VERSION "Version"

NS_ :

BS_:

BU_: CCU IBCS IXCU RBM EPS ADC IBCS_IXCU IDU Tester CCURT2 RT2_C3 OTAWL ZCUF ZCUL ZCUR ZCUT IPS DCU NIDU RLBMS CBM WACUFL IDC IID VIU CCURT1 RT1_C0 RT1_C1 AVAS FLLCM FRLCM RLLCMA RRLCMA RLLCMB RRLCMB LBMS LBMSAD MFS FCP ITS BCB DCDC PCU EOP DCU2 BMS TMC SRS ECS CD AMP WHUD IMR FIMR FAPA FLR FRR RLR RRR IFC PAS INU SBM WCM ETC TBOX TBOX2 DSM FLPDM FRPDM RLPDM RRPDM HVSMR SCMRL SCMRR EBU EPB PCS V2XOBU EVCC VDC ADM PLGM FBLCM RLISD RRISD RCP RFR WCMFR SCMR TFOAR TROAR HVSPRL HVSPRR

BO_ 371 ADC_13_B: 64 ADC
 SG_ ADC_13_B_CRC : 7|16@0+ (1,0) [0|65535] ""  CCU,CCURT1,CCURT2,RT1_C1,VDC,EPS,IBCS,ECS,IXCU
 SG_ ADC_13_B_Counter : 23|8@0+ (1,0) [0|255] ""  CCU,CCURT1,CCURT2,RT1_C1,VDC,EPS,IBCS,ECS,IXCU
 SG_ ADC_DycEscTarTq : 63|16@0+ (1,-32768) [-32768|32767] "Nm"  IBCS,IXCU
 SG_ ADC_DycEscTarTqfactor : 79|8@0+ (0.01,0) [0|1] ""  IBCS,IXCU
 SG_ ADC_SteerTqReq : 87|12@0+ (0.01,-20) [-20|20] "Nm"  EPS
 SG_ ADC_SteerTqSt : 157|2@0+ (1,0) [0|3] ""  EPS
 SG_ ADC_SteerTqAvl : 153|1@0+ (1,0) [0|1] ""  EPS
 SG_ ADC_DycEscTarTqVld : 166|1@0+ (1,0) [0|1] ""  IBCS,IXCU
 SG_ ADC_DycEscTarTqEna : 167|1@0+ (1,0) [0|1] ""  IBCS,IXCU
 SG_ ADC_TotalRefTorque : 31|16@0+ (1,-32768) [-32768|32767] "Nm"  CCU,CCURT1,CCURT2,RT1_C1,VDC
 SG_ ADC_MotTarSpd : 47|16@0+ (1,-32768) [-32768|32767] "rpm"  CCU,CCURT1,CCURT2,RT1_C1,VDC
 SG_ ADC_LimTqFactorK : 91|10@0+ (0.001,0) [0|1] ""  CCU,CCURT1,CCURT2,RT1_C1,VDC
 SG_ ADC_MotTqLimMin : 97|9@0+ (25,-6375) [-6375|6400] "Nm"  CCU,CCURT1,CCURT2,RT1_C1,VDC
 SG_ ADC_MotTqLimMax : 104|9@0+ (25,-6375) [-6375|6400] "Nm"  CCU,CCURT1,CCURT2,RT1_C1,VDC
 SG_ ADC_MotTqRateLimMin : 127|9@0+ (50,-12750) [-12750|12800] "Nm/s"  CCU,CCURT1,CCURT2,RT1_C1,VDC
 SG_ ADC_MotTqRateLimMax : 134|9@0+ (50,-12750) [-12750|12800] "Nm/s"  CCU,CCURT1,CCURT2,RT1_C1,VDC
 SG_ ADC_TqUnloadRate : 141|9@0+ (50,-12750) [-12750|12800] "Nm/s"  CCU,CCURT1,CCURT2,RT1_C1,VDC
 SG_ ADC_MotCtrlTar : 148|3@0+ (1,0) [0|7] ""  CCU,CCURT1,CCURT2,RT1_C1,VDC
 SG_ ADC_MotTarMod : 145|2@0+ (1,0) [0|3] ""  CCU,CCURT1,CCURT2,RT1_C1,VDC
 SG_ ADC_DrvTarTqMod : 159|2@0+ (1,0) [0|3] ""  CCU,CCURT1,CCURT2,RT1_C1,VDC,EPB
 SG_ ADC_TqEvsSteerReq : 152|1@0+ (1,0) [0|1] ""  CCU,CCURT1,CCURT2,EPS
 SG_ ADC_RapidRespEna : 154|1@0+ (1,0) [0|1] ""  CCU,CCURT1,CCURT2,RT1_C1,VDC
 SG_ ADC_LimTqEnable : 155|1@0+ (1,0) [0|1] ""  CCU,CCURT1,CCURT2,RT1_C1,VDC
 SG_ ADC_MotSpdCtrlEna : 163|1@0+ (1,0) [0|1] ""  CCU,CCURT1,CCURT2,RT1_C1,VDC
 SG_ ADC_TqUnloadEna : 164|1@0+ (1,0) [0|1] ""  CCU,CCURT1,CCURT2,RT1_C1,VDC
 SG_ ADC_MotTarSpdSvValid : 165|1@0+ (1,0) [0|1] ""  CCU,CCURT1,CCURT2,RT1_C1,VDC
 SG_ ADC_RoadTyp : 162|3@0+ (1,0) [0|7] ""  CCU,CCURT1,CCURT2,EPS,ECS
 SG_ ADC_LeWhlLgtDst : 175|12@0+ (0.01,0) [0|30] "m"  CCU,CCURT1,CCURT2,EPS,ECS
 SG_ ADC_LeWhlRoadHei : 179|12@0+ (0.001,-0.5) [-0.5|0.523] "m"  CCU,CCURT1,CCURT2,EPS,ECS
 SG_ ADC_RiWhlLgtDst : 199|12@0+ (0.01,0) [0|30] "m"  CCU,CCURT1,CCURT2,EPS,ECS
 SG_ ADC_RiWhlRoadHei : 203|12@0+ (0.001,-0.5) [-0.5|0.523] "m"  CCU,CCURT1,CCURT2,EPS,ECS
 SG_ ADC_RiWhlRoadFeature : 223|5@0+ (1,0) [0|15] ""  CCU,CCURT1,CCURT2,EPS,ECS
 SG_ ADC_SuspensionStatus : 218|3@0+ (1,0) [0|7] ""  CCU,CCURT1,CCURT2,EPS,ECS
 SG_ ADC_LeWhlRoadSts : 231|2@0+ (1,0) [0|3] ""  CCU,CCURT1,CCURT2,EPS,ECS
 SG_ ADC_LeWhlRoadFeature : 229|4@0+ (1,0) [0|15] ""  CCU,CCURT1,CCURT2,EPS,ECS
 SG_ ADC_RiWhlRoadSts : 225|2@0+ (1,0) [0|3] ""  CCU,CCURT1,CCURT2,EPS,ECS
 SG_ ADC_CDCCtrlEnable : 239|1@0+ (1,0) [0|1] ""  CCU,CCURT1,CCURT2,EPS,ECS
 SG_ ADC_RoadInfoAvl : 238|1@0+ (1,0) [0|1] ""  CCU,CCURT1,CCURT2,EPS,ECS
 SG_ ADC_RoadFeatureDetFalutSts : 295|1@0+ (1,0) [0|1] ""  CCU,CCURT1,CCURT2
 SG_ ADC_RoadFeatureDetWorkSts : 247|2@0+ (1,0) [0|3] ""  CCU,CCURT1,CCURT2
 SG_ ADC_LeWhlRoadFeature2 : 251|4@0+ (1,0) [0|15] ""  CCU,CCURT1,CCURT2
 SG_ ADC_LeWhlRoadFeature3 : 255|4@0+ (1,0) [0|15] ""  CCU,CCURT1,CCURT2
 SG_ ADC_RiWhlRoadFeature2 : 259|4@0+ (1,0) [0|15] ""  CCU,CCURT1,CCURT2
 SG_ ADC_RiWhlRoadFeature3 : 263|4@0+ (1,0) [0|15] ""  CCU,CCURT1,CCURT2
 SG_ ADC_LeWhlRoadHei2 : 271|3@0+ (1,0) [0|7] ""  CCU,CCURT1,CCURT2
 SG_ ADC_LeWhlRoadHei3 : 268|3@0+ (1,0) [0|7] ""  CCU,CCURT1,CCURT2
 SG_ ADC_RiWhlRoadHei2 : 265|3@0+ (1,0) [0|7] ""  CCU,CCURT1,CCURT2
 SG_ ADC_RiWhlRoadHei3 : 278|3@0+ (1,0) [0|7] ""  CCU,CCURT1,CCURT2
 SG_ ADC_LeWhlLgtDst2 : 237|6@0+ (0.25,0) [0|15] "m"  CCU,CCURT1,CCURT2
 SG_ ADC_LeWhlLgtDst3 : 245|6@0+ (0.25,0) [0|15] "m"  CCU,CCURT1,CCURT2
 SG_ ADC_RiWhlLgtDst2 : 275|6@0+ (0.25,0) [0|15] "m"  CCU,CCURT1,CCURT2
 SG_ ADC_RiWhlLgtDst3 : 285|6@0+ (0.25,0) [0|15] "m"  CCU,CCURT1,CCURT2
 SG_ ADC_AS_SuspHeiAdj : 290|3@0+ (1,0) [0|7] ""  CCU,CCURT1,CCURT2
 SG_ ADC_AS_SuspHeiAdjVld : 291|1@0+ (1,0) [0|1] ""  CCU,CCURT1,CCURT2
 SG_ ADC_AS_SusStfnAdj : 300|3@0+ (1,0) [0|7] ""  CCU,CCURT1,CCURT2
 SG_ ADC_AS_SusStfnAdjVld : 292|1@0+ (1,0) [0|1] ""  CCU,CCURT1,CCURT2
 SG_ ADC_CDCModReq : 303|3@0+ (1,0) [0|7] ""  CCU,CCURT1,CCURT2
 SG_ ADC_CDCModReqVld : 294|1@0+ (1,0) [0|1] ""  CCU,CCURT1,CCURT2
 SG_ ADC_UrgentSteerFlg : 317|1@0+ (1,0) [0|1] ""  CCU
 SG_ ADC_OneMotorCtrlEna : 316|2@0+ (1,0) [0|3] ""  CCU
 SG_ ADC_MotorCtrlTqWhlRL : 327|16@0+ (1,-32768) [-32768|32767] "Nm"  CCU
 SG_ ADC_MotorCtrlTqWhlRR : 343|16@0+ (1,-32768) [-32768|32767] "Nm"  CCU
 SG_ ADC_SteerGainLevelTqCtrl : 359|8@0+ (1,0) [0|254] "%"  CCU,EPS
 SG_ ADC_MotorCtrlTqWhlFR : 383|16@0+ (1,-32768) [-32768|32767] "Nm"  CCU
 SG_ ADC_MotorCtrlTqWhlFL : 431|16@0+ (1,-32768) [-32768|32767] "Nm"  CCU

BO_ 422 VCU_1_B: 64 CCU
 SG_ VCU_1_B_CRC : 7|16@0+ (1,0) [0|65535] ""  ADC
 SG_ VCU_1_B_Counter : 23|8@0+ (1,0) [0|255] ""  ADC
 SG_ VCU_AccButtInfo_B : 31|8@0+ (1,0) [0|255] ""  ADC
 SG_ VCU_LateralAssistBtnInfo_B : 39|1@0+ (1,0) [0|1] ""  ADC
 SG_ VCU_LateralAssistBtnInfoVD_B : 38|1@0+ (1,0) [0|1] ""  ADC
 SG_ VCU_AccMasterCanError_B : 37|1@0+ (1,0) [0|1] ""  ADC
 SG_ VCU_IFCFailureSt_B : 36|1@0+ (1,0) [0|1] ""  ADC
 SG_ VCU_VehDrvMod_B : 35|3@0+ (1,0) [0|7] ""  ADC
 SG_ VCU_VehRdySt_B : 32|1@0+ (1,0) [0|1] ""  ADC
 SG_ VCU_GearLvl_B : 47|4@0+ (1,0) [0|15] ""  ADC
 SG_ VCU_RecpTorqVD_B : 43|1@0+ (1,0) [0|1] ""  ADC
 SG_ VCU_RecpTorq_B : 42|11@0+ (2,0) [0|4000] "Nm"  ADC
 SG_ VCU_BrkPedPst_B : 63|8@0+ (0.392,0) [0|99.96] "%"  ADC
 SG_ VCU_BrkPedPstVD_B : 71|1@0+ (1,0) [0|1] ""  ADC
 SG_ VCU_CrntGearLvlVD_B : 70|1@0+ (1,0) [0|1] ""  ADC
 SG_ VCU_CrntGearLvl_B : 69|3@0+ (1,0) [0|7] ""  ADC
 SG_ VCU_ACCLimitOperatingSt_B : 66|1@0+ (1,0) [0|1] ""  ADC
 SG_ VCU_ACCMaxRecpDecelVD_B : 65|1@0+ (1,0) [0|1] ""  ADC
 SG_ VCU_ACCMaxRecpDecel_B : 79|8@0+ (0.05,-5) [-5|7.75] "m/s2"  ADC
 SG_ VCU_ActVehWheelTorq_B : 87|14@0+ (1,0) [0|10000] "Nm"  ADC
 SG_ VCU_ACCmaxSpdLimit_B : 89|4@0+ (1,0) [0|15] ""  ADC
 SG_ VCU_VehWheelTorqMax_B : 101|14@0+ (1,0) [0|10000] "Nm"  ADC
 SG_ VCU_GasPedalActPstforMRRVD_B : 119|1@0+ (1,0) [0|1] ""  ADC
 SG_ VCU_AccElecECFail_B : 118|1@0+ (1,0) [0|1] ""  ADC
 SG_ VCU_AccDriverOrvd_B : 117|1@0+ (1,0) [0|1] ""  ADC
 SG_ VCU_APAAvailable_B : 116|1@0+ (1,0) [0|1] ""  ADC
 SG_ VCU_APA_Resp_B : 115|1@0+ (1,0) [0|1] ""  ADC
 SG_ VCU_GasPedalActPstforMRR_B : 127|8@0+ (0.392,0) [0|99.96] "%"  ADC
 SG_ VCU_AccPedalActPst_B : 135|8@0+ (0.392,0) [0|99.96] "%"  ADC
 SG_ VCU_BrkPedalSt_B : 143|1@0+ (1,0) [0|1] ""  ADC
 SG_ VCU_BrkPedalStVD_B : 142|1@0+ (1,0) [0|1] ""  ADC
 SG_ VCU_AccPedalActPstVD_B : 141|1@0+ (1,0) [0|1] ""  ADC
 SG_ VCU_AccTMCFail_B : 140|1@0+ (1,0) [0|1] ""  ADC

BO_ 619 CCU_EPB_2: 32 CCU
 SG_ EPB_FailSt_L : 39|1@0+ (1,0) [0|1] ""  ZCUT,RBM,IBCS,ADC,FAPA,VIU
 SG_ EPB_ExtAvailable_L : 47|2@0+ (1,0) [0|3] ""  ZCUT,RBM,IBCS,ADC,FAPA,VIU
 SG_ EPB_ActuatorSt_L : 107|4@0+ (1,0) [0|15] ""  ZCUT,RBM,IBCS,ADC,FAPA,VIU

BO_ 1174 ADC_BigData: 64 ADC
 SG_ ADC_BigData : 7|512@0+ (1,0) [0|1] ""  CCU

BO_ 728 CCU_ECS_1: 64 CCU
 SG_ ECS_1_CRC : 7|16@0+ (1,0) [0|65535] ""  ADC
 SG_ ECS_1_Counter : 23|8@0+ (1,0) [0|255] ""  ADC
 SG_ SDC_SolenoidErrorStRR : 31|2@0+ (1,0) [0|3] ""  ADC
 SG_ CDC_ADCCtrlAvl : 38|1@0+ (1,0) [0|1] ""  ADC
 SG_ CDC_ADCCtrlRespSts : 39|1@0+ (1,0) [0|1] ""  ADC
 SG_ SDC_ExternalReqMode : 43|3@0+ (1,0) [0|7] ""  ADC
 SG_ SDC_CurrentDamperMode : 258|3@0+ (1,0) [0|7] ""  ADC
 SG_ SDC_WarningLampReq : 259|1@0+ (1,0) [0|1] ""  ADC
 SG_ SDC_ProhibitChangingMode : 260|1@0+ (1,0) [0|1] ""  ADC
 SG_ SDC_BodyAccErrorStFL : 261|1@0+ (1,0) [0|1] ""  ADC
 SG_ SDC_BodyAccErrorStFR : 262|1@0+ (1,0) [0|1] ""  ADC
 SG_ SDC_BodyAccErrorStRr : 263|1@0+ (1,0) [0|1] ""  ADC
 SG_ SDC_WheelAccErrorStFL : 264|1@0+ (1,0) [0|1] ""  ADC
 SG_ SDC_WheelAccErrorStFR : 265|1@0+ (1,0) [0|1] ""  ADC
 SG_ SDC_SolenoidWorkSt : 267|2@0+ (1,0) [0|3] ""  ADC
 SG_ CDC_FailureSt : 279|8@0+ (1,0) [0|255] ""  ADC
 SG_ CDC_ADCModState : 287|3@0+ (1,0) [0|7] ""  ADC

BO_ 459 CCU_ECS_2: 64 CCU
 SG_ ECS_2_CRC : 7|16@0+ (1,0) [0|65535] ""  ADC,FAPA,IFC
 SG_ ECS_2_Counter : 23|8@0+ (1,0) [0|255] ""  ADC,FAPA,IFC
 SG_ AS_SuspHeightFL : 31|12@0+ (0.1,-150) [-150|150] "mm"  ADC,FAPA,IFC
 SG_ AS_SuspHeightFR : 35|12@0+ (0.1,-150) [-150|150] "mm"  ADC,FAPA,IFC
 SG_ AS_SuspHeightRL : 55|12@0+ (0.1,-150) [-150|150] "mm"  ADC,FAPA,IFC
 SG_ AS_SuspHeightRR : 59|12@0+ (0.1,-150) [-150|150] "mm"  ADC,FAPA,IFC
 SG_ AS_SuspHeightFLVD : 72|1@0+ (1,0) [0|1] ""  ADC,FAPA,IFC
 SG_ AS_SuspHeightFRVD : 73|1@0+ (1,0) [0|1] ""  ADC,FAPA,IFC
 SG_ AS_SuspHeightRLVD : 74|1@0+ (1,0) [0|1] ""  ADC,FAPA,IFC
 SG_ AS_SuspHeightRRVD : 75|1@0+ (1,0) [0|1] ""  ADC,FAPA,IFC
 SG_ AS_SuspHeightSensorFLSt : 76|1@0+ (1,0) [0|1] ""  ADC,FAPA,IFC
 SG_ AS_SuspHeightSensorFRSt : 77|1@0+ (1,0) [0|1] ""  ADC,FAPA,IFC
 SG_ AS_SuspHeightSensorRLSt : 78|1@0+ (1,0) [0|1] ""  ADC,FAPA,IFC
 SG_ AS_SuspHeightSensoRRSt : 79|1@0+ (1,0) [0|1] ""  ADC,FAPA,IFC
 SG_ AS_MaintanceModeSt : 97|2@0+ (1,0) [0|3] ""  ADC,FAPA,IFC
 SG_ ECS_AVDCReqModeAvailable : 113|1@0+ (1,0) [0|1] ""  ADC,FAPA,IFC
 SG_ ECS_AVDCReqMode : 116|3@0+ (1,0) [0|7] ""  ADC,FAPA,IFC
 SG_ AS_FrontAxleSuspSt : 112|2@0+ (1,0) [0|3] ""  ADC,FAPA,IFC
 SG_ AS_RearAxleSuspSt : 126|2@0+ (1,0) [0|3] ""  ADC,FAPA,IFC
 SG_ AS_HeightWarningSt : 124|3@0+ (1,0) [0|7] ""  ADC,FAPA,IFC
 SG_ AS_CurrentLevel : 131|4@0+ (1,0) [0|15] ""  ADC,FAPA,IFC
 SG_ AS_TargetLevel : 135|4@0+ (1,0) [0|15] ""  ADC,FAPA
 SG_ AS_ASMode : 138|3@0+ (1,0) [0|7] ""  ADC,FAPA,IFC
 SG_ AS_SysFaultSt : 141|3@0+ (1,0) [0|7] ""  ADC,FAPA,IFC
 SG_ AS_OverHeatingSt : 143|2@0+ (1,0) [0|3] ""  ADC,FAPA
 SG_ AS_SysOperationSt : 159|4@0+ (1,0) [0|15] ""  ADC,FAPA,IFC
 SG_ AS_OverLoadSt : 147|1@0+ (1,0) [0|1] ""  ADC,FAPA
 SG_ AS_OverTorsionSt : 148|1@0+ (1,0) [0|1] ""  ADC,FAPA
 SG_ AS_ManufacModeSt : 150|2@0+ (1,0) [0|3] ""  ADC,FAPA
 SG_ AS_ASIndividualMode : 155|3@0+ (1,0) [0|7] ""  ADC
 SG_ AS_ADCStfnCtrlAvl : 151|1@0+ (1,0) [0|1] ""  ADC,FAPA
 SG_ AS_ADCStfnState : 146|3@0+ (1,0) [0|7] ""  ADC,FAPA

BO_ 359 BCS_1_B: 64 IBCS_IXCU
 SG_ BCS_1_B_CRC : 7|16@0+ (1,0) [0|65535] ""  CCU,CCURT1,RT1_C1,VDC,EPS,EPB,ADC
 SG_ BCS_1_B_Counter : 23|8@0+ (1,0) [0|255] ""  CCU,CCURT1,RT1_C1,VDC,EPS,EPB,ADC
 SG_ BCS_FLWheelSpd_B : 31|13@0+ (0.05625,0) [0|240] "km/h"  EPS,EPB,ADC
 SG_ BCS_FLWheelSpdVD_B : 34|1@0+ (1,0) [0|1] ""  EPS,EPB,ADC
 SG_ BCS_FLWheelRotatedDirection_B : 33|1@0+ (1,0) [0|1] ""  EPB,ADC
 SG_ BCS_FLWheelRotatedDirectionVD_B : 32|1@0+ (1,0) [0|1] ""  EPB,ADC
 SG_ BCS_FRWheelSpd_B : 47|13@0+ (0.05625,0) [0|240] "km/h"  EPS,EPB,ADC
 SG_ BCS_FRWheelSpdVD_B : 50|1@0+ (1,0) [0|1] ""  EPS,EPB,ADC
 SG_ BCS_FRWheelRotatedDirection_B : 49|1@0+ (1,0) [0|1] ""  EPB,ADC
 SG_ BCS_FRWheelRotatedDirectionVD_B : 48|1@0+ (1,0) [0|1] ""  EPB,ADC
 SG_ BCS_RLWheelSpd_B : 63|13@0+ (0.05625,0) [0|240] "km/h"  EPS,EPB,ADC
 SG_ BCS_RLWheelSpdVD_B : 66|1@0+ (1,0) [0|1] ""  EPS,EPB,ADC
 SG_ BCS_RLWheelRotatedDirection_B : 65|1@0+ (1,0) [0|1] ""  EPB,ADC
 SG_ BCS_RLWheelRotatedDirectionVD_B : 64|1@0+ (1,0) [0|1] ""  EPB,ADC
 SG_ BCS_RRWheelSpd_B : 79|13@0+ (0.05625,0) [0|240] "km/h"  EPS,EPB,ADC
 SG_ BCS_RRWheelSpdVD_B : 82|1@0+ (1,0) [0|1] ""  EPS,EPB,ADC
 SG_ BCS_RRWheelRotatedDirection_B : 81|1@0+ (1,0) [0|1] ""  EPB,ADC
 SG_ BCS_RRWheelRotatedDirectionVD_B : 80|1@0+ (1,0) [0|1] ""  EPB,ADC
 SG_ BCS_HHCCtrlSt_B : 95|1@0+ (1,0) [0|1] ""  ADC
 SG_ BCS_HDCCtrlSt_B : 93|2@0+ (1,0) [0|3] ""  ADC
 SG_ BCS_HDCErrSt_B : 91|1@0+ (1,0) [0|1] ""  ADC
 SG_ BCS_FLWheelSpdEdgesSum_B : 103|12@0+ (1,0) [0|4095] ""  EPB,ADC
 SG_ BCS_FRWheelSpdEdgesSum_B : 107|12@0+ (1,0) [0|4095] ""  EPB,ADC
 SG_ BCS_RLWheelSpdEdgesSum_B : 127|12@0+ (1,0) [0|4095] ""  EPB,ADC
 SG_ BCS_RRWheelSpdEdgesSum_B : 131|12@0+ (1,0) [0|4095] ""  EPB,ADC
 SG_ BCS_FLWheelSpdEdgesSumVD_B : 151|1@0+ (1,0) [0|1] ""  EPB,ADC
 SG_ BCS_FRWheelSpdEdgesSumVD_B : 150|1@0+ (1,0) [0|1] ""  EPB,ADC
 SG_ BCS_RLWheelSpdEdgesSumVD_B : 149|1@0+ (1,0) [0|1] ""  EPB,ADC
 SG_ BCS_RRWheelSpdEdgesSumVD_B : 148|1@0+ (1,0) [0|1] ""  EPB,ADC
 SG_ BCS_FLWheelRotatedDirectionAPA_B : 147|2@0+ (1,0) [0|3] ""  EPB,ADC
 SG_ BCS_FRWheelRotatedDirectionAPA_B : 145|2@0+ (1,0) [0|3] ""  EPB,ADC
 SG_ BCS_RLWheelRotatedDirectionAPA_B : 159|2@0+ (1,0) [0|3] ""  EPB,ADC
 SG_ BCS_RRWheelRotatedDirectionAPA_B : 157|2@0+ (1,0) [0|3] ""  EPB,ADC
 SG_ BCS_ParkingReqToEPB_B : 155|2@0+ (1,0) [0|3] ""  EPB,ADC
 SG_ BCS_VDCOff_B : 153|1@0+ (1,0) [0|1] ""  ADC
 SG_ BCS_AVHSt_B : 152|1@0+ (1,0) [0|1] ""  EPB,ADC
 SG_ BCS_AVHAvailable_B : 166|1@0+ (1,0) [0|1] ""  EPB,ADC
 SG_ BCS_TCSOff_B : 165|1@0+ (1,0) [0|1] ""  ADC
 SG_ BCS_BrakeOverHeat_B : 160|1@0+ (1,0) [0|1] ""  ADC
 SG_ BCS_ABAactive_B : 175|1@0+ (1,0) [0|1] ""  ADC
 SG_ BCS_ABAavailable_B : 174|1@0+ (1,0) [0|1] ""  ADC
 SG_ BCS_ABPActive_B : 173|1@0+ (1,0) [0|1] ""  ADC
 SG_ BCS_ABPAvailable_B : 172|1@0+ (1,0) [0|1] ""  ADC
 SG_ BCS_AEBActive_B : 171|1@0+ (1,0) [0|1] ""  CCU,CCURT1,RT1_C1,VDC,ADC
 SG_ BCS_AEBAvailable_B : 170|1@0+ (1,0) [0|1] ""  ADC
 SG_ BCS_AWBActive_B : 169|1@0+ (1,0) [0|1] ""  ADC
 SG_ BCS_AWBAvailable_B : 168|1@0+ (1,0) [0|1] ""  ADC
 SG_ BCS_AVHStandby_B : 167|1@0+ (1,0) [0|1] ""  EPB,ADC
 SG_ BCS_AEBBAActive_B : 178|1@0+ (1,0) [0|1] ""  ADC
 SG_ BCS_VehicleStandStillSt_B : 180|2@0+ (1,0) [0|3] ""  EPB,ADC
 SG_ IPB_InputRodStroke_B : 363|10@0+ (0.05,-5) [-5|46.15] "mm"  ADC
 SG_ IPB_PlungerPressureSt_B : 376|1@0+ (1,0) [0|1] ""  EPB,ADC
 SG_ BCS_RAEBAvailable_B : 377|1@0+ (1,0) [0|1] ""  ADC
 SG_ BCS_RAEBActive_B : 378|1@0+ (1,0) [0|1] ""  ADC
 SG_ IPB_InputRodStrokeSt_B : 379|1@0+ (1,0) [0|1] ""  ADC
 SG_ IPB_PlungerPressure_B : 391|12@0+ (0.3,-5) [-5|301.9] "bar"  EPB,ADC

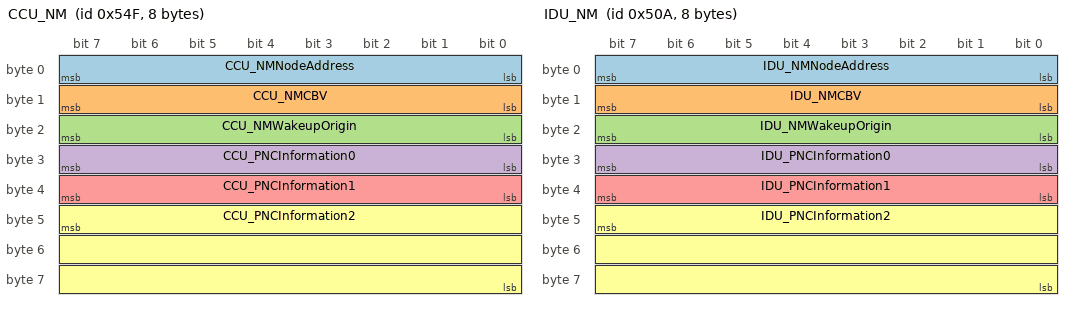
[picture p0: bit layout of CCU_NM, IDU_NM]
BO_ 1359 CCU_NM: 8 CCU
 SG_ CCU_NMNodeAddress : 7|8@0+ (1,0) [0|255] ""  ZCUF,ZCUL,ZCUR,ZCUT,ADM,LBMS,MFS,IDU,ITS,IPS,PCU,DCU,DCU2,NIDU,BMS,EVCC,TMC,RBM,IBCS,ECS,RLBMS,EPB,IXCU,WACUFL,IDC,IID,AMP,ADC,FAPA,VIU,IFC,TBOX,FLPDM,FRPDM,RLPDM,RRPDM,PLGM
 SG_ CCU_NMCBV : 15|8@0+ (1,0) [0|0] ""  ZCUF,ZCUL,ZCUR,ZCUT,ADM,LBMS,MFS,IDU,ITS,IPS,DCDC,PCU,DCU,DCU2,NIDU,BMS,EVCC,TMC,RBM,IBCS,ECS,RLBMS,EPB,IXCU,WACUFL,IDC,IID,AMP,ADC,FAPA,VIU,IFC,TBOX,FLPDM,FRPDM,RLPDM,RRPDM,PLGM
 SG_ CCU_NMWakeupOrigin : 23|8@0+ (1,0) [0|255] ""  ADM,LBMS,IDU,DCU2,TMC,IXCU,WACUFL,IID,AMP,ADC,FAPA,VIU,IFC,FLPDM,FRPDM,RLPDM,RRPDM,PLGM
 SG_ CCU_PNCInformation0 : 31|8@0+ (1,0) [0|255] ""  ZCUF,ZCUL,ZCUR,ZCUT,ADM,LBMS,MFS,IDU,ITS,IPS,DCDC,PCU,DCU,DCU2,NIDU,BMS,EVCC,TMC,RBM,IBCS,ECS,RLBMS,EPB,IXCU,WACUFL,IDC,IID,AMP,ADC,FAPA,VIU,IFC,TBOX,FLPDM,FRPDM,RLPDM,RRPDM,PLGM
 SG_ CCU_PNCInformation1 : 39|8@0+ (1,0) [0|0] ""  ZCUF,ZCUL,ZCUR,ZCUT,ADM,LBMS,MFS,IDU,ITS,IPS,PCU,DCU,DCU2,NIDU,BMS,EVCC,TMC,RBM,IBCS,ECS,RLBMS,EPB,IXCU,WACUFL,IDC,IID,AMP,ADC,FAPA,VIU,IFC,TBOX,FLPDM,FRPDM,RLPDM,RRPDM,PLGM
 SG_ CCU_PNCInformation2 : 47|24@0+ (1,0) [0|0] ""  ZCUF,ZCUL,ZCUR,ZCUT,ADM,LBMS,MFS,IDU,ITS,IPS,PCU,DCU,DCU2,NIDU,BMS,EVCC,TMC,RBM,IBCS,ECS,RLBMS,EPB,IXCU,WACUFL,IDC,IID,AMP,ADC,FAPA,VIU,IFC,TBOX,FLPDM,FRPDM,RLPDM,RRPDM,PLGM

BO_ 1290 IDU_NM: 8 IDU
 SG_ IDU_NMNodeAddress : 7|8@0+ (1,0) [0|255] ""  CCU,CCURT1,MFS,RBM,IBCS,ADC,VIU,HVSMR
 SG_ IDU_NMCBV : 15|8@0+ (1,0) [0|0] ""  CCU,CCURT1,MFS,RBM,IBCS,ADC,VIU,HVSMR
 SG_ IDU_NMWakeupOrigin : 23|8@0+ (1,0) [0|255] ""  CCU,CCURT1,MFS,RBM,IBCS,ADC,VIU,HVSMR
 SG_ IDU_PNCInformation0 : 31|8@0+ (1,0) [0|255] ""  CCU,CCURT1,MFS,RBM,IBCS,ADC,VIU,HVSMR
 SG_ IDU_PNCInformation1 : 39|8@0+ (1,0) [0|0] ""  CCU,CCURT1,MFS,RBM,IBCS,ADC,VIU,HVSMR
 SG_ IDU_PNCInformation2 : 47|24@0+ (1,0) [0|0] ""  CCU,CCURT1,MFS,RBM,IBCS,ADC,VIU,HVSMR

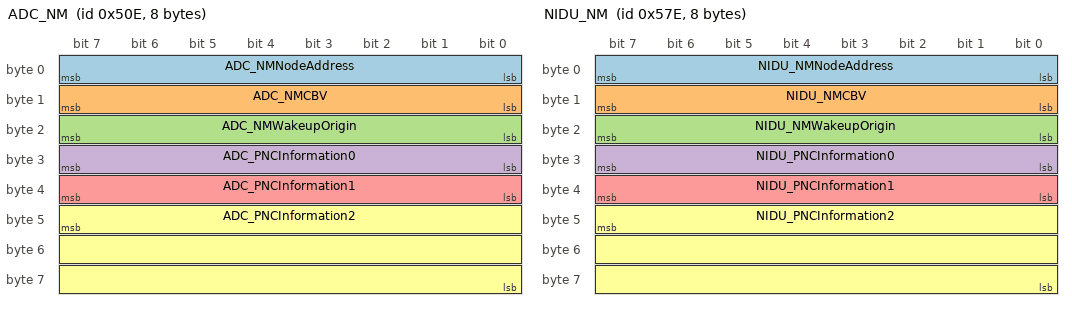
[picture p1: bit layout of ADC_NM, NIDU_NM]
BO_ 1294 ADC_NM: 8 ADC
 SG_ ADC_NMNodeAddress : 7|8@0+ (1,0) [0|255] ""  CCU,RBM,IBCS
 SG_ ADC_NMCBV : 15|8@0+ (1,0) [0|0] ""  CCU,RBM,IBCS
 SG_ ADC_NMWakeupOrigin : 23|8@0+ (1,0) [0|255] ""  CCU,RBM,IBCS
 SG_ ADC_PNCInformation0 : 31|8@0+ (1,0) [0|255] ""  CCU,RBM,IBCS
 SG_ ADC_PNCInformation1 : 39|8@0+ (1,0) [0|0] ""  CCU,RBM,IBCS
 SG_ ADC_PNCInformation2 : 47|24@0+ (1,0) [0|0] ""  CCU,RBM,IBCS

BO_ 1406 NIDU_NM: 8 IXCU
 SG_ NIDU_NMNodeAddress : 7|8@0+ (1,0) [0|255] ""  CCU,CCURT1,EPS,WACUFL,ADC
 SG_ NIDU_NMCBV : 15|8@0+ (1,0) [0|0] ""  CCU,CCURT1,EPS,WACUFL,ADC
 SG_ NIDU_NMWakeupOrigin : 23|8@0+ (1,0) [0|255] ""  CCU,CCURT1,EPS,WACUFL,ADC
 SG_ NIDU_PNCInformation0 : 31|8@0+ (1,0) [0|255] ""  CCU,CCURT1,EPS,WACUFL,ADC
 SG_ NIDU_PNCInformation1 : 39|8@0+ (1,0) [0|0] ""  CCU,CCURT1,EPS,WACUFL,ADC
 SG_ NIDU_PNCInformation2 : 47|24@0+ (1,0) [0|0] ""  CCU,CCURT1,EPS,WACUFL,ADC

BO_ 2015 Fun_Diag_Rx: 64 Tester
 SG_ Fun_Diag_Request : 7|512@0+ (1,0) [0|0] ""  ZCUF,ZCUL,ZCUR,ZCUT,AVAS,FBLCM,FLLCM,FRLCM,RLLCMA,RRLCMA,RLLCMB,RRLCMB,RLISD,RRISD,LBMS,LBMSAD,MFS,FCP,RCP,VDC,ITS,IPS,DCDC,PCU,EOP,DCU,DCU2,NIDU,BMS,EVCC,SRS,EPS,RBM,IBCS,EBU,RLBMS,EPB,IXCU,WACUFL,IDC,IID,CD,AMP,WHUD,IMR,FIMR,ADC,FAPA,VIU,IFC,PAS,PCS,INU,RFR,SBM,WCM,WCMFR,ETC,TBOX,TBOX2,DSM,FLPDM,FRPDM,RLPDM,RRPDM,SCMR,SCMRL,SCMRR,TFOAR,TROAR,HVSPRL,HVSPRR

CM_ SG_ 371 ADC_13_B_CRC "E2E Profile 5 CRC";
CM_ SG_ 371 ADC_13_B_Counter "E2E Profile 5 Counter";
CM_ SG_ 371 ADC_DycEscTarTq "The total target torque of the DYC(Direct  yaw moment control).";
CM_ SG_ 371 ADC_DycEscTarTqfactor "Partition coefficient of  total target torque of the DYC:front axle/total";
CM_ SG_ 371 ADC_SteerTqReq "Steering torque request value";
CM_ SG_ 371 ADC_SteerTqSt "Steering torque request  enable state";
CM_ SG_ 371 ADC_SteerTqAvl "Steering torque request avaliable state";
CM_ SG_ 371 ADC_DycEscTarTqVld "The validity of total target torque of the DYC.";
CM_ SG_ 371 ADC_DycEscTarTqEna "The enable status  of total target torque of the DYC.";
CM_ SG_ 371 ADC_TotalRefTorque "ADAS total  torque request";
CM_ SG_ 371 ADC_MotTarSpd "target motor speed";
CM_ SG_ 371 ADC_LimTqFactorK "Limit torque request factor";
CM_ SG_ 371 ADC_MotTqLimMin "Wheel torque lower limit";
CM_ SG_ 371 ADC_MotTqLimMax "Wheel torque upper limit";
CM_ SG_ 371 ADC_MotTqRateLimMin "Wheel torque rate lower limit";
CM_ SG_ 371 ADC_MotTqRateLimMax "Wheel torque rate upper limit";
CM_ SG_ 371 ADC_TqUnloadRate "Unload torque rate";
CM_ SG_ 371 ADC_MotCtrlTar "Target control motor";
CM_ SG_ 371 ADC_MotTarMod "Target motor working mode";
CM_ SG_ 371 ADC_DrvTarTqMod "Drive torque mode";
CM_ SG_ 371 ADC_TqEvsSteerReq "Emergency Collision avoidance steering mode request";
CM_ SG_ 371 ADC_RapidRespEna "Rapid response mode enable flag";
CM_ SG_ 371 ADC_LimTqEnable "Limit torque request enable flag";
CM_ SG_ 371 ADC_MotSpdCtrlEna "Speed mode control enable flag";
CM_ SG_ 371 ADC_TqUnloadEna "Unload torque request enable flag";
CM_ SG_ 371 ADC_MotTarSpdSvValid "Speed mode control validity";
CM_ SG_ 371 ADC_RoadTyp "Pavement condition type";
CM_ SG_ 371 ADC_LeWhlLgtDst "The distance from the projection point of the left front wheel center on the ground to the edge of the road feature area";
CM_ SG_ 371 ADC_LeWhlRoadHei "Left front wheel front feature road bump height (or dip depth)";
CM_ SG_ 371 ADC_RiWhlLgtDst "The distance from the projection point of the right front wheel center on the ground to the edge of the road feature area";
CM_ SG_ 371 ADC_RiWhlRoadHei "Right front wheel front feature road bump height (or dip depth)";
CM_ SG_ 371 ADC_RiWhlRoadFeature "Right wheel single road feature type";
CM_ SG_ 371 ADC_SuspensionStatus "ADS air suspension status request";
CM_ SG_ 371 ADC_LeWhlRoadSts "Left wheel pavement uneven (concave/convex) condition";
CM_ SG_ 371 ADC_LeWhlRoadFeature "Left-wheel single road feature type";
CM_ SG_ 371 ADC_RiWhlRoadSts "Uneven (concave/convex) condition of the right wheel pavement";
CM_ SG_ 371 ADC_CDCCtrlEnable "ADS Enable signal";
CM_ SG_ 371 ADC_RoadInfoAvl "Road information significance";
CM_ SG_ 371 ADC_RoadFeatureDetFalutSts "Road feature Dettion Fault Status";
CM_ SG_ 371 ADC_RoadFeatureDetWorkSts "Road feature Dettion Work Status";
CM_ SG_ 371 ADC_LeWhlRoadFeature2 "Left-wheel single road feature2 type";
CM_ SG_ 371 ADC_LeWhlRoadFeature3 "Left-wheel single road feature3 type";
CM_ SG_ 371 ADC_RiWhlRoadFeature2 "Right wheel single road feature2 type";
CM_ SG_ 371 ADC_RiWhlRoadFeature3 "Right wheel single road feature3 type";
CM_ SG_ 371 ADC_LeWhlRoadHei2 "Left front wheel front feature2 road bump height (or dip depth)";
CM_ SG_ 371 ADC_LeWhlRoadHei3 "Left front wheel front feature3 road bump height (or dip depth)";
CM_ SG_ 371 ADC_RiWhlRoadHei2 "Right front wheel front feature2 road bump height (or dip depth)";
CM_ SG_ 371 ADC_RiWhlRoadHei3 "Right front wheel front feature3 road bump height (or dip depth)";
CM_ SG_ 371 ADC_LeWhlLgtDst2 "The distance from the projection point of the left front wheel center on the ground to the edge of the road feature2 area";
CM_ SG_ 371 ADC_LeWhlLgtDst3 "The distance from the projection point of the left front wheel center on the ground to the edge of the road feature3 area";
CM_ SG_ 371 ADC_RiWhlLgtDst2 "The distance from the projection point of the right front wheel center on the ground to the edge of the road feature2 area";
CM_ SG_ 371 ADC_RiWhlLgtDst3 "The distance from the projection point of the right front wheel center on the ground to the edge of the road feature3 area";
CM_ SG_ 371 ADC_AS_SuspHeiAdj "Request suspension adjustment control signal";
CM_ SG_ 371 ADC_AS_SuspHeiAdjVld "Request?suspension?adjustment?control?significant?signal";
CM_ SG_ 371 ADC_AS_SusStfnAdj "Request suspension stiffness adjustment control signal";
CM_ SG_ 371 ADC_AS_SusStfnAdjVld "Request suspension stiffness adjustment to control the significant signal";
CM_ SG_ 371 ADC_CDCModReq "Request?shock?absorber?damper?adjustment?control?signal";
CM_ SG_ 371 ADC_CDCModReqVld "Request damper damper regulation control significant signal";
CM_ SG_ 371 ADC_UrgentSteerFlg "Urgent Steering Flag of ADC";
CM_ SG_ 371 ADC_OneMotorCtrlEna "Motor Direct Control Enable Flag";
CM_ SG_ 371 ADC_MotorCtrlTqWhlRL "Target Drive Torque for Rear Left Motor";
CM_ SG_ 371 ADC_MotorCtrlTqWhlRR "Target Drive Torque for Rear Right Motor";
CM_ SG_ 371 ADC_SteerGainLevelTqCtrl "Driver steering torque gain request value";
CM_ SG_ 371 ADC_MotorCtrlTqWhlFR "Target Drive Torque for Front Right Motor";
CM_ SG_ 371 ADC_MotorCtrlTqWhlFL "Target Drive Torque for Front Left Motor";
CM_ SG_ 422 VCU_1_B_CRC "E2E Profile 5 CRC";
CM_ SG_ 422 VCU_1_B_Counter "E2E Profile 5 Counter";
CM_ SG_ 422 VCU_AccButtInfo_B "ACC Button Information";
CM_ SG_ 422 VCU_LateralAssistBtnInfo_B "VCU_LateralAssistBtnInfo";
CM_ SG_ 422 VCU_LateralAssistBtnInfoVD_B "Lateral assist button Information valid data";
CM_ SG_ 422 VCU_AccMasterCanError_B "ACC Master CAN Error";
CM_ SG_ 422 VCU_IFCFailureSt_B "IFC Failure Status";
CM_ SG_ 422 VCU_VehDrvMod_B "Drive?mode?for?display";
CM_ SG_ 422 VCU_VehRdySt_B "HEV?system?ready?status";
CM_ SG_ 422 VCU_GearLvl_B "Gear?lever?for?PEPS";
CM_ SG_ 422 VCU_RecpTorqVD_B "Status?of?recuperation?torque?of?generator ";
CM_ SG_ 422 VCU_RecpTorq_B "Current?recuperation?torque?of?generator";
CM_ SG_ 422 VCU_BrkPedPst_B "Current?brake?pedal?position";
CM_ SG_ 422 VCU_BrkPedPstVD_B "Current?brake?pedal?position?valid?data";
CM_ SG_ 422 VCU_CrntGearLvlVD_B "Valid?bit?for?ActualGearPosition.";
CM_ SG_ 422 VCU_CrntGearLvl_B "VCU?current?carry?out?gear?level";
CM_ SG_ 422 VCU_ACCLimitOperatingSt_B "peration status of ACC Limit mode, When VCU Enter the power-saving mode";
CM_ SG_ 422 VCU_ACCMaxRecpDecelVD_B "VCU_ACCMaxRecpDecel valid validity";
CM_ SG_ 422 VCU_ACCMaxRecpDecel_B "Current?maximum?recuperation?deceleration?of generator";
CM_ SG_ 422 VCU_ActVehWheelTorq_B "Actual effective engine torque on wheel level";
CM_ SG_ 422 VCU_ACCmaxSpdLimit_B "When VCU Enter the power-saving mode，the maximum ACC target speed limited by VCU";
CM_ SG_ 422 VCU_VehWheelTorqMax_B "Actual effective maximum adjustable torque on wheel level";
CM_ SG_ 422 VCU_GasPedalActPstforMRRVD_B "VCU GasPedalActPstforMRR Valid Data";
CM_ SG_ 422 VCU_AccElecECFail_B "Indicate the error state of electronic engine control.";
CM_ SG_ 422 VCU_AccDriverOrvd_B "Indicating the torque demanded by the driver is higher than the torque demanded by ACC.";
CM_ SG_ 422 VCU_APAAvailable_B "Whether VCU is available for APA function";
CM_ SG_ 422 VCU_APA_Resp_B "VCU response to APA if VCU is response the gear shif and torque request";
CM_ SG_ 422 VCU_GasPedalActPstforMRR_B "Current Actual accelerate pedal position.";
CM_ SG_ 422 VCU_AccPedalActPst_B "Current Actual or Virtual accelerate pedal position.";
CM_ SG_ 422 VCU_BrkPedalSt_B "Brake pedal status";
CM_ SG_ 422 VCU_BrkPedalStVD_B "BrakePedSt valid data";
CM_ SG_ 422 VCU_AccPedalActPstVD_B "VCU_AccPedalActPst Valid Data.";
CM_ SG_ 422 VCU_AccTMCFail_B "Indicating VCU in limp-home (error) mode";
CM_ SG_ 619 EPB_FailSt_L "EPB fail status,to indicate wether EPB can response to external apply  request or not";
CM_ SG_ 619 EPB_ExtAvailable_L "EPB  status,to indicate wetherEPB can response to externalapply request or not";
CM_ SG_ 619 EPB_ActuatorSt_L "EPB left  actuator status";
CM_ SG_ 728 ECS_1_CRC "E2E Profile 5 CRC";
CM_ SG_ 728 ECS_1_Counter "E2E Profile 5 Counter";
CM_ SG_ 728 SDC_SolenoidErrorStRR "Error status of RR solenoid";
CM_ SG_ 728 CDC_ADCCtrlAvl "CDC control available signal";
CM_ SG_ 728 CDC_ADCCtrlRespSts "CDC control response signal";
CM_ SG_ 728 SDC_ExternalReqMode "SDC internal mode for  external request";
CM_ SG_ 728 SDC_CurrentDamperMode "SDC current damper mode";
CM_ SG_ 728 SDC_WarningLampReq "SDC warning lamp requirement";
CM_ SG_ 728 SDC_ProhibitChangingMode "SDC mode change is prohibited";
CM_ SG_ 728 SDC_BodyAccErrorStFL "Error status of FL body sensor";
CM_ SG_ 728 SDC_BodyAccErrorStFR "Error status of FR body sensor";
CM_ SG_ 728 SDC_BodyAccErrorStRr "Error status of Rear body sensor";
CM_ SG_ 728 SDC_WheelAccErrorStFL "Error status of FL wheel sensor";
CM_ SG_ 728 SDC_WheelAccErrorStFR "Error status of FR wheel sensor";
CM_ SG_ 728 SDC_SolenoidWorkSt "SDC slolenoid working status";
CM_ SG_ 728 CDC_FailureSt "Electronic control suspension failure status:Bit 0 : Level S1- 0x00 = No Failure- 0x01 = FalureBit 1 : Level S2- 0x00 = No Failure- 0x01 = FalureBit 2 : Level S3- 0x00 = No Failure- 0x01 = FalureBit 3 : Level S4- 0x00 = No Failure- 0x01 = FalureBit 4 : Level O1- 0x00 = No Failure- 0x01 = FalureBit 5 : Level O2- 0x00 = No Failure- 0x01 = FalureBit 6 : Level O3- 0x00 = No Failure- 0x01 = FalureBit 7 : Level O4- 0x00 = No Failure- 0x01 = Falure";
CM_ SG_ 728 CDC_ADCModState "CDC current damped state feedback";
CM_ SG_ 459 ECS_2_CRC "E2E Profile 5 CRC";
CM_ SG_ 459 ECS_2_Counter "E2E Profile 5 Counter";
CM_ SG_ 459 AS_SuspHeightFL "Height of front left wheel";
CM_ SG_ 459 AS_SuspHeightFR "Height of front right wheel";
CM_ SG_ 459 AS_SuspHeightRL "Height of rear left wheel";
CM_ SG_ 459 AS_SuspHeightRR "Height of rear right wheel";
CM_ SG_ 459 AS_SuspHeightFLVD "Height of front left wheel validity";
CM_ SG_ 459 AS_SuspHeightFRVD "Height of front right wheel validity";
CM_ SG_ 459 AS_SuspHeightRLVD "Height of rear left wheel validity";
CM_ SG_ 459 AS_SuspHeightRRVD "Height of rear right wheel validity";
CM_ SG_ 459 AS_SuspHeightSensorFLSt "Front left suspension height sensor fault status";
CM_ SG_ 459 AS_SuspHeightSensorFRSt "Front right suspension height sensor fault status";
CM_ SG_ 459 AS_SuspHeightSensorRLSt "Rear left suspension height sensor fault status";
CM_ SG_ 459 AS_SuspHeightSensoRRSt "Rear right suspension height sensor fault status";
CM_ SG_ 459 AS_MaintanceModeSt "Air spring maintance mode status";
CM_ SG_ 459 ECS_AVDCReqMode "Electronic control suspension internal mode for AVDC电子控制悬架AVDC执行状态";
CM_ SG_ 459 AS_FrontAxleSuspSt "Height adjustment of the front axle";
CM_ SG_ 459 AS_RearAxleSuspSt "Height adjustment status of rear axle";
CM_ SG_ 459 AS_HeightWarningSt "Vehicle height warning";
CM_ SG_ 459 AS_CurrentLevel "Vehicle current height level";
CM_ SG_ 459 AS_TargetLevel "Vehicle target height level";
CM_ SG_ 459 AS_ASMode "Air spring opreation mode";
CM_ SG_ 459 AS_SysFaultSt "Air Spring system fault";
CM_ SG_ 459 AS_OverHeatingSt "Pump overheating status";
CM_ SG_ 459 AS_SysOperationSt "Air Spring operation status";
CM_ SG_ 459 AS_OverLoadSt "Vehicle overload status";
CM_ SG_ 459 AS_OverTorsionSt "Vehicle over torsion parking status";
CM_ SG_ 459 AS_ManufacModeSt "Air spring Manufac mode status";
CM_ SG_ 459 AS_ASIndividualMode "Air spring Individual opreation mode";
CM_ SG_ 459 AS_ADCStfnCtrlAvl "Available signals for suspension stiffness control";
CM_ SG_ 459 AS_ADCStfnState "Suspension stiffness state feedback signal";
CM_ SG_ 359 BCS_1_B_CRC "E2E Profile 5 CRC";
CM_ SG_ 359 BCS_1_B_Counter "E2E Profile 5 Counter";
CM_ SG_ 359 BCS_FLWheelSpd_B "Current wheel speed information of front left wheel";
CM_ SG_ 359 BCS_FLWheelSpdVD_B "Quality/fault information to current wheel speed of front left wheel";
CM_ SG_ 359 BCS_FLWheelRotatedDirection_B "FL wheel rotate direction";
CM_ SG_ 359 BCS_FLWheelRotatedDirectionVD_B "FL wheel rotate direction validity";
CM_ SG_ 359 BCS_FRWheelSpd_B "Current wheel speed information of front right wheel";
CM_ SG_ 359 BCS_FRWheelSpdVD_B "Quality/fault information to current wheel speed of front right  wheel";
CM_ SG_ 359 BCS_FRWheelRotatedDirection_B "FR wheel rotate direction";
CM_ SG_ 359 BCS_FRWheelRotatedDirectionVD_B "FR wheel rotate direction validity";
CM_ SG_ 359 BCS_RLWheelSpd_B "Current wheel speed information of rear left wheel";
CM_ SG_ 359 BCS_RLWheelSpdVD_B "Quality/fault information to current wheel speed of rear left wheel";
CM_ SG_ 359 BCS_RLWheelRotatedDirection_B "RL wheel rotate direction";
CM_ SG_ 359 BCS_RLWheelRotatedDirectionVD_B "RL wheel rotate direction validity";
CM_ SG_ 359 BCS_RRWheelSpd_B "Current wheel speed information of rear right wheel";
CM_ SG_ 359 BCS_RRWheelSpdVD_B "Quality/fault information to current wheel speed of rear right wheel";
CM_ SG_ 359 BCS_RRWheelRotatedDirection_B "RR wheel rotate direction";
CM_ SG_ 359 BCS_RRWheelRotatedDirectionVD_B "RR wheel rotate direction validity";
CM_ SG_ 359 BCS_HHCCtrlSt_B "HHC(Hill Hold Control) control status";
CM_ SG_ 359 BCS_HDCCtrlSt_B "HDC(Hill Descent Control) control status";
CM_ SG_ 359 BCS_HDCErrSt_B "HDC error status";
CM_ SG_ 359 BCS_FLWheelSpdEdgesSum_B "Accumulated sum of rising and falling edges of front left wheel speed sensor output·since IGN ON( the wheel plate have 48 teeth/cycle,the edge is 96)";
CM_ SG_ 359 BCS_FRWheelSpdEdgesSum_B "Accumulated sum of rising and falling edges of front right wheel speed sensor output·since IGN ON( the wheel plate have 48 teeth/cycle,the edge is 96)";
CM_ SG_ 359 BCS_RLWheelSpdEdgesSum_B "Accumulated sum of rising and falling edges of rear left wheel speed sensor output·since IGN ON( the wheel plate have 48 teeth/cycle,the edge is 96)";
CM_ SG_ 359 BCS_RRWheelSpdEdgesSum_B "Accumulated sum of rising and falling edges of  rear right wheel speed sensor output·since IGN ON( the wheel plate have 48 teeth/cycle,the edge is 96)";
CM_ SG_ 359 BCS_FLWheelSpdEdgesSumVD_B "Quality/fault information to current wheel speed edges sum of front left wheel";
CM_ SG_ 359 BCS_FRWheelSpdEdgesSumVD_B "Quality/fault information to current wheel speed edges sum of front right wheel";
CM_ SG_ 359 BCS_RLWheelSpdEdgesSumVD_B "Quality/fault information to current wheel speed edges sum of rear left wheel";
CM_ SG_ 359 BCS_RRWheelSpdEdgesSumVD_B "Quality/fault information to current wheel speed edges sum of rear right wheel";
CM_ SG_ 359 BCS_FLWheelRotatedDirectionAPA_B "FL wheel rotate direction for APA";
CM_ SG_ 359 BCS_FRWheelRotatedDirectionAPA_B "FR wheel rotate direction for APA";
CM_ SG_ 359 BCS_RLWheelRotatedDirectionAPA_B "RL wheel rotate direction for APA";
CM_ SG_ 359 BCS_RRWheelRotatedDirectionAPA_B "RR wheel rotate direction for APA";
CM_ SG_ 359 BCS_ParkingReqToEPB_B "Indicates the release/lock brake request to EPB";
CM_ SG_ 359 BCS_VDCOff_B "VDC is switched off ";
CM_ SG_ 359 BCS_AVHSt_B "Indicates AVH(Auto Vehicle Hold)in active or not ";
CM_ SG_ 359 BCS_AVHAvailable_B "HMI responsible, can get degrate AVH(Auto Vehicle Hold) statement from DSW and send out ";
CM_ SG_ 359 BCS_TCSOff_B "TCS is switched off ";
CM_ SG_ 359 BCS_BrakeOverHeat_B "Indicating brake temperature too high or not";
CM_ SG_ 359 BCS_ABAactive_B "ABA(Adaptive Brake Assistance) is active";
CM_ SG_ 359 BCS_ABAavailable_B "The ABA(Adaptive Brake Assistance)  function is available";
CM_ SG_ 359 BCS_ABPActive_B "ABP(Automatic brake Pre-fill) is active";
CM_ SG_ 359 BCS_ABPAvailable_B "ABP(Automatic brake Pre-fill) is available";
CM_ SG_ 359 BCS_AEBActive_B "AEB(Automatic EmergencyBraking) is active (in deceleration)";
CM_ SG_ 359 BCS_AEBAvailable_B "AEB(Automatic EmergencyBraking) is available";
CM_ SG_ 359 BCS_AWBActive_B "AWB(Automatic Warning Brake) is active";
CM_ SG_ 359 BCS_AWBAvailable_B "AWB(Automatic Warning Brake) is available";
CM_ SG_ 359 BCS_AVHStandby_B "Indicates AVH(Auto Vehicle Hold)in standby mode or not ";
CM_ SG_ 359 BCS_AEBBAActive_B "Indicates AEBBA active or not";
CM_ SG_ 359 BCS_VehicleStandStillSt_B "Indicating whether the vehicle is standstill or not;must not be set until standstill is surely reached.";
CM_ SG_ 359 IPB_InputRodStroke_B "Indicate inputRod stroke value";
CM_ SG_ 359 IPB_PlungerPressureSt_B "Indicate plunger pressure status";
CM_ SG_ 359 BCS_RAEBAvailable_B "RAEB is available ";
CM_ SG_ 359 BCS_RAEBActive_B "RAEB is active ";
CM_ SG_ 359 IPB_InputRodStrokeSt_B "Indicate inputRod stroke status";
CM_ SG_ 359 IPB_PlungerPressure_B "Indicate plunger pressure value";
CM_ SG_ 1359 CCU_NMNodeAddress "CCU node address";
CM_ SG_ 1359 CCU_NMCBV "CCU Network management  control bit vector";
CM_ SG_ 1359 CCU_NMWakeupOrigin "Origin of the wake up";
CM_ SG_ 1359 CCU_PNCInformation0 "PNC Information";
CM_ SG_ 1359 CCU_PNCInformation1 "PNC Information";
CM_ SG_ 1359 CCU_PNCInformation2 "PNC Information";
CM_ SG_ 1290 IDU_NMNodeAddress "IDU node address";
CM_ SG_ 1290 IDU_NMCBV "IDU Network management data";
CM_ SG_ 1290 IDU_NMWakeupOrigin "Origin of the wake up";
CM_ SG_ 1290 IDU_PNCInformation0 "PNC Information";
CM_ SG_ 1290 IDU_PNCInformation1 "PNC Information";
CM_ SG_ 1290 IDU_PNCInformation2 "PNC Information";
CM_ SG_ 1294 ADC_NMNodeAddress "ADC node address";
CM_ SG_ 1294 ADC_NMCBV "ADC Network management  control bit vector";
CM_ SG_ 1294 ADC_NMWakeupOrigin "Origin of the wake up";
CM_ SG_ 1294 ADC_PNCInformation0 "PNC Information";
CM_ SG_ 1294 ADC_PNCInformation1 "PNC Information";
CM_ SG_ 1294 ADC_PNCInformation2 "PNC Information";
CM_ SG_ 1406 NIDU_NMNodeAddress "NIDU node address";
CM_ SG_ 1406 NIDU_NMCBV "NIDU Network management control bit vector";
CM_ SG_ 1406 NIDU_NMWakeupOrigin "Origin of the wake up";
CM_ SG_ 1406 NIDU_PNCInformation0 "PNC Information";
CM_ SG_ 1406 NIDU_PNCInformation1 "PNC Information";
CM_ SG_ 1406 NIDU_PNCInformation2 "PNC Information";
CM_ SG_ 2015 Fun_Diag_Request "Diagnostic function request";

BA_DEF_ BO_  "GenMsgCycleTime" INT 0 0;
BA_DEF_ BO_  "GenMsgCycleTimeFast" INT 0 0;
BA_DEF_ BO_  "GenMsgSendType" ENUM  "Periodic","Event","IfActive","POE","PA","FixedPeriodic","Event","EnabledPeriodic","NotUsed","NotUsed","EventPeriodic","NotUsed","NotUsed","NoMsgSendType";
BA_DEF_ BO_  "VFrameFormat" ENUM  "StandardCAN","ExtendedCAN","reserved","reserved","reserved","reserved","reserved","reserved","reserved","reserved","reserved","reserved","reserved","reserved","StandardCAN_FD","ExtendedCAN_FD";
BA_DEF_ BO_  "CANFD_BRS" ENUM  "0","1";
BA_DEF_ SG_  "EventCommandSignal" ENUM  "No","Yes";
BA_DEF_ SG_  "GatewayedSignals" ENUM  "No","Yes";
BA_DEF_ SG_  "GenSigInactiveValue" HEX 0 0;
BA_DEF_ SG_  "GenSigInvalidValue" HEX 0 0;
BA_DEF_ SG_  "GenSigSendType" ENUM  "Trigger","Passive","Cyclic","OnWrite","OnWriteWithRepetition","OnChange","OnChangeWithRepetition","IfActive","IfActiveWithRepetition","NoSigSendType";
BA_DEF_ SG_  "GenSigStartValue" HEX 0 0;
BA_DEF_ SG_  "GenSigTimeoutValue" HEX 0 0;
BA_DEF_ SG_  "Remark" STRING ;
BA_ "GenMsgCycleTime" BO_ 371 10;
BA_ "GenMsgCycleTimeFast" BO_ 371 0;
BA_ "GenMsgSendType" BO_ 371 0;
BA_ "VFrameFormat" BO_ 371 14;
BA_ "CANFD_BRS" BO_ 371 1;
BA_ "GenMsgCycleTime" BO_ 371 10;
BA_ "GenMsgCycleTimeFast" BO_ 371 0;
BA_ "GenMsgSendType" BO_ 371 0;
BA_ "VFrameFormat" BO_ 371 14;
BA_ "CANFD_BRS" BO_ 371 1;
BA_ "GenMsgCycleTime" BO_ 371 10;
BA_ "GenMsgCycleTimeFast" BO_ 371 0;
BA_ "GenMsgSendType" BO_ 371 0;
BA_ "VFrameFormat" BO_ 371 14;
BA_ "CANFD_BRS" BO_ 371 1;
BA_ "GenMsgCycleTime" BO_ 371 10;
BA_ "GenMsgCycleTimeFast" BO_ 371 0;
BA_ "GenMsgSendType" BO_ 371 0;
BA_ "VFrameFormat" BO_ 371 14;
BA_ "CANFD_BRS" BO_ 371 1;
BA_ "GenMsgCycleTime" BO_ 371 10;
BA_ "GenMsgCycleTimeFast" BO_ 371 0;
BA_ "GenMsgSendType" BO_ 371 0;
BA_ "VFrameFormat" BO_ 371 14;
BA_ "CANFD_BRS" BO_ 371 1;
BA_ "GenMsgCycleTime" BO_ 371 10;
BA_ "GenMsgCycleTimeFast" BO_ 371 0;
BA_ "GenMsgSendType" BO_ 371 0;
BA_ "VFrameFormat" BO_ 371 14;
BA_ "CANFD_BRS" BO_ 371 1;
BA_ "GenMsgCycleTime" BO_ 371 10;
BA_ "GenMsgCycleTimeFast" BO_ 371 0;
BA_ "GenMsgSendType" BO_ 371 0;
BA_ "VFrameFormat" BO_ 371 14;
BA_ "CANFD_BRS" BO_ 371 1;
BA_ "GenMsgCycleTime" BO_ 371 10;
BA_ "GenMsgCycleTimeFast" BO_ 371 0;
BA_ "GenMsgSendType" BO_ 371 0;
BA_ "VFrameFormat" BO_ 371 14;
BA_ "CANFD_BRS" BO_ 371 1;
BA_ "GenMsgCycleTime" BO_ 371 10;
BA_ "GenMsgCycleTimeFast" BO_ 371 0;
BA_ "GenMsgSendType" BO_ 371 0;
BA_ "VFrameFormat" BO_ 371 14;
BA_ "CANFD_BRS" BO_ 371 1;
BA_ "GenMsgCycleTime" BO_ 371 10;
BA_ "GenMsgCycleTimeFast" BO_ 371 0;
BA_ "GenMsgSendType" BO_ 371 0;
BA_ "VFrameFormat" BO_ 371 14;
BA_ "CANFD_BRS" BO_ 371 1;
BA_ "GenMsgCycleTime" BO_ 371 10;
BA_ "GenMsgCycleTimeFast" BO_ 371 0;
BA_ "GenMsgSendType" BO_ 371 0;
BA_ "VFrameFormat" BO_ 371 14;
BA_ "CANFD_BRS" BO_ 371 1;
BA_ "GenMsgCycleTime" BO_ 371 10;
BA_ "GenMsgCycleTimeFast" BO_ 371 0;
BA_ "GenMsgSendType" BO_ 371 0;
BA_ "VFrameFormat" BO_ 371 14;
BA_ "CANFD_BRS" BO_ 371 1;
BA_ "GenMsgCycleTime" BO_ 371 10;
BA_ "GenMsgCycleTimeFast" BO_ 371 0;
BA_ "GenMsgSendType" BO_ 371 0;
BA_ "VFrameFormat" BO_ 371 14;
BA_ "CANFD_BRS" BO_ 371 1;
BA_ "GenMsgCycleTime" BO_ 371 10;
BA_ "GenMsgCycleTimeFast" BO_ 371 0;
BA_ "GenMsgSendType" BO_ 371 0;
BA_ "VFrameFormat" BO_ 371 14;
BA_ "CANFD_BRS" BO_ 371 1;
BA_ "GenMsgCycleTime" BO_ 371 10;
BA_ "GenMsgCycleTimeFast" BO_ 371 0;
BA_ "GenMsgSendType" BO_ 371 0;
BA_ "VFrameFormat" BO_ 371 14;
BA_ "CANFD_BRS" BO_ 371 1;
BA_ "GenMsgCycleTime" BO_ 371 10;
BA_ "GenMsgCycleTimeFast" BO_ 371 0;
BA_ "GenMsgSendType" BO_ 371 0;
BA_ "VFrameFormat" BO_ 371 14;
BA_ "CANFD_BRS" BO_ 371 1;
BA_ "GenMsgCycleTime" BO_ 371 10;
BA_ "GenMsgCycleTimeFast" BO_ 371 0;
BA_ "GenMsgSendType" BO_ 371 0;
BA_ "VFrameFormat" BO_ 371 14;
BA_ "CANFD_BRS" BO_ 371 1;
BA_ "GenMsgCycleTime" BO_ 371 10;
BA_ "GenMsgCycleTimeFast" BO_ 371 0;
BA_ "GenMsgSendType" BO_ 371 0;
BA_ "VFrameFormat" BO_ 371 14;
BA_ "CANFD_BRS" BO_ 371 1;
BA_ "GenMsgCycleTime" BO_ 371 10;
BA_ "GenMsgCycleTimeFast" BO_ 371 0;
BA_ "GenMsgSendType" BO_ 371 0;
BA_ "VFrameFormat" BO_ 371 14;
BA_ "CANFD_BRS" BO_ 371 1;
BA_ "GenMsgCycleTime" BO_ 371 10;
BA_ "GenMsgCycleTimeFast" BO_ 371 0;
BA_ "GenMsgSendType" BO_ 371 0;
BA_ "VFrameFormat" BO_ 371 14;
BA_ "CANFD_BRS" BO_ 371 1;
BA_ "GenMsgCycleTime" BO_ 371 10;
BA_ "GenMsgCycleTimeFast" BO_ 371 0;
BA_ "GenMsgSendType" BO_ 371 0;
BA_ "VFrameFormat" BO_ 371 14;
BA_ "CANFD_BRS" BO_ 371 1;
BA_ "GenMsgCycleTime" BO_ 371 10;
BA_ "GenMsgCycleTimeFast" BO_ 371 0;
BA_ "GenMsgSendType" BO_ 371 0;
BA_ "VFrameFormat" BO_ 371 14;
BA_ "CANFD_BRS" BO_ 371 1;
BA_ "GenMsgCycleTime" BO_ 371 10;
BA_ "GenMsgCycleTimeFast" BO_ 371 0;
BA_ "GenMsgSendType" BO_ 371 0;
BA_ "VFrameFormat" BO_ 371 14;
BA_ "CANFD_BRS" BO_ 371 1;
BA_ "GenMsgCycleTime" BO_ 371 10;
BA_ "GenMsgCycleTimeFast" BO_ 371 0;
BA_ "GenMsgSendType" BO_ 371 0;
BA_ "VFrameFormat" BO_ 371 14;
BA_ "CANFD_BRS" BO_ 371 1;
BA_ "GenMsgCycleTime" BO_ 371 10;
BA_ "GenMsgCycleTimeFast" BO_ 371 0;
BA_ "GenMsgSendType" BO_ 371 0;
BA_ "VFrameFormat" BO_ 371 14;
BA_ "CANFD_BRS" BO_ 371 1;
BA_ "GenMsgCycleTime" BO_ 371 10;
BA_ "GenMsgCycleTimeFast" BO_ 371 0;
BA_ "GenMsgSendType" BO_ 371 0;
BA_ "VFrameFormat" BO_ 371 14;
BA_ "CANFD_BRS" BO_ 371 1;
BA_ "GenMsgCycleTime" BO_ 371 10;
BA_ "GenMsgCycleTimeFast" BO_ 371 0;
BA_ "GenMsgSendType" BO_ 371 0;
BA_ "VFrameFormat" BO_ 371 14;
BA_ "CANFD_BRS" BO_ 371 1;
BA_ "GenMsgCycleTime" BO_ 371 10;
BA_ "GenMsgCycleTimeFast" BO_ 371 0;
BA_ "GenMsgSendType" BO_ 371 0;
BA_ "VFrameFormat" BO_ 371 14;
BA_ "CANFD_BRS" BO_ 371 1;
BA_ "GenMsgCycleTime" BO_ 371 10;
BA_ "GenMsgCycleTimeFast" BO_ 371 0;
BA_ "GenMsgSendType" BO_ 371 0;
BA_ "VFrameFormat" BO_ 371 14;
BA_ "CANFD_BRS" BO_ 371 1;
BA_ "GenMsgCycleTime" BO_ 371 10;
BA_ "GenMsgCycleTimeFast" BO_ 371 0;
BA_ "GenMsgSendType" BO_ 371 0;
BA_ "VFrameFormat" BO_ 371 14;
BA_ "CANFD_BRS" BO_ 371 1;
BA_ "GenMsgCycleTime" BO_ 371 10;
BA_ "GenMsgCycleTimeFast" BO_ 371 0;
BA_ "GenMsgSendType" BO_ 371 0;
BA_ "VFrameFormat" BO_ 371 14;
BA_ "CANFD_BRS" BO_ 371 1;
BA_ "GenMsgCycleTime" BO_ 371 10;
BA_ "GenMsgCycleTimeFast" BO_ 371 0;
BA_ "GenMsgSendType" BO_ 371 0;
BA_ "VFrameFormat" BO_ 371 14;
BA_ "CANFD_BRS" BO_ 371 1;
BA_ "GenMsgCycleTime" BO_ 371 10;
BA_ "GenMsgCycleTimeFast" BO_ 371 0;
BA_ "GenMsgSendType" BO_ 371 0;
BA_ "VFrameFormat" BO_ 371 14;
BA_ "CANFD_BRS" BO_ 371 1;
BA_ "GenMsgCycleTime" BO_ 371 10;
BA_ "GenMsgCycleTimeFast" BO_ 371 0;
BA_ "GenMsgSendType" BO_ 371 0;
BA_ "VFrameFormat" BO_ 371 14;
BA_ "CANFD_BRS" BO_ 371 1;
BA_ "GenMsgCycleTime" BO_ 371 10;
BA_ "GenMsgCycleTimeFast" BO_ 371 0;
BA_ "GenMsgSendType" BO_ 371 0;
BA_ "VFrameFormat" BO_ 371 14;
BA_ "CANFD_BRS" BO_ 371 1;
BA_ "GenMsgCycleTime" BO_ 371 10;
BA_ "GenMsgCycleTimeFast" BO_ 371 0;
BA_ "GenMsgSendType" BO_ 371 0;
BA_ "VFrameFormat" BO_ 371 14;
BA_ "CANFD_BRS" BO_ 371 1;
BA_ "GenMsgCycleTime" BO_ 371 10;
BA_ "GenMsgCycleTimeFast" BO_ 371 0;
BA_ "GenMsgSendType" BO_ 371 0;
BA_ "VFrameFormat" BO_ 371 14;
BA_ "CANFD_BRS" BO_ 371 1;
BA_ "GenMsgCycleTime" BO_ 371 10;
BA_ "GenMsgCycleTimeFast" BO_ 371 0;
BA_ "GenMsgSendType" BO_ 371 0;
BA_ "VFrameFormat" BO_ 371 14;
BA_ "CANFD_BRS" BO_ 371 1;
BA_ "GenMsgCycleTime" BO_ 371 10;
BA_ "GenMsgCycleTimeFast" BO_ 371 0;
BA_ "GenMsgSendType" BO_ 371 0;
BA_ "VFrameFormat" BO_ 371 14;
BA_ "CANFD_BRS" BO_ 371 1;
BA_ "GenMsgCycleTime" BO_ 371 10;
BA_ "GenMsgCycleTimeFast" BO_ 371 0;
BA_ "GenMsgSendType" BO_ 371 0;
BA_ "VFrameFormat" BO_ 371 14;
BA_ "CANFD_BRS" BO_ 371 1;
BA_ "GenMsgCycleTime" BO_ 371 10;
BA_ "GenMsgCycleTimeFast" BO_ 371 0;
BA_ "GenMsgSendType" BO_ 371 0;
BA_ "VFrameFormat" BO_ 371 14;
BA_ "CANFD_BRS" BO_ 371 1;
BA_ "GenMsgCycleTime" BO_ 371 10;
BA_ "GenMsgCycleTimeFast" BO_ 371 0;
BA_ "GenMsgSendType" BO_ 371 0;
BA_ "VFrameFormat" BO_ 371 14;
BA_ "CANFD_BRS" BO_ 371 1;
BA_ "GenMsgCycleTime" BO_ 371 10;
BA_ "GenMsgCycleTimeFast" BO_ 371 0;
BA_ "GenMsgSendType" BO_ 371 0;
BA_ "VFrameFormat" BO_ 371 14;
BA_ "CANFD_BRS" BO_ 371 1;
BA_ "GenMsgCycleTime" BO_ 371 10;
BA_ "GenMsgCycleTimeFast" BO_ 371 0;
BA_ "GenMsgSendType" BO_ 371 0;
BA_ "VFrameFormat" BO_ 371 14;
BA_ "CANFD_BRS" BO_ 371 1;
BA_ "GenMsgCycleTime" BO_ 371 10;
BA_ "GenMsgCycleTimeFast" BO_ 371 0;
BA_ "GenMsgSendType" BO_ 371 0;
BA_ "VFrameFormat" BO_ 371 14;
BA_ "CANFD_BRS" BO_ 371 1;
BA_ "GenMsgCycleTime" BO_ 371 10;
BA_ "GenMsgCycleTimeFast" BO_ 371 0;
BA_ "GenMsgSendType" BO_ 371 0;
BA_ "VFrameFormat" BO_ 371 14;
BA_ "CANFD_BRS" BO_ 371 1;
BA_ "GenMsgCycleTime" BO_ 371 10;
BA_ "GenMsgCycleTimeFast" BO_ 371 0;
BA_ "GenMsgSendType" BO_ 371 0;
BA_ "VFrameFormat" BO_ 371 14;
BA_ "CANFD_BRS" BO_ 371 1;
BA_ "GenMsgCycleTime" BO_ 371 10;
BA_ "GenMsgCycleTimeFast" BO_ 371 0;
BA_ "GenMsgSendType" BO_ 371 0;
BA_ "VFrameFormat" BO_ 371 14;
BA_ "CANFD_BRS" BO_ 371 1;
BA_ "GenMsgCycleTime" BO_ 371 10;
BA_ "GenMsgCycleTimeFast" BO_ 371 0;
BA_ "GenMsgSendType" BO_ 371 0;
BA_ "VFrameFormat" BO_ 371 14;
BA_ "CANFD_BRS" BO_ 371 1;
BA_ "GenMsgCycleTime" BO_ 371 10;
BA_ "GenMsgCycleTimeFast" BO_ 371 0;
BA_ "GenMsgSendType" BO_ 371 0;
BA_ "VFrameFormat" BO_ 371 14;
BA_ "CANFD_BRS" BO_ 371 1;
BA_ "GenMsgCycleTime" BO_ 371 10;
BA_ "GenMsgCycleTimeFast" BO_ 371 0;
BA_ "GenMsgSendType" BO_ 371 0;
BA_ "VFrameFormat" BO_ 371 14;
BA_ "CANFD_BRS" BO_ 371 1;
BA_ "GenMsgCycleTime" BO_ 371 10;
BA_ "GenMsgCycleTimeFast" BO_ 371 0;
BA_ "GenMsgSendType" BO_ 371 0;
BA_ "VFrameFormat" BO_ 371 14;
BA_ "CANFD_BRS" BO_ 371 1;
BA_ "GenMsgCycleTime" BO_ 371 10;
BA_ "GenMsgCycleTimeFast" BO_ 371 0;
BA_ "GenMsgSendType" BO_ 371 0;
BA_ "VFrameFormat" BO_ 371 14;
BA_ "CANFD_BRS" BO_ 371 1;
BA_ "GenMsgCycleTime" BO_ 371 10;
BA_ "GenMsgCycleTimeFast" BO_ 371 0;
BA_ "GenMsgSendType" BO_ 371 0;
BA_ "VFrameFormat" BO_ 371 14;
BA_ "CANFD_BRS" BO_ 371 1;
BA_ "GenMsgCycleTime" BO_ 371 10;
BA_ "GenMsgCycleTimeFast" BO_ 371 0;
BA_ "GenMsgSendType" BO_ 371 0;
BA_ "VFrameFormat" BO_ 371 14;
BA_ "CANFD_BRS" BO_ 371 1;
BA_ "GenMsgCycleTime" BO_ 371 10;
BA_ "GenMsgCycleTimeFast" BO_ 371 0;
BA_ "GenMsgSendType" BO_ 371 0;
BA_ "VFrameFormat" BO_ 371 14;
BA_ "CANFD_BRS" BO_ 371 1;
BA_ "GenMsgCycleTime" BO_ 371 10;
BA_ "GenMsgCycleTimeFast" BO_ 371 0;
BA_ "GenMsgSendType" BO_ 371 0;
BA_ "VFrameFormat" BO_ 371 14;
BA_ "CANFD_BRS" BO_ 371 1;
BA_ "GenMsgCycleTime" BO_ 371 10;
BA_ "GenMsgCycleTimeFast" BO_ 371 0;
BA_ "GenMsgSendType" BO_ 371 0;
BA_ "VFrameFormat" BO_ 371 14;
BA_ "CANFD_BRS" BO_ 371 1;
BA_ "GenMsgCycleTime" BO_ 371 10;
BA_ "GenMsgCycleTimeFast" BO_ 371 0;
BA_ "GenMsgSendType" BO_ 371 0;
BA_ "VFrameFormat" BO_ 371 14;
BA_ "CANFD_BRS" BO_ 371 1;
BA_ "GenMsgCycleTime" BO_ 371 10;
BA_ "GenMsgCycleTimeFast" BO_ 371 0;
BA_ "GenMsgSendType" BO_ 371 0;
BA_ "VFrameFormat" BO_ 371 14;
BA_ "CANFD_BRS" BO_ 371 1;
BA_ "GenMsgCycleTime" BO_ 371 10;
BA_ "GenMsgCycleTimeFast" BO_ 371 0;
BA_ "GenMsgSendType" BO_ 371 0;
BA_ "VFrameFormat" BO_ 371 14;
BA_ "CANFD_BRS" BO_ 371 1;
BA_ "GenMsgCycleTime" BO_ 371 10;
BA_ "GenMsgCycleTimeFast" BO_ 371 0;
BA_ "GenMsgSendType" BO_ 371 0;
BA_ "VFrameFormat" BO_ 371 14;
BA_ "CANFD_BRS" BO_ 371 1;
BA_ "GenMsgCycleTime" BO_ 371 10;
BA_ "GenMsgCycleTimeFast" BO_ 371 0;
BA_ "GenMsgSendType" BO_ 371 0;
BA_ "VFrameFormat" BO_ 371 14;
BA_ "CANFD_BRS" BO_ 371 1;
BA_ "GenMsgCycleTime" BO_ 371 10;
BA_ "GenMsgCycleTimeFast" BO_ 371 0;
BA_ "GenMsgSendType" BO_ 371 0;
BA_ "VFrameFormat" BO_ 371 14;
BA_ "CANFD_BRS" BO_ 371 1;
BA_ "GenMsgCycleTime" BO_ 371 10;
BA_ "GenMsgCycleTimeFast" BO_ 371 0;
BA_ "GenMsgSendType" BO_ 371 0;
BA_ "VFrameFormat" BO_ 371 14;
BA_ "CANFD_BRS" BO_ 371 1;
BA_ "GenMsgCycleTime" BO_ 422 10;
BA_ "GenMsgCycleTimeFast" BO_ 422 0;
BA_ "GenMsgSendType" BO_ 422 0;
BA_ "VFrameFormat" BO_ 422 14;
BA_ "CANFD_BRS" BO_ 422 1;
BA_ "GenMsgCycleTime" BO_ 422 10;
BA_ "GenMsgCycleTimeFast" BO_ 422 0;
BA_ "GenMsgSendType" BO_ 422 0;
BA_ "VFrameFormat" BO_ 422 14;
BA_ "CANFD_BRS" BO_ 422 1;
BA_ "GenMsgCycleTime" BO_ 422 10;
BA_ "GenMsgCycleTimeFast" BO_ 422 0;
BA_ "GenMsgSendType" BO_ 422 0;
BA_ "VFrameFormat" BO_ 422 14;
BA_ "CANFD_BRS" BO_ 422 1;
BA_ "GenMsgCycleTime" BO_ 422 10;
BA_ "GenMsgCycleTimeFast" BO_ 422 0;
BA_ "GenMsgSendType" BO_ 422 0;
BA_ "VFrameFormat" BO_ 422 14;
BA_ "CANFD_BRS" BO_ 422 1;
BA_ "GenMsgCycleTime" BO_ 422 10;
BA_ "GenMsgCycleTimeFast" BO_ 422 0;
BA_ "GenMsgSendType" BO_ 422 0;
BA_ "VFrameFormat" BO_ 422 14;
BA_ "CANFD_BRS" BO_ 422 1;
BA_ "GenMsgCycleTime" BO_ 422 10;
BA_ "GenMsgCycleTimeFast" BO_ 422 0;
BA_ "GenMsgSendType" BO_ 422 0;
BA_ "VFrameFormat" BO_ 422 14;
BA_ "CANFD_BRS" BO_ 422 1;
BA_ "GenMsgCycleTime" BO_ 422 10;
BA_ "GenMsgCycleTimeFast" BO_ 422 0;
BA_ "GenMsgSendType" BO_ 422 0;
BA_ "VFrameFormat" BO_ 422 14;
BA_ "CANFD_BRS" BO_ 422 1;
BA_ "GenMsgCycleTime" BO_ 422 10;
BA_ "GenMsgCycleTimeFast" BO_ 422 0;
BA_ "GenMsgSendType" BO_ 422 0;
BA_ "VFrameFormat" BO_ 422 14;
BA_ "CANFD_BRS" BO_ 422 1;
BA_ "GenMsgCycleTime" BO_ 422 10;
BA_ "GenMsgCycleTimeFast" BO_ 422 0;
BA_ "GenMsgSendType" BO_ 422 0;
BA_ "VFrameFormat" BO_ 422 14;
BA_ "CANFD_BRS" BO_ 422 1;
BA_ "GenMsgCycleTime" BO_ 422 10;
BA_ "GenMsgCycleTimeFast" BO_ 422 0;
BA_ "GenMsgSendType" BO_ 422 0;
BA_ "VFrameFormat" BO_ 422 14;
BA_ "CANFD_BRS" BO_ 422 1;
BA_ "GenMsgCycleTime" BO_ 422 10;
BA_ "GenMsgCycleTimeFast" BO_ 422 0;
BA_ "GenMsgSendType" BO_ 422 0;
BA_ "VFrameFormat" BO_ 422 14;
BA_ "CANFD_BRS" BO_ 422 1;
BA_ "GenMsgCycleTime" BO_ 422 10;
BA_ "GenMsgCycleTimeFast" BO_ 422 0;
BA_ "GenMsgSendType" BO_ 422 0;
BA_ "VFrameFormat" BO_ 422 14;
BA_ "CANFD_BRS" BO_ 422 1;
BA_ "GenMsgCycleTime" BO_ 422 10;
BA_ "GenMsgCycleTimeFast" BO_ 422 0;
BA_ "GenMsgSendType" BO_ 422 0;
BA_ "VFrameFormat" BO_ 422 14;
BA_ "CANFD_BRS" BO_ 422 1;
BA_ "GenMsgCycleTime" BO_ 422 10;
BA_ "GenMsgCycleTimeFast" BO_ 422 0;
BA_ "GenMsgSendType" BO_ 422 0;
BA_ "VFrameFormat" BO_ 422 14;
BA_ "CANFD_BRS" BO_ 422 1;
BA_ "GenMsgCycleTime" BO_ 422 10;
BA_ "GenMsgCycleTimeFast" BO_ 422 0;
BA_ "GenMsgSendType" BO_ 422 0;
BA_ "VFrameFormat" BO_ 422 14;
BA_ "CANFD_BRS" BO_ 422 1;
BA_ "GenMsgCycleTime" BO_ 422 10;
BA_ "GenMsgCycleTimeFast" BO_ 422 0;
BA_ "GenMsgSendType" BO_ 422 0;
BA_ "VFrameFormat" BO_ 422 14;
BA_ "CANFD_BRS" BO_ 422 1;
BA_ "GenMsgCycleTime" BO_ 422 10;
BA_ "GenMsgCycleTimeFast" BO_ 422 0;
BA_ "GenMsgSendType" BO_ 422 0;
BA_ "VFrameFormat" BO_ 422 14;
BA_ "CANFD_BRS" BO_ 422 1;
BA_ "GenMsgCycleTime" BO_ 422 10;
BA_ "GenMsgCycleTimeFast" BO_ 422 0;
BA_ "GenMsgSendType" BO_ 422 0;
BA_ "VFrameFormat" BO_ 422 14;
BA_ "CANFD_BRS" BO_ 422 1;
BA_ "GenMsgCycleTime" BO_ 422 10;
BA_ "GenMsgCycleTimeFast" BO_ 422 0;
BA_ "GenMsgSendType" BO_ 422 0;
BA_ "VFrameFormat" BO_ 422 14;
BA_ "CANFD_BRS" BO_ 422 1;
BA_ "GenMsgCycleTime" BO_ 422 10;
BA_ "GenMsgCycleTimeFast" BO_ 422 0;
BA_ "GenMsgSendType" BO_ 422 0;
BA_ "VFrameFormat" BO_ 422 14;
BA_ "CANFD_BRS" BO_ 422 1;
BA_ "GenMsgCycleTime" BO_ 422 10;
BA_ "GenMsgCycleTimeFast" BO_ 422 0;
BA_ "GenMsgSendType" BO_ 422 0;
BA_ "VFrameFormat" BO_ 422 14;
BA_ "CANFD_BRS" BO_ 422 1;
BA_ "GenMsgCycleTime" BO_ 422 10;
BA_ "GenMsgCycleTimeFast" BO_ 422 0;
BA_ "GenMsgSendType" BO_ 422 0;
BA_ "VFrameFormat" BO_ 422 14;
BA_ "CANFD_BRS" BO_ 422 1;
BA_ "GenMsgCycleTime" BO_ 422 10;
BA_ "GenMsgCycleTimeFast" BO_ 422 0;
BA_ "GenMsgSendType" BO_ 422 0;
BA_ "VFrameFormat" BO_ 422 14;
BA_ "CANFD_BRS" BO_ 422 1;
BA_ "GenMsgCycleTime" BO_ 422 10;
BA_ "GenMsgCycleTimeFast" BO_ 422 0;
BA_ "GenMsgSendType" BO_ 422 0;
BA_ "VFrameFormat" BO_ 422 14;
BA_ "CANFD_BRS" BO_ 422 1;
BA_ "GenMsgCycleTime" BO_ 422 10;
BA_ "GenMsgCycleTimeFast" BO_ 422 0;
BA_ "GenMsgSendType" BO_ 422 0;
BA_ "VFrameFormat" BO_ 422 14;
BA_ "CANFD_BRS" BO_ 422 1;
BA_ "GenMsgCycleTime" BO_ 422 10;
BA_ "GenMsgCycleTimeFast" BO_ 422 0;
BA_ "GenMsgSendType" BO_ 422 0;
BA_ "VFrameFormat" BO_ 422 14;
BA_ "CANFD_BRS" BO_ 422 1;
BA_ "GenMsgCycleTime" BO_ 422 10;
BA_ "GenMsgCycleTimeFast" BO_ 422 0;
BA_ "GenMsgSendType" BO_ 422 0;
BA_ "VFrameFormat" BO_ 422 14;
BA_ "CANFD_BRS" BO_ 422 1;
BA_ "GenMsgCycleTime" BO_ 422 10;
BA_ "GenMsgCycleTimeFast" BO_ 422 0;
BA_ "GenMsgSendType" BO_ 422 0;
BA_ "VFrameFormat" BO_ 422 14;
BA_ "CANFD_BRS" BO_ 422 1;
BA_ "GenMsgCycleTime" BO_ 422 10;
BA_ "GenMsgCycleTimeFast" BO_ 422 0;
BA_ "GenMsgSendType" BO_ 422 0;
BA_ "VFrameFormat" BO_ 422 14;
BA_ "CANFD_BRS" BO_ 422 1;
BA_ "GenMsgCycleTime" BO_ 422 10;
BA_ "GenMsgCycleTimeFast" BO_ 422 0;
BA_ "GenMsgSendType" BO_ 422 0;
BA_ "VFrameFormat" BO_ 422 14;
BA_ "CANFD_BRS" BO_ 422 1;
BA_ "GenMsgCycleTime" BO_ 422 10;
BA_ "GenMsgCycleTimeFast" BO_ 422 0;
BA_ "GenMsgSendType" BO_ 422 0;
BA_ "VFrameFormat" BO_ 422 14;
BA_ "CANFD_BRS" BO_ 422 1;
BA_ "GenMsgCycleTime" BO_ 422 10;
BA_ "GenMsgCycleTimeFast" BO_ 422 0;
BA_ "GenMsgSendType" BO_ 422 0;
BA_ "VFrameFormat" BO_ 422 14;
BA_ "CANFD_BRS" BO_ 422 1;
BA_ "GenMsgCycleTime" BO_ 422 10;
BA_ "GenMsgCycleTimeFast" BO_ 422 0;
BA_ "GenMsgSendType" BO_ 422 0;
BA_ "VFrameFormat" BO_ 422 14;
BA_ "CANFD_BRS" BO_ 422 1;
BA_ "GenMsgCycleTime" BO_ 619 20;
BA_ "GenMsgCycleTimeFast" BO_ 619 0;
BA_ "GenMsgSendType" BO_ 619 0;
BA_ "VFrameFormat" BO_ 619 14;
BA_ "CANFD_BRS" BO_ 619 1;
BA_ "GenMsgCycleTime" BO_ 619 20;
BA_ "GenMsgCycleTimeFast" BO_ 619 0;
BA_ "GenMsgSendType" BO_ 619 0;
BA_ "VFrameFormat" BO_ 619 14;
BA_ "CANFD_BRS" BO_ 619 1;
BA_ "GenMsgCycleTime" BO_ 619 20;
BA_ "GenMsgCycleTimeFast" BO_ 619 0;
BA_ "GenMsgSendType" BO_ 619 0;
BA_ "VFrameFormat" BO_ 619 14;
BA_ "CANFD_BRS" BO_ 619 1;
BA_ "GenMsgCycleTime" BO_ 1174 1000;
BA_ "GenMsgCycleTimeFast" BO_ 1174 0;
BA_ "GenMsgSendType" BO_ 1174 0;
BA_ "VFrameFormat" BO_ 1174 14;
BA_ "CANFD_BRS" BO_ 1174 1;
BA_ "GenMsgCycleTime" BO_ 728 100;
BA_ "GenMsgCycleTimeFast" BO_ 728 0;
BA_ "GenMsgSendType" BO_ 728 0;
BA_ "VFrameFormat" BO_ 728 14;
BA_ "CANFD_BRS" BO_ 728 1;
BA_ "GenMsgCycleTime" BO_ 728 100;
BA_ "GenMsgCycleTimeFast" BO_ 728 0;
BA_ "GenMsgSendType" BO_ 728 0;
BA_ "VFrameFormat" BO_ 728 14;
BA_ "CANFD_BRS" BO_ 728 1;
BA_ "GenMsgCycleTime" BO_ 728 100;
BA_ "GenMsgCycleTimeFast" BO_ 728 0;
BA_ "GenMsgSendType" BO_ 728 0;
BA_ "VFrameFormat" BO_ 728 14;
BA_ "CANFD_BRS" BO_ 728 1;
BA_ "GenMsgCycleTime" BO_ 728 100;
BA_ "GenMsgCycleTimeFast" BO_ 728 0;
BA_ "GenMsgSendType" BO_ 728 0;
BA_ "VFrameFormat" BO_ 728 14;
BA_ "CANFD_BRS" BO_ 728 1;
BA_ "GenMsgCycleTime" BO_ 728 100;
BA_ "GenMsgCycleTimeFast" BO_ 728 0;
BA_ "GenMsgSendType" BO_ 728 0;
BA_ "VFrameFormat" BO_ 728 14;
BA_ "CANFD_BRS" BO_ 728 1;
BA_ "GenMsgCycleTime" BO_ 728 100;
BA_ "GenMsgCycleTimeFast" BO_ 728 0;
BA_ "GenMsgSendType" BO_ 728 0;
BA_ "VFrameFormat" BO_ 728 14;
BA_ "CANFD_BRS" BO_ 728 1;
BA_ "GenMsgCycleTime" BO_ 728 100;
BA_ "GenMsgCycleTimeFast" BO_ 728 0;
BA_ "GenMsgSendType" BO_ 728 0;
BA_ "VFrameFormat" BO_ 728 14;
BA_ "CANFD_BRS" BO_ 728 1;
BA_ "GenMsgCycleTime" BO_ 728 100;
BA_ "GenMsgCycleTimeFast" BO_ 728 0;
BA_ "GenMsgSendType" BO_ 728 0;
BA_ "VFrameFormat" BO_ 728 14;
BA_ "CANFD_BRS" BO_ 728 1;
BA_ "GenMsgCycleTime" BO_ 728 100;
BA_ "GenMsgCycleTimeFast" BO_ 728 0;
BA_ "GenMsgSendType" BO_ 728 0;
BA_ "VFrameFormat" BO_ 728 14;
BA_ "CANFD_BRS" BO_ 728 1;
BA_ "GenMsgCycleTime" BO_ 728 100;
BA_ "GenMsgCycleTimeFast" BO_ 728 0;
BA_ "GenMsgSendType" BO_ 728 0;
BA_ "VFrameFormat" BO_ 728 14;
BA_ "CANFD_BRS" BO_ 728 1;
BA_ "GenMsgCycleTime" BO_ 728 100;
BA_ "GenMsgCycleTimeFast" BO_ 728 0;
BA_ "GenMsgSendType" BO_ 728 0;
BA_ "VFrameFormat" BO_ 728 14;
BA_ "CANFD_BRS" BO_ 728 1;
BA_ "GenMsgCycleTime" BO_ 728 100;
BA_ "GenMsgCycleTimeFast" BO_ 728 0;
BA_ "GenMsgSendType" BO_ 728 0;
BA_ "VFrameFormat" BO_ 728 14;
BA_ "CANFD_BRS" BO_ 728 1;
BA_ "GenMsgCycleTime" BO_ 728 100;
BA_ "GenMsgCycleTimeFast" BO_ 728 0;
BA_ "GenMsgSendType" BO_ 728 0;
BA_ "VFrameFormat" BO_ 728 14;
BA_ "CANFD_BRS" BO_ 728 1;
BA_ "GenMsgCycleTime" BO_ 728 100;
BA_ "GenMsgCycleTimeFast" BO_ 728 0;
BA_ "GenMsgSendType" BO_ 728 0;
BA_ "VFrameFormat" BO_ 728 14;
BA_ "CANFD_BRS" BO_ 728 1;
BA_ "GenMsgCycleTime" BO_ 728 100;
BA_ "GenMsgCycleTimeFast" BO_ 728 0;
BA_ "GenMsgSendType" BO_ 728 0;
BA_ "VFrameFormat" BO_ 728 14;
BA_ "CANFD_BRS" BO_ 728 1;
BA_ "GenMsgCycleTime" BO_ 728 100;
BA_ "GenMsgCycleTimeFast" BO_ 728 0;
BA_ "GenMsgSendType" BO_ 728 0;
BA_ "VFrameFormat" BO_ 728 14;
BA_ "CANFD_BRS" BO_ 728 1;
BA_ "GenMsgCycleTime" BO_ 728 100;
BA_ "GenMsgCycleTimeFast" BO_ 728 0;
BA_ "GenMsgSendType" BO_ 728 0;
BA_ "VFrameFormat" BO_ 728 14;
BA_ "CANFD_BRS" BO_ 728 1;
BA_ "GenMsgCycleTime" BO_ 459 20;
BA_ "GenMsgCycleTimeFast" BO_ 459 0;
BA_ "GenMsgSendType" BO_ 459 0;
BA_ "VFrameFormat" BO_ 459 14;
BA_ "CANFD_BRS" BO_ 459 1;
BA_ "GenMsgCycleTime" BO_ 459 20;
BA_ "GenMsgCycleTimeFast" BO_ 459 0;
BA_ "GenMsgSendType" BO_ 459 0;
BA_ "VFrameFormat" BO_ 459 14;
BA_ "CANFD_BRS" BO_ 459 1;
BA_ "GenMsgCycleTime" BO_ 459 20;
BA_ "GenMsgCycleTimeFast" BO_ 459 0;
BA_ "GenMsgSendType" BO_ 459 0;
BA_ "VFrameFormat" BO_ 459 14;
BA_ "CANFD_BRS" BO_ 459 1;
BA_ "GenMsgCycleTime" BO_ 459 20;
BA_ "GenMsgCycleTimeFast" BO_ 459 0;
BA_ "GenMsgSendType" BO_ 459 0;
BA_ "VFrameFormat" BO_ 459 14;
BA_ "CANFD_BRS" BO_ 459 1;
BA_ "GenMsgCycleTime" BO_ 459 20;
BA_ "GenMsgCycleTimeFast" BO_ 459 0;
BA_ "GenMsgSendType" BO_ 459 0;
BA_ "VFrameFormat" BO_ 459 14;
BA_ "CANFD_BRS" BO_ 459 1;
BA_ "GenMsgCycleTime" BO_ 459 20;
BA_ "GenMsgCycleTimeFast" BO_ 459 0;
BA_ "GenMsgSendType" BO_ 459 0;
BA_ "VFrameFormat" BO_ 459 14;
BA_ "CANFD_BRS" BO_ 459 1;
BA_ "GenMsgCycleTime" BO_ 459 20;
BA_ "GenMsgCycleTimeFast" BO_ 459 0;
BA_ "GenMsgSendType" BO_ 459 0;
BA_ "VFrameFormat" BO_ 459 14;
BA_ "CANFD_BRS" BO_ 459 1;
BA_ "GenMsgCycleTime" BO_ 459 20;
BA_ "GenMsgCycleTimeFast" BO_ 459 0;
BA_ "GenMsgSendType" BO_ 459 0;
BA_ "VFrameFormat" BO_ 459 14;
BA_ "CANFD_BRS" BO_ 459 1;
BA_ "GenMsgCycleTime" BO_ 459 20;
BA_ "GenMsgCycleTimeFast" BO_ 459 0;
BA_ "GenMsgSendType" BO_ 459 0;
BA_ "VFrameFormat" BO_ 459 14;
BA_ "CANFD_BRS" BO_ 459 1;
BA_ "GenMsgCycleTime" BO_ 459 20;
BA_ "GenMsgCycleTimeFast" BO_ 459 0;
BA_ "GenMsgSendType" BO_ 459 0;
BA_ "VFrameFormat" BO_ 459 14;
BA_ "CANFD_BRS" BO_ 459 1;
BA_ "GenMsgCycleTime" BO_ 459 20;
BA_ "GenMsgCycleTimeFast" BO_ 459 0;
BA_ "GenMsgSendType" BO_ 459 0;
BA_ "VFrameFormat" BO_ 459 14;
BA_ "CANFD_BRS" BO_ 459 1;
BA_ "GenMsgCycleTime" BO_ 459 20;
BA_ "GenMsgCycleTimeFast" BO_ 459 0;
BA_ "GenMsgSendType" BO_ 459 0;
BA_ "VFrameFormat" BO_ 459 14;
BA_ "CANFD_BRS" BO_ 459 1;
BA_ "GenMsgCycleTime" BO_ 459 20;
BA_ "GenMsgCycleTimeFast" BO_ 459 0;
BA_ "GenMsgSendType" BO_ 459 0;
BA_ "VFrameFormat" BO_ 459 14;
BA_ "CANFD_BRS" BO_ 459 1;
BA_ "GenMsgCycleTime" BO_ 459 20;
BA_ "GenMsgCycleTimeFast" BO_ 459 0;
BA_ "GenMsgSendType" BO_ 459 0;
BA_ "VFrameFormat" BO_ 459 14;
BA_ "CANFD_BRS" BO_ 459 1;
BA_ "GenMsgCycleTime" BO_ 459 20;
BA_ "GenMsgCycleTimeFast" BO_ 459 0;
BA_ "GenMsgSendType" BO_ 459 0;
BA_ "VFrameFormat" BO_ 459 14;
BA_ "CANFD_BRS" BO_ 459 1;
BA_ "GenMsgCycleTime" BO_ 459 20;
BA_ "GenMsgCycleTimeFast" BO_ 459 0;
BA_ "GenMsgSendType" BO_ 459 0;
BA_ "VFrameFormat" BO_ 459 14;
BA_ "CANFD_BRS" BO_ 459 1;
BA_ "GenMsgCycleTime" BO_ 459 20;
BA_ "GenMsgCycleTimeFast" BO_ 459 0;
BA_ "GenMsgSendType" BO_ 459 0;
BA_ "VFrameFormat" BO_ 459 14;
BA_ "CANFD_BRS" BO_ 459 1;
BA_ "GenMsgCycleTime" BO_ 459 20;
BA_ "GenMsgCycleTimeFast" BO_ 459 0;
BA_ "GenMsgSendType" BO_ 459 0;
BA_ "VFrameFormat" BO_ 459 14;
BA_ "CANFD_BRS" BO_ 459 1;
BA_ "GenMsgCycleTime" BO_ 459 20;
BA_ "GenMsgCycleTimeFast" BO_ 459 0;
BA_ "GenMsgSendType" BO_ 459 0;
BA_ "VFrameFormat" BO_ 459 14;
BA_ "CANFD_BRS" BO_ 459 1;
BA_ "GenMsgCycleTime" BO_ 459 20;
BA_ "GenMsgCycleTimeFast" BO_ 459 0;
BA_ "GenMsgSendType" BO_ 459 0;
BA_ "VFrameFormat" BO_ 459 14;
BA_ "CANFD_BRS" BO_ 459 1;
BA_ "GenMsgCycleTime" BO_ 459 20;
BA_ "GenMsgCycleTimeFast" BO_ 459 0;
BA_ "GenMsgSendType" BO_ 459 0;
BA_ "VFrameFormat" BO_ 459 14;
BA_ "CANFD_BRS" BO_ 459 1;
BA_ "GenMsgCycleTime" BO_ 459 20;
BA_ "GenMsgCycleTimeFast" BO_ 459 0;
BA_ "GenMsgSendType" BO_ 459 0;
BA_ "VFrameFormat" BO_ 459 14;
BA_ "CANFD_BRS" BO_ 459 1;
BA_ "GenMsgCycleTime" BO_ 459 20;
BA_ "GenMsgCycleTimeFast" BO_ 459 0;
BA_ "GenMsgSendType" BO_ 459 0;
BA_ "VFrameFormat" BO_ 459 14;
BA_ "CANFD_BRS" BO_ 459 1;
BA_ "GenMsgCycleTime" BO_ 459 20;
BA_ "GenMsgCycleTimeFast" BO_ 459 0;
BA_ "GenMsgSendType" BO_ 459 0;
BA_ "VFrameFormat" BO_ 459 14;
BA_ "CANFD_BRS" BO_ 459 1;
BA_ "GenMsgCycleTime" BO_ 459 20;
BA_ "GenMsgCycleTimeFast" BO_ 459 0;
BA_ "GenMsgSendType" BO_ 459 0;
BA_ "VFrameFormat" BO_ 459 14;
BA_ "CANFD_BRS" BO_ 459 1;
BA_ "GenMsgCycleTime" BO_ 459 20;
BA_ "GenMsgCycleTimeFast" BO_ 459 0;
BA_ "GenMsgSendType" BO_ 459 0;
BA_ "VFrameFormat" BO_ 459 14;
BA_ "CANFD_BRS" BO_ 459 1;
BA_ "GenMsgCycleTime" BO_ 459 20;
BA_ "GenMsgCycleTimeFast" BO_ 459 0;
BA_ "GenMsgSendType" BO_ 459 0;
BA_ "VFrameFormat" BO_ 459 14;
BA_ "CANFD_BRS" BO_ 459 1;
BA_ "GenMsgCycleTime" BO_ 459 20;
BA_ "GenMsgCycleTimeFast" BO_ 459 0;
BA_ "GenMsgSendType" BO_ 459 0;
BA_ "VFrameFormat" BO_ 459 14;
BA_ "CANFD_BRS" BO_ 459 1;
BA_ "GenMsgCycleTime" BO_ 459 20;
BA_ "GenMsgCycleTimeFast" BO_ 459 0;
BA_ "GenMsgSendType" BO_ 459 0;
BA_ "VFrameFormat" BO_ 459 14;
BA_ "CANFD_BRS" BO_ 459 1;
BA_ "GenMsgCycleTime" BO_ 459 20;
BA_ "GenMsgCycleTimeFast" BO_ 459 0;
BA_ "GenMsgSendType" BO_ 459 0;
BA_ "VFrameFormat" BO_ 459 14;
BA_ "CANFD_BRS" BO_ 459 1;
BA_ "GenMsgCycleTime" BO_ 459 20;
BA_ "GenMsgCycleTimeFast" BO_ 459 0;
BA_ "GenMsgSendType" BO_ 459 0;
BA_ "VFrameFormat" BO_ 459 14;
BA_ "CANFD_BRS" BO_ 459 1;
BA_ "GenMsgCycleTime" BO_ 459 20;
BA_ "GenMsgCycleTimeFast" BO_ 459 0;
BA_ "GenMsgSendType" BO_ 459 0;
BA_ "VFrameFormat" BO_ 459 14;
BA_ "CANFD_BRS" BO_ 459 1;
BA_ "GenMsgCycleTime" BO_ 359 10;
BA_ "GenMsgCycleTimeFast" BO_ 359 0;
BA_ "GenMsgSendType" BO_ 359 0;
BA_ "VFrameFormat" BO_ 359 14;
BA_ "CANFD_BRS" BO_ 359 1;
BA_ "GenMsgCycleTime" BO_ 359 10;
BA_ "GenMsgCycleTimeFast" BO_ 359 0;
BA_ "GenMsgSendType" BO_ 359 0;
BA_ "VFrameFormat" BO_ 359 14;
BA_ "CANFD_BRS" BO_ 359 1;
BA_ "GenMsgCycleTime" BO_ 359 10;
BA_ "GenMsgCycleTimeFast" BO_ 359 0;
BA_ "GenMsgSendType" BO_ 359 0;
BA_ "VFrameFormat" BO_ 359 14;
BA_ "CANFD_BRS" BO_ 359 1;
BA_ "GenMsgCycleTime" BO_ 359 10;
BA_ "GenMsgCycleTimeFast" BO_ 359 0;
BA_ "GenMsgSendType" BO_ 359 0;
BA_ "VFrameFormat" BO_ 359 14;
BA_ "CANFD_BRS" BO_ 359 1;
BA_ "GenMsgCycleTime" BO_ 359 10;
BA_ "GenMsgCycleTimeFast" BO_ 359 0;
BA_ "GenMsgSendType" BO_ 359 0;
BA_ "VFrameFormat" BO_ 359 14;
BA_ "CANFD_BRS" BO_ 359 1;
BA_ "GenMsgCycleTime" BO_ 359 10;
BA_ "GenMsgCycleTimeFast" BO_ 359 0;
BA_ "GenMsgSendType" BO_ 359 0;
BA_ "VFrameFormat" BO_ 359 14;
BA_ "CANFD_BRS" BO_ 359 1;
BA_ "GenMsgCycleTime" BO_ 359 10;
BA_ "GenMsgCycleTimeFast" BO_ 359 0;
BA_ "GenMsgSendType" BO_ 359 0;
BA_ "VFrameFormat" BO_ 359 14;
BA_ "CANFD_BRS" BO_ 359 1;
BA_ "GenMsgCycleTime" BO_ 359 10;
BA_ "GenMsgCycleTimeFast" BO_ 359 0;
BA_ "GenMsgSendType" BO_ 359 0;
BA_ "VFrameFormat" BO_ 359 14;
BA_ "CANFD_BRS" BO_ 359 1;
BA_ "GenMsgCycleTime" BO_ 359 10;
BA_ "GenMsgCycleTimeFast" BO_ 359 0;
BA_ "GenMsgSendType" BO_ 359 0;
BA_ "VFrameFormat" BO_ 359 14;
BA_ "CANFD_BRS" BO_ 359 1;
BA_ "GenMsgCycleTime" BO_ 359 10;
BA_ "GenMsgCycleTimeFast" BO_ 359 0;
BA_ "GenMsgSendType" BO_ 359 0;
BA_ "VFrameFormat" BO_ 359 14;
BA_ "CANFD_BRS" BO_ 359 1;
BA_ "GenMsgCycleTime" BO_ 359 10;
BA_ "GenMsgCycleTimeFast" BO_ 359 0;
BA_ "GenMsgSendType" BO_ 359 0;
BA_ "VFrameFormat" BO_ 359 14;
BA_ "CANFD_BRS" BO_ 359 1;
BA_ "GenMsgCycleTime" BO_ 359 10;
BA_ "GenMsgCycleTimeFast" BO_ 359 0;
BA_ "GenMsgSendType" BO_ 359 0;
BA_ "VFrameFormat" BO_ 359 14;
BA_ "CANFD_BRS" BO_ 359 1;
BA_ "GenMsgCycleTime" BO_ 359 10;
BA_ "GenMsgCycleTimeFast" BO_ 359 0;
BA_ "GenMsgSendType" BO_ 359 0;
BA_ "VFrameFormat" BO_ 359 14;
BA_ "CANFD_BRS" BO_ 359 1;
BA_ "GenMsgCycleTime" BO_ 359 10;
BA_ "GenMsgCycleTimeFast" BO_ 359 0;
BA_ "GenMsgSendType" BO_ 359 0;
BA_ "VFrameFormat" BO_ 359 14;
BA_ "CANFD_BRS" BO_ 359 1;
BA_ "GenMsgCycleTime" BO_ 359 10;
BA_ "GenMsgCycleTimeFast" BO_ 359 0;
BA_ "GenMsgSendType" BO_ 359 0;
BA_ "VFrameFormat" BO_ 359 14;
BA_ "CANFD_BRS" BO_ 359 1;
BA_ "GenMsgCycleTime" BO_ 359 10;
BA_ "GenMsgCycleTimeFast" BO_ 359 0;
BA_ "GenMsgSendType" BO_ 359 0;
BA_ "VFrameFormat" BO_ 359 14;
BA_ "CANFD_BRS" BO_ 359 1;
BA_ "GenMsgCycleTime" BO_ 359 10;
BA_ "GenMsgCycleTimeFast" BO_ 359 0;
BA_ "GenMsgSendType" BO_ 359 0;
BA_ "VFrameFormat" BO_ 359 14;
BA_ "CANFD_BRS" BO_ 359 1;
BA_ "GenMsgCycleTime" BO_ 359 10;
BA_ "GenMsgCycleTimeFast" BO_ 359 0;
BA_ "GenMsgSendType" BO_ 359 0;
BA_ "VFrameFormat" BO_ 359 14;
BA_ "CANFD_BRS" BO_ 359 1;
BA_ "GenMsgCycleTime" BO_ 359 10;
BA_ "GenMsgCycleTimeFast" BO_ 359 0;
BA_ "GenMsgSendType" BO_ 359 0;
BA_ "VFrameFormat" BO_ 359 14;
BA_ "CANFD_BRS" BO_ 359 1;
BA_ "GenMsgCycleTime" BO_ 359 10;
BA_ "GenMsgCycleTimeFast" BO_ 359 0;
BA_ "GenMsgSendType" BO_ 359 0;
BA_ "VFrameFormat" BO_ 359 14;
BA_ "CANFD_BRS" BO_ 359 1;
BA_ "GenMsgCycleTime" BO_ 359 10;
BA_ "GenMsgCycleTimeFast" BO_ 359 0;
BA_ "GenMsgSendType" BO_ 359 0;
BA_ "VFrameFormat" BO_ 359 14;
BA_ "CANFD_BRS" BO_ 359 1;
BA_ "GenMsgCycleTime" BO_ 359 10;
BA_ "GenMsgCycleTimeFast" BO_ 359 0;
BA_ "GenMsgSendType" BO_ 359 0;
BA_ "VFrameFormat" BO_ 359 14;
BA_ "CANFD_BRS" BO_ 359 1;
BA_ "GenMsgCycleTime" BO_ 359 10;
BA_ "GenMsgCycleTimeFast" BO_ 359 0;
BA_ "GenMsgSendType" BO_ 359 0;
BA_ "VFrameFormat" BO_ 359 14;
BA_ "CANFD_BRS" BO_ 359 1;
BA_ "GenMsgCycleTime" BO_ 359 10;
BA_ "GenMsgCycleTimeFast" BO_ 359 0;
BA_ "GenMsgSendType" BO_ 359 0;
BA_ "VFrameFormat" BO_ 359 14;
BA_ "CANFD_BRS" BO_ 359 1;
BA_ "GenMsgCycleTime" BO_ 359 10;
BA_ "GenMsgCycleTimeFast" BO_ 359 0;
BA_ "GenMsgSendType" BO_ 359 0;
BA_ "VFrameFormat" BO_ 359 14;
BA_ "CANFD_BRS" BO_ 359 1;
BA_ "GenMsgCycleTime" BO_ 359 10;
BA_ "GenMsgCycleTimeFast" BO_ 359 0;
BA_ "GenMsgSendType" BO_ 359 0;
BA_ "VFrameFormat" BO_ 359 14;
BA_ "CANFD_BRS" BO_ 359 1;
BA_ "GenMsgCycleTime" BO_ 359 10;
BA_ "GenMsgCycleTimeFast" BO_ 359 0;
BA_ "GenMsgSendType" BO_ 359 0;
BA_ "VFrameFormat" BO_ 359 14;
BA_ "CANFD_BRS" BO_ 359 1;
BA_ "GenMsgCycleTime" BO_ 359 10;
BA_ "GenMsgCycleTimeFast" BO_ 359 0;
BA_ "GenMsgSendType" BO_ 359 0;
BA_ "VFrameFormat" BO_ 359 14;
BA_ "CANFD_BRS" BO_ 359 1;
BA_ "GenMsgCycleTime" BO_ 359 10;
BA_ "GenMsgCycleTimeFast" BO_ 359 0;
BA_ "GenMsgSendType" BO_ 359 0;
BA_ "VFrameFormat" BO_ 359 14;
BA_ "CANFD_BRS" BO_ 359 1;
BA_ "GenMsgCycleTime" BO_ 359 10;
BA_ "GenMsgCycleTimeFast" BO_ 359 0;
BA_ "GenMsgSendType" BO_ 359 0;
BA_ "VFrameFormat" BO_ 359 14;
BA_ "CANFD_BRS" BO_ 359 1;
BA_ "GenMsgCycleTime" BO_ 359 10;
BA_ "GenMsgCycleTimeFast" BO_ 359 0;
BA_ "GenMsgSendType" BO_ 359 0;
BA_ "VFrameFormat" BO_ 359 14;
BA_ "CANFD_BRS" BO_ 359 1;
BA_ "GenMsgCycleTime" BO_ 359 10;
BA_ "GenMsgCycleTimeFast" BO_ 359 0;
BA_ "GenMsgSendType" BO_ 359 0;
BA_ "VFrameFormat" BO_ 359 14;
BA_ "CANFD_BRS" BO_ 359 1;
BA_ "GenMsgCycleTime" BO_ 359 10;
BA_ "GenMsgCycleTimeFast" BO_ 359 0;
BA_ "GenMsgSendType" BO_ 359 0;
BA_ "VFrameFormat" BO_ 359 14;
BA_ "CANFD_BRS" BO_ 359 1;
BA_ "GenMsgCycleTime" BO_ 359 10;
BA_ "GenMsgCycleTimeFast" BO_ 359 0;
BA_ "GenMsgSendType" BO_ 359 0;
BA_ "VFrameFormat" BO_ 359 14;
BA_ "CANFD_BRS" BO_ 359 1;
BA_ "GenMsgCycleTime" BO_ 359 10;
BA_ "GenMsgCycleTimeFast" BO_ 359 0;
BA_ "GenMsgSendType" BO_ 359 0;
BA_ "VFrameFormat" BO_ 359 14;
BA_ "CANFD_BRS" BO_ 359 1;
BA_ "GenMsgCycleTime" BO_ 359 10;
BA_ "GenMsgCycleTimeFast" BO_ 359 0;
BA_ "GenMsgSendType" BO_ 359 0;
BA_ "VFrameFormat" BO_ 359 14;
BA_ "CANFD_BRS" BO_ 359 1;
BA_ "GenMsgCycleTime" BO_ 359 10;
BA_ "GenMsgCycleTimeFast" BO_ 359 0;
BA_ "GenMsgSendType" BO_ 359 0;
BA_ "VFrameFormat" BO_ 359 14;
BA_ "CANFD_BRS" BO_ 359 1;
BA_ "GenMsgCycleTime" BO_ 359 10;
BA_ "GenMsgCycleTimeFast" BO_ 359 0;
BA_ "GenMsgSendType" BO_ 359 0;
BA_ "VFrameFormat" BO_ 359 14;
BA_ "CANFD_BRS" BO_ 359 1;
BA_ "GenMsgCycleTime" BO_ 359 10;
BA_ "GenMsgCycleTimeFast" BO_ 359 0;
BA_ "GenMsgSendType" BO_ 359 0;
BA_ "VFrameFormat" BO_ 359 14;
BA_ "CANFD_BRS" BO_ 359 1;
BA_ "GenMsgCycleTime" BO_ 359 10;
BA_ "GenMsgCycleTimeFast" BO_ 359 0;
BA_ "GenMsgSendType" BO_ 359 0;
BA_ "VFrameFormat" BO_ 359 14;
BA_ "CANFD_BRS" BO_ 359 1;
BA_ "GenMsgCycleTime" BO_ 359 10;
BA_ "GenMsgCycleTimeFast" BO_ 359 0;
BA_ "GenMsgSendType" BO_ 359 0;
BA_ "VFrameFormat" BO_ 359 14;
BA_ "CANFD_BRS" BO_ 359 1;
BA_ "GenMsgCycleTime" BO_ 359 10;
BA_ "GenMsgCycleTimeFast" BO_ 359 0;
BA_ "GenMsgSendType" BO_ 359 0;
BA_ "VFrameFormat" BO_ 359 14;
BA_ "CANFD_BRS" BO_ 359 1;
BA_ "GenMsgCycleTime" BO_ 359 10;
BA_ "GenMsgCycleTimeFast" BO_ 359 0;
BA_ "GenMsgSendType" BO_ 359 0;
BA_ "VFrameFormat" BO_ 359 14;
BA_ "CANFD_BRS" BO_ 359 1;
BA_ "GenMsgCycleTime" BO_ 359 10;
BA_ "GenMsgCycleTimeFast" BO_ 359 0;
BA_ "GenMsgSendType" BO_ 359 0;
BA_ "VFrameFormat" BO_ 359 14;
BA_ "CANFD_BRS" BO_ 359 1;
BA_ "GenMsgCycleTime" BO_ 359 10;
BA_ "GenMsgCycleTimeFast" BO_ 359 0;
BA_ "GenMsgSendType" BO_ 359 0;
BA_ "VFrameFormat" BO_ 359 14;
BA_ "CANFD_BRS" BO_ 359 1;
BA_ "GenMsgCycleTime" BO_ 359 10;
BA_ "GenMsgCycleTimeFast" BO_ 359 0;
BA_ "GenMsgSendType" BO_ 359 0;
BA_ "VFrameFormat" BO_ 359 14;
BA_ "CANFD_BRS" BO_ 359 1;
BA_ "GenMsgCycleTime" BO_ 359 10;
BA_ "GenMsgCycleTimeFast" BO_ 359 0;
BA_ "GenMsgSendType" BO_ 359 0;
BA_ "VFrameFormat" BO_ 359 14;
BA_ "CANFD_BRS" BO_ 359 1;
BA_ "GenMsgCycleTime" BO_ 359 10;
BA_ "GenMsgCycleTimeFast" BO_ 359 0;
BA_ "GenMsgSendType" BO_ 359 0;
BA_ "VFrameFormat" BO_ 359 14;
BA_ "CANFD_BRS" BO_ 359 1;
BA_ "GenMsgCycleTime" BO_ 359 10;
BA_ "GenMsgCycleTimeFast" BO_ 359 0;
BA_ "GenMsgSendType" BO_ 359 0;
BA_ "VFrameFormat" BO_ 359 14;
BA_ "CANFD_BRS" BO_ 359 1;
BA_ "GenMsgCycleTime" BO_ 359 10;
BA_ "GenMsgCycleTimeFast" BO_ 359 0;
BA_ "GenMsgSendType" BO_ 359 0;
BA_ "VFrameFormat" BO_ 359 14;
BA_ "CANFD_BRS" BO_ 359 1;
BA_ "GenMsgCycleTime" BO_ 359 10;
BA_ "GenMsgCycleTimeFast" BO_ 359 0;
BA_ "GenMsgSendType" BO_ 359 0;
BA_ "VFrameFormat" BO_ 359 14;
BA_ "CANFD_BRS" BO_ 359 1;
BA_ "GenMsgCycleTime" BO_ 359 10;
BA_ "GenMsgCycleTimeFast" BO_ 359 0;
BA_ "GenMsgSendType" BO_ 359 0;
BA_ "VFrameFormat" BO_ 359 14;
BA_ "CANFD_BRS" BO_ 359 1;
BA_ "GenMsgCycleTime" BO_ 359 10;
BA_ "GenMsgCycleTimeFast" BO_ 359 0;
BA_ "GenMsgSendType" BO_ 359 0;
BA_ "VFrameFormat" BO_ 359 14;
BA_ "CANFD_BRS" BO_ 359 1;
BA_ "GenMsgCycleTime" BO_ 359 10;
BA_ "GenMsgCycleTimeFast" BO_ 359 0;
BA_ "GenMsgSendType" BO_ 359 0;
BA_ "VFrameFormat" BO_ 359 14;
BA_ "CANFD_BRS" BO_ 359 1;
BA_ "GenMsgCycleTime" BO_ 359 10;
BA_ "GenMsgCycleTimeFast" BO_ 359 0;
BA_ "GenMsgSendType" BO_ 359 0;
BA_ "VFrameFormat" BO_ 359 14;
BA_ "CANFD_BRS" BO_ 359 1;
BA_ "GenMsgCycleTime" BO_ 359 10;
BA_ "GenMsgCycleTimeFast" BO_ 359 0;
BA_ "GenMsgSendType" BO_ 359 0;
BA_ "VFrameFormat" BO_ 359 14;
BA_ "CANFD_BRS" BO_ 359 1;
BA_ "GenMsgCycleTime" BO_ 1359 200;
BA_ "GenMsgCycleTimeFast" BO_ 1359 0;
BA_ "GenMsgSendType" BO_ 1359 0;
BA_ "VFrameFormat" BO_ 1359 0;
BA_ "CANFD_BRS" BO_ 1359 1;
BA_ "GenMsgCycleTime" BO_ 1359 200;
BA_ "GenMsgCycleTimeFast" BO_ 1359 0;
BA_ "GenMsgSendType" BO_ 1359 0;
BA_ "VFrameFormat" BO_ 1359 0;
BA_ "CANFD_BRS" BO_ 1359 1;
BA_ "GenMsgCycleTime" BO_ 1359 200;
BA_ "GenMsgCycleTimeFast" BO_ 1359 0;
BA_ "GenMsgSendType" BO_ 1359 0;
BA_ "VFrameFormat" BO_ 1359 0;
BA_ "CANFD_BRS" BO_ 1359 1;
BA_ "GenMsgCycleTime" BO_ 1359 200;
BA_ "GenMsgCycleTimeFast" BO_ 1359 0;
BA_ "GenMsgSendType" BO_ 1359 0;
BA_ "VFrameFormat" BO_ 1359 0;
BA_ "CANFD_BRS" BO_ 1359 1;
BA_ "GenMsgCycleTime" BO_ 1359 200;
BA_ "GenMsgCycleTimeFast" BO_ 1359 0;
BA_ "GenMsgSendType" BO_ 1359 0;
BA_ "VFrameFormat" BO_ 1359 0;
BA_ "CANFD_BRS" BO_ 1359 1;
BA_ "GenMsgCycleTime" BO_ 1359 200;
BA_ "GenMsgCycleTimeFast" BO_ 1359 0;
BA_ "GenMsgSendType" BO_ 1359 0;
BA_ "VFrameFormat" BO_ 1359 0;
BA_ "CANFD_BRS" BO_ 1359 1;
BA_ "GenMsgCycleTime" BO_ 1290 200;
BA_ "GenMsgCycleTimeFast" BO_ 1290 0;
BA_ "GenMsgSendType" BO_ 1290 0;
BA_ "VFrameFormat" BO_ 1290 0;
BA_ "CANFD_BRS" BO_ 1290 1;
BA_ "GenMsgCycleTime" BO_ 1290 200;
BA_ "GenMsgCycleTimeFast" BO_ 1290 0;
BA_ "GenMsgSendType" BO_ 1290 0;
BA_ "VFrameFormat" BO_ 1290 0;
BA_ "CANFD_BRS" BO_ 1290 1;
BA_ "GenMsgCycleTime" BO_ 1290 200;
BA_ "GenMsgCycleTimeFast" BO_ 1290 0;
BA_ "GenMsgSendType" BO_ 1290 0;
BA_ "VFrameFormat" BO_ 1290 0;
BA_ "CANFD_BRS" BO_ 1290 1;
BA_ "GenMsgCycleTime" BO_ 1290 200;
BA_ "GenMsgCycleTimeFast" BO_ 1290 0;
BA_ "GenMsgSendType" BO_ 1290 0;
BA_ "VFrameFormat" BO_ 1290 0;
BA_ "CANFD_BRS" BO_ 1290 1;
BA_ "GenMsgCycleTime" BO_ 1290 200;
BA_ "GenMsgCycleTimeFast" BO_ 1290 0;
BA_ "GenMsgSendType" BO_ 1290 0;
BA_ "VFrameFormat" BO_ 1290 0;
BA_ "CANFD_BRS" BO_ 1290 1;
BA_ "GenMsgCycleTime" BO_ 1290 200;
BA_ "GenMsgCycleTimeFast" BO_ 1290 0;
BA_ "GenMsgSendType" BO_ 1290 0;
BA_ "VFrameFormat" BO_ 1290 0;
BA_ "CANFD_BRS" BO_ 1290 1;
BA_ "GenMsgCycleTime" BO_ 1294 200;
BA_ "GenMsgCycleTimeFast" BO_ 1294 0;
BA_ "GenMsgSendType" BO_ 1294 0;
BA_ "VFrameFormat" BO_ 1294 0;
BA_ "CANFD_BRS" BO_ 1294 1;
BA_ "GenMsgCycleTime" BO_ 1294 200;
BA_ "GenMsgCycleTimeFast" BO_ 1294 0;
BA_ "GenMsgSendType" BO_ 1294 0;
BA_ "VFrameFormat" BO_ 1294 0;
BA_ "CANFD_BRS" BO_ 1294 1;
BA_ "GenMsgCycleTime" BO_ 1294 200;
BA_ "GenMsgCycleTimeFast" BO_ 1294 0;
BA_ "GenMsgSendType" BO_ 1294 0;
BA_ "VFrameFormat" BO_ 1294 0;
BA_ "CANFD_BRS" BO_ 1294 1;
BA_ "GenMsgCycleTime" BO_ 1294 200;
BA_ "GenMsgCycleTimeFast" BO_ 1294 0;
BA_ "GenMsgSendType" BO_ 1294 0;
BA_ "VFrameFormat" BO_ 1294 0;
BA_ "CANFD_BRS" BO_ 1294 1;
BA_ "GenMsgCycleTime" BO_ 1294 200;
BA_ "GenMsgCycleTimeFast" BO_ 1294 0;
BA_ "GenMsgSendType" BO_ 1294 0;
BA_ "VFrameFormat" BO_ 1294 0;
BA_ "CANFD_BRS" BO_ 1294 1;
BA_ "GenMsgCycleTime" BO_ 1294 200;
BA_ "GenMsgCycleTimeFast" BO_ 1294 0;
BA_ "GenMsgSendType" BO_ 1294 0;
BA_ "VFrameFormat" BO_ 1294 0;
BA_ "CANFD_BRS" BO_ 1294 1;
BA_ "GenMsgCycleTime" BO_ 1406 200;
BA_ "GenMsgCycleTimeFast" BO_ 1406 0;
BA_ "GenMsgSendType" BO_ 1406 0;
BA_ "VFrameFormat" BO_ 1406 0;
BA_ "CANFD_BRS" BO_ 1406 1;
BA_ "GenMsgCycleTime" BO_ 1406 200;
BA_ "GenMsgCycleTimeFast" BO_ 1406 0;
BA_ "GenMsgSendType" BO_ 1406 0;
BA_ "VFrameFormat" BO_ 1406 0;
BA_ "CANFD_BRS" BO_ 1406 1;
BA_ "GenMsgCycleTime" BO_ 1406 200;
BA_ "GenMsgCycleTimeFast" BO_ 1406 0;
BA_ "GenMsgSendType" BO_ 1406 0;
BA_ "VFrameFormat" BO_ 1406 0;
BA_ "CANFD_BRS" BO_ 1406 1;
BA_ "GenMsgCycleTime" BO_ 1406 200;
BA_ "GenMsgCycleTimeFast" BO_ 1406 0;
BA_ "GenMsgSendType" BO_ 1406 0;
BA_ "VFrameFormat" BO_ 1406 0;
BA_ "CANFD_BRS" BO_ 1406 1;
BA_ "GenMsgCycleTime" BO_ 1406 200;
BA_ "GenMsgCycleTimeFast" BO_ 1406 0;
BA_ "GenMsgSendType" BO_ 1406 0;
BA_ "VFrameFormat" BO_ 1406 0;
BA_ "CANFD_BRS" BO_ 1406 1;
BA_ "GenMsgCycleTime" BO_ 1406 200;
BA_ "GenMsgCycleTimeFast" BO_ 1406 0;
BA_ "GenMsgSendType" BO_ 1406 0;
BA_ "VFrameFormat" BO_ 1406 0;
BA_ "CANFD_BRS" BO_ 1406 1;
BA_ "GenMsgCycleTime" BO_ 2015 0;
BA_ "GenMsgCycleTimeFast" BO_ 2015 0;
BA_ "GenMsgSendType" BO_ 2015 1;
BA_ "VFrameFormat" BO_ 2015 14;
BA_ "CANFD_BRS" BO_ 2015 1;
BA_ "EventCommandSignal" SG_ 371 ADC_13_B_CRC 0;
BA_ "GatewayedSignals" SG_ 371 ADC_13_B_CRC 0;
BA_ "GenSigInactiveValue" SG_ 371 ADC_13_B_CRC 0;
BA_ "GenSigInvalidValue" SG_ 371 ADC_13_B_CRC 0;
BA_ "GenSigSendType" SG_ 371 ADC_13_B_CRC 1;
BA_ "GenSigStartValue" SG_ 371 ADC_13_B_CRC 0;
BA_ "GenSigTimeoutValue" SG_ 371 ADC_13_B_CRC 0;
BA_ "Remark" SG_ 371 ADC_13_B_CRC "";
BA_ "EventCommandSignal" SG_ 371 ADC_13_B_Counter 0;
BA_ "GatewayedSignals" SG_ 371 ADC_13_B_Counter 0;
BA_ "GenSigInactiveValue" SG_ 371 ADC_13_B_Counter 0;
BA_ "GenSigInvalidValue" SG_ 371 ADC_13_B_Counter 0;
BA_ "GenSigSendType" SG_ 371 ADC_13_B_Counter 1;
BA_ "GenSigStartValue" SG_ 371 ADC_13_B_Counter 0;
BA_ "GenSigTimeoutValue" SG_ 371 ADC_13_B_Counter 0;
BA_ "Remark" SG_ 371 ADC_13_B_Counter "";
BA_ "EventCommandSignal" SG_ 371 ADC_DycEscTarTq 0;
BA_ "GatewayedSignals" SG_ 371 ADC_DycEscTarTq 0;
BA_ "GenSigInactiveValue" SG_ 371 ADC_DycEscTarTq 0;
BA_ "GenSigInvalidValue" SG_ 371 ADC_DycEscTarTq 0;
BA_ "GenSigSendType" SG_ 371 ADC_DycEscTarTq 1;
BA_ "GenSigStartValue" SG_ 371 ADC_DycEscTarTq 0;
BA_ "GenSigTimeoutValue" SG_ 371 ADC_DycEscTarTq 0;
BA_ "Remark" SG_ 371 ADC_DycEscTarTq "";
BA_ "EventCommandSignal" SG_ 371 ADC_DycEscTarTqfactor 0;
BA_ "GatewayedSignals" SG_ 371 ADC_DycEscTarTqfactor 0;
BA_ "GenSigInactiveValue" SG_ 371 ADC_DycEscTarTqfactor 0;
BA_ "GenSigInvalidValue" SG_ 371 ADC_DycEscTarTqfactor 0;
BA_ "GenSigSendType" SG_ 371 ADC_DycEscTarTqfactor 1;
BA_ "GenSigStartValue" SG_ 371 ADC_DycEscTarTqfactor 0;
BA_ "GenSigTimeoutValue" SG_ 371 ADC_DycEscTarTqfactor 0;
BA_ "Remark" SG_ 371 ADC_DycEscTarTqfactor "";
BA_ "EventCommandSignal" SG_ 371 ADC_SteerTqReq 0;
BA_ "GatewayedSignals" SG_ 371 ADC_SteerTqReq 0;
BA_ "GenSigInactiveValue" SG_ 371 ADC_SteerTqReq 0;
BA_ "GenSigInvalidValue" SG_ 371 ADC_SteerTqReq 4095;
BA_ "GenSigSendType" SG_ 371 ADC_SteerTqReq 1;
BA_ "GenSigStartValue" SG_ 371 ADC_SteerTqReq 2000;
BA_ "GenSigTimeoutValue" SG_ 371 ADC_SteerTqReq 4095;
BA_ "Remark" SG_ 371 ADC_SteerTqReq "";
BA_ "EventCommandSignal" SG_ 371 ADC_SteerTqSt 0;
BA_ "GatewayedSignals" SG_ 371 ADC_SteerTqSt 0;
BA_ "GenSigInactiveValue" SG_ 371 ADC_SteerTqSt 0;
BA_ "GenSigInvalidValue" SG_ 371 ADC_SteerTqSt 0;
BA_ "GenSigSendType" SG_ 371 ADC_SteerTqSt 1;
BA_ "GenSigStartValue" SG_ 371 ADC_SteerTqSt 0;
BA_ "GenSigTimeoutValue" SG_ 371 ADC_SteerTqSt 0;
BA_ "Remark" SG_ 371 ADC_SteerTqSt "";
BA_ "EventCommandSignal" SG_ 371 ADC_SteerTqAvl 0;
BA_ "GatewayedSignals" SG_ 371 ADC_SteerTqAvl 0;
BA_ "GenSigInactiveValue" SG_ 371 ADC_SteerTqAvl 0;
BA_ "GenSigInvalidValue" SG_ 371 ADC_SteerTqAvl 0;
BA_ "GenSigSendType" SG_ 371 ADC_SteerTqAvl 1;
BA_ "GenSigStartValue" SG_ 371 ADC_SteerTqAvl 0;
BA_ "GenSigTimeoutValue" SG_ 371 ADC_SteerTqAvl 0;
BA_ "Remark" SG_ 371 ADC_SteerTqAvl "";
BA_ "EventCommandSignal" SG_ 371 ADC_DycEscTarTqVld 0;
BA_ "GatewayedSignals" SG_ 371 ADC_DycEscTarTqVld 0;
BA_ "GenSigInactiveValue" SG_ 371 ADC_DycEscTarTqVld 0;
BA_ "GenSigInvalidValue" SG_ 371 ADC_DycEscTarTqVld 0;
BA_ "GenSigSendType" SG_ 371 ADC_DycEscTarTqVld 1;
BA_ "GenSigStartValue" SG_ 371 ADC_DycEscTarTqVld 0;
BA_ "GenSigTimeoutValue" SG_ 371 ADC_DycEscTarTqVld 0;
BA_ "Remark" SG_ 371 ADC_DycEscTarTqVld "";
BA_ "EventCommandSignal" SG_ 371 ADC_DycEscTarTqEna 0;
BA_ "GatewayedSignals" SG_ 371 ADC_DycEscTarTqEna 0;
BA_ "GenSigInactiveValue" SG_ 371 ADC_DycEscTarTqEna 0;
BA_ "GenSigInvalidValue" SG_ 371 ADC_DycEscTarTqEna 0;
BA_ "GenSigSendType" SG_ 371 ADC_DycEscTarTqEna 1;
BA_ "GenSigStartValue" SG_ 371 ADC_DycEscTarTqEna 0;
BA_ "GenSigTimeoutValue" SG_ 371 ADC_DycEscTarTqEna 0;
BA_ "Remark" SG_ 371 ADC_DycEscTarTqEna "";
BA_ "EventCommandSignal" SG_ 371 ADC_TotalRefTorque 0;
BA_ "GatewayedSignals" SG_ 371 ADC_TotalRefTorque 0;
BA_ "GenSigInactiveValue" SG_ 371 ADC_TotalRefTorque 0;
BA_ "GenSigInvalidValue" SG_ 371 ADC_TotalRefTorque 0;
BA_ "GenSigSendType" SG_ 371 ADC_TotalRefTorque 1;
BA_ "GenSigStartValue" SG_ 371 ADC_TotalRefTorque 0;
BA_ "GenSigTimeoutValue" SG_ 371 ADC_TotalRefTorque 0;
BA_ "Remark" SG_ 371 ADC_TotalRefTorque "";
BA_ "EventCommandSignal" SG_ 371 ADC_MotTarSpd 0;
BA_ "GatewayedSignals" SG_ 371 ADC_MotTarSpd 0;
BA_ "GenSigInactiveValue" SG_ 371 ADC_MotTarSpd 0;
BA_ "GenSigInvalidValue" SG_ 371 ADC_MotTarSpd 0;
BA_ "GenSigSendType" SG_ 371 ADC_MotTarSpd 1;
BA_ "GenSigStartValue" SG_ 371 ADC_MotTarSpd 0;
BA_ "GenSigTimeoutValue" SG_ 371 ADC_MotTarSpd 0;
BA_ "Remark" SG_ 371 ADC_MotTarSpd "";
BA_ "EventCommandSignal" SG_ 371 ADC_LimTqFactorK 0;
BA_ "GatewayedSignals" SG_ 371 ADC_LimTqFactorK 0;
BA_ "GenSigInactiveValue" SG_ 371 ADC_LimTqFactorK 0;
BA_ "GenSigInvalidValue" SG_ 371 ADC_LimTqFactorK 0;
BA_ "GenSigSendType" SG_ 371 ADC_LimTqFactorK 1;
BA_ "GenSigStartValue" SG_ 371 ADC_LimTqFactorK 0;
BA_ "GenSigTimeoutValue" SG_ 371 ADC_LimTqFactorK 0;
BA_ "Remark" SG_ 371 ADC_LimTqFactorK "";
BA_ "EventCommandSignal" SG_ 371 ADC_MotTqLimMin 0;
BA_ "GatewayedSignals" SG_ 371 ADC_MotTqLimMin 0;
BA_ "GenSigInactiveValue" SG_ 371 ADC_MotTqLimMin 0;
BA_ "GenSigInvalidValue" SG_ 371 ADC_MotTqLimMin 0;
BA_ "GenSigSendType" SG_ 371 ADC_MotTqLimMin 1;
BA_ "GenSigStartValue" SG_ 371 ADC_MotTqLimMin 0;
BA_ "GenSigTimeoutValue" SG_ 371 ADC_MotTqLimMin 0;
BA_ "Remark" SG_ 371 ADC_MotTqLimMin "";
BA_ "EventCommandSignal" SG_ 371 ADC_MotTqLimMax 0;
BA_ "GatewayedSignals" SG_ 371 ADC_MotTqLimMax 0;
BA_ "GenSigInactiveValue" SG_ 371 ADC_MotTqLimMax 0;
BA_ "GenSigInvalidValue" SG_ 371 ADC_MotTqLimMax 0;
BA_ "GenSigSendType" SG_ 371 ADC_MotTqLimMax 1;
BA_ "GenSigStartValue" SG_ 371 ADC_MotTqLimMax 0;
BA_ "GenSigTimeoutValue" SG_ 371 ADC_MotTqLimMax 0;
BA_ "Remark" SG_ 371 ADC_MotTqLimMax "";
BA_ "EventCommandSignal" SG_ 371 ADC_MotTqRateLimMin 0;
BA_ "GatewayedSignals" SG_ 371 ADC_MotTqRateLimMin 0;
BA_ "GenSigInactiveValue" SG_ 371 ADC_MotTqRateLimMin 0;
BA_ "GenSigInvalidValue" SG_ 371 ADC_MotTqRateLimMin 0;
BA_ "GenSigSendType" SG_ 371 ADC_MotTqRateLimMin 1;
BA_ "GenSigStartValue" SG_ 371 ADC_MotTqRateLimMin 0;
BA_ "GenSigTimeoutValue" SG_ 371 ADC_MotTqRateLimMin 0;
BA_ "Remark" SG_ 371 ADC_MotTqRateLimMin "";
BA_ "EventCommandSignal" SG_ 371 ADC_MotTqRateLimMax 0;
BA_ "GatewayedSignals" SG_ 371 ADC_MotTqRateLimMax 0;
BA_ "GenSigInactiveValue" SG_ 371 ADC_MotTqRateLimMax 0;
BA_ "GenSigInvalidValue" SG_ 371 ADC_MotTqRateLimMax 0;
BA_ "GenSigSendType" SG_ 371 ADC_MotTqRateLimMax 1;
BA_ "GenSigStartValue" SG_ 371 ADC_MotTqRateLimMax 0;
BA_ "GenSigTimeoutValue" SG_ 371 ADC_MotTqRateLimMax 0;
BA_ "Remark" SG_ 371 ADC_MotTqRateLimMax "";
BA_ "EventCommandSignal" SG_ 371 ADC_TqUnloadRate 0;
BA_ "GatewayedSignals" SG_ 371 ADC_TqUnloadRate 0;
BA_ "GenSigInactiveValue" SG_ 371 ADC_TqUnloadRate 0;
BA_ "GenSigInvalidValue" SG_ 371 ADC_TqUnloadRate 0;
BA_ "GenSigSendType" SG_ 371 ADC_TqUnloadRate 1;
BA_ "GenSigStartValue" SG_ 371 ADC_TqUnloadRate 0;
BA_ "GenSigTimeoutValue" SG_ 371 ADC_TqUnloadRate 0;
BA_ "Remark" SG_ 371 ADC_TqUnloadRate "";
BA_ "EventCommandSignal" SG_ 371 ADC_MotCtrlTar 0;
BA_ "GatewayedSignals" SG_ 371 ADC_MotCtrlTar 0;
BA_ "GenSigInactiveValue" SG_ 371 ADC_MotCtrlTar 0;
BA_ "GenSigInvalidValue" SG_ 371 ADC_MotCtrlTar 0;
BA_ "GenSigSendType" SG_ 371 ADC_MotCtrlTar 1;
BA_ "GenSigStartValue" SG_ 371 ADC_MotCtrlTar 0;
BA_ "GenSigTimeoutValue" SG_ 371 ADC_MotCtrlTar 0;
BA_ "Remark" SG_ 371 ADC_MotCtrlTar "";
BA_ "EventCommandSignal" SG_ 371 ADC_MotTarMod 0;
BA_ "GatewayedSignals" SG_ 371 ADC_MotTarMod 0;
BA_ "GenSigInactiveValue" SG_ 371 ADC_MotTarMod 0;
BA_ "GenSigInvalidValue" SG_ 371 ADC_MotTarMod 0;
BA_ "GenSigSendType" SG_ 371 ADC_MotTarMod 1;
BA_ "GenSigStartValue" SG_ 371 ADC_MotTarMod 0;
BA_ "GenSigTimeoutValue" SG_ 371 ADC_MotTarMod 0;
BA_ "Remark" SG_ 371 ADC_MotTarMod "";
BA_ "EventCommandSignal" SG_ 371 ADC_DrvTarTqMod 0;
BA_ "GatewayedSignals" SG_ 371 ADC_DrvTarTqMod 0;
BA_ "GenSigInactiveValue" SG_ 371 ADC_DrvTarTqMod 0;
BA_ "GenSigInvalidValue" SG_ 371 ADC_DrvTarTqMod 0;
BA_ "GenSigSendType" SG_ 371 ADC_DrvTarTqMod 1;
BA_ "GenSigStartValue" SG_ 371 ADC_DrvTarTqMod 0;
BA_ "GenSigTimeoutValue" SG_ 371 ADC_DrvTarTqMod 0;
BA_ "Remark" SG_ 371 ADC_DrvTarTqMod "";
BA_ "EventCommandSignal" SG_ 371 ADC_TqEvsSteerReq 0;
BA_ "GatewayedSignals" SG_ 371 ADC_TqEvsSteerReq 0;
BA_ "GenSigInactiveValue" SG_ 371 ADC_TqEvsSteerReq 0;
BA_ "GenSigInvalidValue" SG_ 371 ADC_TqEvsSteerReq 0;
BA_ "GenSigSendType" SG_ 371 ADC_TqEvsSteerReq 1;
BA_ "GenSigStartValue" SG_ 371 ADC_TqEvsSteerReq 0;
BA_ "GenSigTimeoutValue" SG_ 371 ADC_TqEvsSteerReq 0;
BA_ "Remark" SG_ 371 ADC_TqEvsSteerReq "";
BA_ "EventCommandSignal" SG_ 371 ADC_RapidRespEna 0;
BA_ "GatewayedSignals" SG_ 371 ADC_RapidRespEna 0;
BA_ "GenSigInactiveValue" SG_ 371 ADC_RapidRespEna 0;
BA_ "GenSigInvalidValue" SG_ 371 ADC_RapidRespEna 0;
BA_ "GenSigSendType" SG_ 371 ADC_RapidRespEna 1;
BA_ "GenSigStartValue" SG_ 371 ADC_RapidRespEna 0;
BA_ "GenSigTimeoutValue" SG_ 371 ADC_RapidRespEna 0;
BA_ "Remark" SG_ 371 ADC_RapidRespEna "";
BA_ "EventCommandSignal" SG_ 371 ADC_LimTqEnable 0;
BA_ "GatewayedSignals" SG_ 371 ADC_LimTqEnable 0;
BA_ "GenSigInactiveValue" SG_ 371 ADC_LimTqEnable 0;
BA_ "GenSigInvalidValue" SG_ 371 ADC_LimTqEnable 0;
BA_ "GenSigSendType" SG_ 371 ADC_LimTqEnable 1;
BA_ "GenSigStartValue" SG_ 371 ADC_LimTqEnable 0;
BA_ "GenSigTimeoutValue" SG_ 371 ADC_LimTqEnable 0;
BA_ "Remark" SG_ 371 ADC_LimTqEnable "";
BA_ "EventCommandSignal" SG_ 371 ADC_MotSpdCtrlEna 0;
BA_ "GatewayedSignals" SG_ 371 ADC_MotSpdCtrlEna 0;
BA_ "GenSigInactiveValue" SG_ 371 ADC_MotSpdCtrlEna 0;
BA_ "GenSigInvalidValue" SG_ 371 ADC_MotSpdCtrlEna 0;
BA_ "GenSigSendType" SG_ 371 ADC_MotSpdCtrlEna 1;
BA_ "GenSigStartValue" SG_ 371 ADC_MotSpdCtrlEna 0;
BA_ "GenSigTimeoutValue" SG_ 371 ADC_MotSpdCtrlEna 0;
BA_ "Remark" SG_ 371 ADC_MotSpdCtrlEna "";
BA_ "EventCommandSignal" SG_ 371 ADC_TqUnloadEna 0;
BA_ "GatewayedSignals" SG_ 371 ADC_TqUnloadEna 0;
BA_ "GenSigInactiveValue" SG_ 371 ADC_TqUnloadEna 0;
BA_ "GenSigInvalidValue" SG_ 371 ADC_TqUnloadEna 0;
BA_ "GenSigSendType" SG_ 371 ADC_TqUnloadEna 1;
BA_ "GenSigStartValue" SG_ 371 ADC_TqUnloadEna 0;
BA_ "GenSigTimeoutValue" SG_ 371 ADC_TqUnloadEna 0;
BA_ "Remark" SG_ 371 ADC_TqUnloadEna "";
BA_ "EventCommandSignal" SG_ 371 ADC_MotTarSpdSvValid 0;
BA_ "GatewayedSignals" SG_ 371 ADC_MotTarSpdSvValid 0;
BA_ "GenSigInactiveValue" SG_ 371 ADC_MotTarSpdSvValid 0;
BA_ "GenSigInvalidValue" SG_ 371 ADC_MotTarSpdSvValid 0;
BA_ "GenSigSendType" SG_ 371 ADC_MotTarSpdSvValid 1;
BA_ "GenSigStartValue" SG_ 371 ADC_MotTarSpdSvValid 0;
BA_ "GenSigTimeoutValue" SG_ 371 ADC_MotTarSpdSvValid 0;
BA_ "Remark" SG_ 371 ADC_MotTarSpdSvValid "";
BA_ "EventCommandSignal" SG_ 371 ADC_RoadTyp 0;
BA_ "GatewayedSignals" SG_ 371 ADC_RoadTyp 0;
BA_ "GenSigInactiveValue" SG_ 371 ADC_RoadTyp 0;
BA_ "GenSigInvalidValue" SG_ 371 ADC_RoadTyp 7;
BA_ "GenSigSendType" SG_ 371 ADC_RoadTyp 1;
BA_ "GenSigStartValue" SG_ 371 ADC_RoadTyp 0;
BA_ "GenSigTimeoutValue" SG_ 371 ADC_RoadTyp 0;
BA_ "Remark" SG_ 371 ADC_RoadTyp "";
BA_ "EventCommandSignal" SG_ 371 ADC_LeWhlLgtDst 0;
BA_ "GatewayedSignals" SG_ 371 ADC_LeWhlLgtDst 0;
BA_ "GenSigInactiveValue" SG_ 371 ADC_LeWhlLgtDst 0;
BA_ "GenSigInvalidValue" SG_ 371 ADC_LeWhlLgtDst 0;
BA_ "GenSigSendType" SG_ 371 ADC_LeWhlLgtDst 1;
BA_ "GenSigStartValue" SG_ 371 ADC_LeWhlLgtDst 0;
BA_ "GenSigTimeoutValue" SG_ 371 ADC_LeWhlLgtDst 0;
BA_ "Remark" SG_ 371 ADC_LeWhlLgtDst "";
BA_ "EventCommandSignal" SG_ 371 ADC_LeWhlRoadHei 0;
BA_ "GatewayedSignals" SG_ 371 ADC_LeWhlRoadHei 0;
BA_ "GenSigInactiveValue" SG_ 371 ADC_LeWhlRoadHei 0;
BA_ "GenSigInvalidValue" SG_ 371 ADC_LeWhlRoadHei 0;
BA_ "GenSigSendType" SG_ 371 ADC_LeWhlRoadHei 1;
BA_ "GenSigStartValue" SG_ 371 ADC_LeWhlRoadHei 500;
BA_ "GenSigTimeoutValue" SG_ 371 ADC_LeWhlRoadHei 0;
BA_ "Remark" SG_ 371 ADC_LeWhlRoadHei "";
BA_ "EventCommandSignal" SG_ 371 ADC_RiWhlLgtDst 0;
BA_ "GatewayedSignals" SG_ 371 ADC_RiWhlLgtDst 0;
BA_ "GenSigInactiveValue" SG_ 371 ADC_RiWhlLgtDst 0;
BA_ "GenSigInvalidValue" SG_ 371 ADC_RiWhlLgtDst 0;
BA_ "GenSigSendType" SG_ 371 ADC_RiWhlLgtDst 1;
BA_ "GenSigStartValue" SG_ 371 ADC_RiWhlLgtDst 0;
BA_ "GenSigTimeoutValue" SG_ 371 ADC_RiWhlLgtDst 0;
BA_ "Remark" SG_ 371 ADC_RiWhlLgtDst "";
BA_ "EventCommandSignal" SG_ 371 ADC_RiWhlRoadHei 0;
BA_ "GatewayedSignals" SG_ 371 ADC_RiWhlRoadHei 0;
BA_ "GenSigInactiveValue" SG_ 371 ADC_RiWhlRoadHei 0;
BA_ "GenSigInvalidValue" SG_ 371 ADC_RiWhlRoadHei 0;
BA_ "GenSigSendType" SG_ 371 ADC_RiWhlRoadHei 1;
BA_ "GenSigStartValue" SG_ 371 ADC_RiWhlRoadHei 500;
BA_ "GenSigTimeoutValue" SG_ 371 ADC_RiWhlRoadHei 0;
BA_ "Remark" SG_ 371 ADC_RiWhlRoadHei "";
BA_ "EventCommandSignal" SG_ 371 ADC_RiWhlRoadFeature 0;
BA_ "GatewayedSignals" SG_ 371 ADC_RiWhlRoadFeature 0;
BA_ "GenSigInactiveValue" SG_ 371 ADC_RiWhlRoadFeature 0;
BA_ "GenSigInvalidValue" SG_ 371 ADC_RiWhlRoadFeature 15;
BA_ "GenSigSendType" SG_ 371 ADC_RiWhlRoadFeature 1;
BA_ "GenSigStartValue" SG_ 371 ADC_RiWhlRoadFeature 0;
BA_ "GenSigTimeoutValue" SG_ 371 ADC_RiWhlRoadFeature 0;
BA_ "Remark" SG_ 371 ADC_RiWhlRoadFeature "";
BA_ "EventCommandSignal" SG_ 371 ADC_SuspensionStatus 0;
BA_ "GatewayedSignals" SG_ 371 ADC_SuspensionStatus 0;
BA_ "GenSigInactiveValue" SG_ 371 ADC_SuspensionStatus 0;
BA_ "GenSigInvalidValue" SG_ 371 ADC_SuspensionStatus 0;
BA_ "GenSigSendType" SG_ 371 ADC_SuspensionStatus 1;
BA_ "GenSigStartValue" SG_ 371 ADC_SuspensionStatus 0;
BA_ "GenSigTimeoutValue" SG_ 371 ADC_SuspensionStatus 0;
BA_ "Remark" SG_ 371 ADC_SuspensionStatus "";
BA_ "EventCommandSignal" SG_ 371 ADC_LeWhlRoadSts 0;
BA_ "GatewayedSignals" SG_ 371 ADC_LeWhlRoadSts 0;
BA_ "GenSigInactiveValue" SG_ 371 ADC_LeWhlRoadSts 0;
BA_ "GenSigInvalidValue" SG_ 371 ADC_LeWhlRoadSts 0;
BA_ "GenSigSendType" SG_ 371 ADC_LeWhlRoadSts 1;
BA_ "GenSigStartValue" SG_ 371 ADC_LeWhlRoadSts 0;
BA_ "GenSigTimeoutValue" SG_ 371 ADC_LeWhlRoadSts 0;
BA_ "Remark" SG_ 371 ADC_LeWhlRoadSts "";
BA_ "EventCommandSignal" SG_ 371 ADC_LeWhlRoadFeature 0;
BA_ "GatewayedSignals" SG_ 371 ADC_LeWhlRoadFeature 0;
BA_ "GenSigInactiveValue" SG_ 371 ADC_LeWhlRoadFeature 0;
BA_ "GenSigInvalidValue" SG_ 371 ADC_LeWhlRoadFeature 15;
BA_ "GenSigSendType" SG_ 371 ADC_LeWhlRoadFeature 1;
BA_ "GenSigStartValue" SG_ 371 ADC_LeWhlRoadFeature 0;
BA_ "GenSigTimeoutValue" SG_ 371 ADC_LeWhlRoadFeature 0;
BA_ "Remark" SG_ 371 ADC_LeWhlRoadFeature "";
BA_ "EventCommandSignal" SG_ 371 ADC_RiWhlRoadSts 0;
BA_ "GatewayedSignals" SG_ 371 ADC_RiWhlRoadSts 0;
BA_ "GenSigInactiveValue" SG_ 371 ADC_RiWhlRoadSts 0;
BA_ "GenSigInvalidValue" SG_ 371 ADC_RiWhlRoadSts 0;
BA_ "GenSigSendType" SG_ 371 ADC_RiWhlRoadSts 1;
BA_ "GenSigStartValue" SG_ 371 ADC_RiWhlRoadSts 0;
BA_ "GenSigTimeoutValue" SG_ 371 ADC_RiWhlRoadSts 0;
BA_ "Remark" SG_ 371 ADC_RiWhlRoadSts "";
BA_ "EventCommandSignal" SG_ 371 ADC_CDCCtrlEnable 0;
BA_ "GatewayedSignals" SG_ 371 ADC_CDCCtrlEnable 0;
BA_ "GenSigInactiveValue" SG_ 371 ADC_CDCCtrlEnable 0;
BA_ "GenSigInvalidValue" SG_ 371 ADC_CDCCtrlEnable 0;
BA_ "GenSigSendType" SG_ 371 ADC_CDCCtrlEnable 1;
BA_ "GenSigStartValue" SG_ 371 ADC_CDCCtrlEnable 0;
BA_ "GenSigTimeoutValue" SG_ 371 ADC_CDCCtrlEnable 0;
BA_ "Remark" SG_ 371 ADC_CDCCtrlEnable "";
BA_ "EventCommandSignal" SG_ 371 ADC_RoadInfoAvl 0;
BA_ "GatewayedSignals" SG_ 371 ADC_RoadInfoAvl 0;
BA_ "GenSigInactiveValue" SG_ 371 ADC_RoadInfoAvl 0;
BA_ "GenSigInvalidValue" SG_ 371 ADC_RoadInfoAvl 0;
BA_ "GenSigSendType" SG_ 371 ADC_RoadInfoAvl 1;
BA_ "GenSigStartValue" SG_ 371 ADC_RoadInfoAvl 0;
BA_ "GenSigTimeoutValue" SG_ 371 ADC_RoadInfoAvl 0;
BA_ "Remark" SG_ 371 ADC_RoadInfoAvl "";
BA_ "EventCommandSignal" SG_ 371 ADC_RoadFeatureDetFalutSts 0;
BA_ "GatewayedSignals" SG_ 371 ADC_RoadFeatureDetFalutSts 0;
BA_ "GenSigInactiveValue" SG_ 371 ADC_RoadFeatureDetFalutSts 0;
BA_ "GenSigInvalidValue" SG_ 371 ADC_RoadFeatureDetFalutSts 0;
BA_ "GenSigSendType" SG_ 371 ADC_RoadFeatureDetFalutSts 1;
BA_ "GenSigStartValue" SG_ 371 ADC_RoadFeatureDetFalutSts 0;
BA_ "GenSigTimeoutValue" SG_ 371 ADC_RoadFeatureDetFalutSts 1;
BA_ "Remark" SG_ 371 ADC_RoadFeatureDetFalutSts "";
BA_ "EventCommandSignal" SG_ 371 ADC_RoadFeatureDetWorkSts 0;
BA_ "GatewayedSignals" SG_ 371 ADC_RoadFeatureDetWorkSts 0;
BA_ "GenSigInactiveValue" SG_ 371 ADC_RoadFeatureDetWorkSts 0;
BA_ "GenSigInvalidValue" SG_ 371 ADC_RoadFeatureDetWorkSts 0;
BA_ "GenSigSendType" SG_ 371 ADC_RoadFeatureDetWorkSts 1;
BA_ "GenSigStartValue" SG_ 371 ADC_RoadFeatureDetWorkSts 0;
BA_ "GenSigTimeoutValue" SG_ 371 ADC_RoadFeatureDetWorkSts 0;
BA_ "Remark" SG_ 371 ADC_RoadFeatureDetWorkSts "";
BA_ "EventCommandSignal" SG_ 371 ADC_LeWhlRoadFeature2 0;
BA_ "GatewayedSignals" SG_ 371 ADC_LeWhlRoadFeature2 0;
BA_ "GenSigInactiveValue" SG_ 371 ADC_LeWhlRoadFeature2 0;
BA_ "GenSigInvalidValue" SG_ 371 ADC_LeWhlRoadFeature2 15;
BA_ "GenSigSendType" SG_ 371 ADC_LeWhlRoadFeature2 1;
BA_ "GenSigStartValue" SG_ 371 ADC_LeWhlRoadFeature2 0;
BA_ "GenSigTimeoutValue" SG_ 371 ADC_LeWhlRoadFeature2 0;
BA_ "Remark" SG_ 371 ADC_LeWhlRoadFeature2 "";
BA_ "EventCommandSignal" SG_ 371 ADC_LeWhlRoadFeature3 0;
BA_ "GatewayedSignals" SG_ 371 ADC_LeWhlRoadFeature3 0;
BA_ "GenSigInactiveValue" SG_ 371 ADC_LeWhlRoadFeature3 0;
BA_ "GenSigInvalidValue" SG_ 371 ADC_LeWhlRoadFeature3 15;
BA_ "GenSigSendType" SG_ 371 ADC_LeWhlRoadFeature3 1;
BA_ "GenSigStartValue" SG_ 371 ADC_LeWhlRoadFeature3 0;
BA_ "GenSigTimeoutValue" SG_ 371 ADC_LeWhlRoadFeature3 0;
BA_ "Remark" SG_ 371 ADC_LeWhlRoadFeature3 "";
BA_ "EventCommandSignal" SG_ 371 ADC_RiWhlRoadFeature2 0;
BA_ "GatewayedSignals" SG_ 371 ADC_RiWhlRoadFeature2 0;
BA_ "GenSigInactiveValue" SG_ 371 ADC_RiWhlRoadFeature2 0;
BA_ "GenSigInvalidValue" SG_ 371 ADC_RiWhlRoadFeature2 15;
BA_ "GenSigSendType" SG_ 371 ADC_RiWhlRoadFeature2 1;
BA_ "GenSigStartValue" SG_ 371 ADC_RiWhlRoadFeature2 0;
BA_ "GenSigTimeoutValue" SG_ 371 ADC_RiWhlRoadFeature2 0;
BA_ "Remark" SG_ 371 ADC_RiWhlRoadFeature2 "";
BA_ "EventCommandSignal" SG_ 371 ADC_RiWhlRoadFeature3 0;
BA_ "GatewayedSignals" SG_ 371 ADC_RiWhlRoadFeature3 0;
BA_ "GenSigInactiveValue" SG_ 371 ADC_RiWhlRoadFeature3 0;
BA_ "GenSigInvalidValue" SG_ 371 ADC_RiWhlRoadFeature3 15;
BA_ "GenSigSendType" SG_ 371 ADC_RiWhlRoadFeature3 1;
BA_ "GenSigStartValue" SG_ 371 ADC_RiWhlRoadFeature3 0;
BA_ "GenSigTimeoutValue" SG_ 371 ADC_RiWhlRoadFeature3 0;
BA_ "Remark" SG_ 371 ADC_RiWhlRoadFeature3 "";
BA_ "EventCommandSignal" SG_ 371 ADC_LeWhlRoadHei2 0;
BA_ "GatewayedSignals" SG_ 371 ADC_LeWhlRoadHei2 0;
BA_ "GenSigInactiveValue" SG_ 371 ADC_LeWhlRoadHei2 0;
BA_ "GenSigInvalidValue" SG_ 371 ADC_LeWhlRoadHei2 0;
BA_ "GenSigSendType" SG_ 371 ADC_LeWhlRoadHei2 1;
BA_ "GenSigStartValue" SG_ 371 ADC_LeWhlRoadHei2 0;
BA_ "GenSigTimeoutValue" SG_ 371 ADC_LeWhlRoadHei2 0;
BA_ "Remark" SG_ 371 ADC_LeWhlRoadHei2 "";
BA_ "EventCommandSignal" SG_ 371 ADC_LeWhlRoadHei3 0;
BA_ "GatewayedSignals" SG_ 371 ADC_LeWhlRoadHei3 0;
BA_ "GenSigInactiveValue" SG_ 371 ADC_LeWhlRoadHei3 0;
BA_ "GenSigInvalidValue" SG_ 371 ADC_LeWhlRoadHei3 0;
BA_ "GenSigSendType" SG_ 371 ADC_LeWhlRoadHei3 1;
BA_ "GenSigStartValue" SG_ 371 ADC_LeWhlRoadHei3 0;
BA_ "GenSigTimeoutValue" SG_ 371 ADC_LeWhlRoadHei3 0;
BA_ "Remark" SG_ 371 ADC_LeWhlRoadHei3 "";
BA_ "EventCommandSignal" SG_ 371 ADC_RiWhlRoadHei2 0;
BA_ "GatewayedSignals" SG_ 371 ADC_RiWhlRoadHei2 0;
BA_ "GenSigInactiveValue" SG_ 371 ADC_RiWhlRoadHei2 0;
BA_ "GenSigInvalidValue" SG_ 371 ADC_RiWhlRoadHei2 0;
BA_ "GenSigSendType" SG_ 371 ADC_RiWhlRoadHei2 1;
BA_ "GenSigStartValue" SG_ 371 ADC_RiWhlRoadHei2 0;
BA_ "GenSigTimeoutValue" SG_ 371 ADC_RiWhlRoadHei2 0;
BA_ "Remark" SG_ 371 ADC_RiWhlRoadHei2 "";
BA_ "EventCommandSignal" SG_ 371 ADC_RiWhlRoadHei3 0;
BA_ "GatewayedSignals" SG_ 371 ADC_RiWhlRoadHei3 0;
BA_ "GenSigInactiveValue" SG_ 371 ADC_RiWhlRoadHei3 0;
BA_ "GenSigInvalidValue" SG_ 371 ADC_RiWhlRoadHei3 0;
BA_ "GenSigSendType" SG_ 371 ADC_RiWhlRoadHei3 1;
BA_ "GenSigStartValue" SG_ 371 ADC_RiWhlRoadHei3 0;
BA_ "GenSigTimeoutValue" SG_ 371 ADC_RiWhlRoadHei3 0;
BA_ "Remark" SG_ 371 ADC_RiWhlRoadHei3 "";
BA_ "EventCommandSignal" SG_ 371 ADC_LeWhlLgtDst2 0;
BA_ "GatewayedSignals" SG_ 371 ADC_LeWhlLgtDst2 0;
BA_ "GenSigInactiveValue" SG_ 371 ADC_LeWhlLgtDst2 0;
BA_ "GenSigInvalidValue" SG_ 371 ADC_LeWhlLgtDst2 63;
BA_ "GenSigSendType" SG_ 371 ADC_LeWhlLgtDst2 1;
BA_ "GenSigStartValue" SG_ 371 ADC_LeWhlLgtDst2 63;
BA_ "GenSigTimeoutValue" SG_ 371 ADC_LeWhlLgtDst2 63;
BA_ "Remark" SG_ 371 ADC_LeWhlLgtDst2 "";
BA_ "EventCommandSignal" SG_ 371 ADC_LeWhlLgtDst3 0;
BA_ "GatewayedSignals" SG_ 371 ADC_LeWhlLgtDst3 0;
BA_ "GenSigInactiveValue" SG_ 371 ADC_LeWhlLgtDst3 0;
BA_ "GenSigInvalidValue" SG_ 371 ADC_LeWhlLgtDst3 63;
BA_ "GenSigSendType" SG_ 371 ADC_LeWhlLgtDst3 1;
BA_ "GenSigStartValue" SG_ 371 ADC_LeWhlLgtDst3 63;
BA_ "GenSigTimeoutValue" SG_ 371 ADC_LeWhlLgtDst3 63;
BA_ "Remark" SG_ 371 ADC_LeWhlLgtDst3 "";
BA_ "EventCommandSignal" SG_ 371 ADC_RiWhlLgtDst2 0;
BA_ "GatewayedSignals" SG_ 371 ADC_RiWhlLgtDst2 0;
BA_ "GenSigInactiveValue" SG_ 371 ADC_RiWhlLgtDst2 0;
BA_ "GenSigInvalidValue" SG_ 371 ADC_RiWhlLgtDst2 63;
BA_ "GenSigSendType" SG_ 371 ADC_RiWhlLgtDst2 1;
BA_ "GenSigStartValue" SG_ 371 ADC_RiWhlLgtDst2 63;
BA_ "GenSigTimeoutValue" SG_ 371 ADC_RiWhlLgtDst2 63;
BA_ "Remark" SG_ 371 ADC_RiWhlLgtDst2 "";
BA_ "EventCommandSignal" SG_ 371 ADC_RiWhlLgtDst3 0;
BA_ "GatewayedSignals" SG_ 371 ADC_RiWhlLgtDst3 0;
BA_ "GenSigInactiveValue" SG_ 371 ADC_RiWhlLgtDst3 0;
BA_ "GenSigInvalidValue" SG_ 371 ADC_RiWhlLgtDst3 63;
BA_ "GenSigSendType" SG_ 371 ADC_RiWhlLgtDst3 1;
BA_ "GenSigStartValue" SG_ 371 ADC_RiWhlLgtDst3 63;
BA_ "GenSigTimeoutValue" SG_ 371 ADC_RiWhlLgtDst3 63;
BA_ "Remark" SG_ 371 ADC_RiWhlLgtDst3 "";
BA_ "EventCommandSignal" SG_ 371 ADC_AS_SuspHeiAdj 0;
BA_ "GatewayedSignals" SG_ 371 ADC_AS_SuspHeiAdj 0;
BA_ "GenSigInactiveValue" SG_ 371 ADC_AS_SuspHeiAdj 0;
BA_ "GenSigInvalidValue" SG_ 371 ADC_AS_SuspHeiAdj 0;
BA_ "GenSigSendType" SG_ 371 ADC_AS_SuspHeiAdj 1;
BA_ "GenSigStartValue" SG_ 371 ADC_AS_SuspHeiAdj 0;
BA_ "GenSigTimeoutValue" SG_ 371 ADC_AS_SuspHeiAdj 0;
BA_ "Remark" SG_ 371 ADC_AS_SuspHeiAdj "";
BA_ "EventCommandSignal" SG_ 371 ADC_AS_SuspHeiAdjVld 0;
BA_ "GatewayedSignals" SG_ 371 ADC_AS_SuspHeiAdjVld 0;
BA_ "GenSigInactiveValue" SG_ 371 ADC_AS_SuspHeiAdjVld 0;
BA_ "GenSigInvalidValue" SG_ 371 ADC_AS_SuspHeiAdjVld 0;
BA_ "GenSigSendType" SG_ 371 ADC_AS_SuspHeiAdjVld 1;
BA_ "GenSigStartValue" SG_ 371 ADC_AS_SuspHeiAdjVld 0;
BA_ "GenSigTimeoutValue" SG_ 371 ADC_AS_SuspHeiAdjVld 0;
BA_ "Remark" SG_ 371 ADC_AS_SuspHeiAdjVld "";
BA_ "EventCommandSignal" SG_ 371 ADC_AS_SusStfnAdj 0;
BA_ "GatewayedSignals" SG_ 371 ADC_AS_SusStfnAdj 0;
BA_ "GenSigInactiveValue" SG_ 371 ADC_AS_SusStfnAdj 0;
BA_ "GenSigInvalidValue" SG_ 371 ADC_AS_SusStfnAdj 0;
BA_ "GenSigSendType" SG_ 371 ADC_AS_SusStfnAdj 1;
BA_ "GenSigStartValue" SG_ 371 ADC_AS_SusStfnAdj 0;
BA_ "GenSigTimeoutValue" SG_ 371 ADC_AS_SusStfnAdj 0;
BA_ "Remark" SG_ 371 ADC_AS_SusStfnAdj "";
BA_ "EventCommandSignal" SG_ 371 ADC_AS_SusStfnAdjVld 0;
BA_ "GatewayedSignals" SG_ 371 ADC_AS_SusStfnAdjVld 0;
BA_ "GenSigInactiveValue" SG_ 371 ADC_AS_SusStfnAdjVld 0;
BA_ "GenSigInvalidValue" SG_ 371 ADC_AS_SusStfnAdjVld 0;
BA_ "GenSigSendType" SG_ 371 ADC_AS_SusStfnAdjVld 1;
BA_ "GenSigStartValue" SG_ 371 ADC_AS_SusStfnAdjVld 0;
BA_ "GenSigTimeoutValue" SG_ 371 ADC_AS_SusStfnAdjVld 0;
BA_ "Remark" SG_ 371 ADC_AS_SusStfnAdjVld "";
BA_ "EventCommandSignal" SG_ 371 ADC_CDCModReq 0;
BA_ "GatewayedSignals" SG_ 371 ADC_CDCModReq 0;
BA_ "GenSigInactiveValue" SG_ 371 ADC_CDCModReq 0;
BA_ "GenSigInvalidValue" SG_ 371 ADC_CDCModReq 0;
BA_ "GenSigSendType" SG_ 371 ADC_CDCModReq 1;
BA_ "GenSigStartValue" SG_ 371 ADC_CDCModReq 0;
BA_ "GenSigTimeoutValue" SG_ 371 ADC_CDCModReq 0;
BA_ "Remark" SG_ 371 ADC_CDCModReq "";
BA_ "EventCommandSignal" SG_ 371 ADC_CDCModReqVld 0;
BA_ "GatewayedSignals" SG_ 371 ADC_CDCModReqVld 0;
BA_ "GenSigInactiveValue" SG_ 371 ADC_CDCModReqVld 0;
BA_ "GenSigInvalidValue" SG_ 371 ADC_CDCModReqVld 0;
BA_ "GenSigSendType" SG_ 371 ADC_CDCModReqVld 1;
BA_ "GenSigStartValue" SG_ 371 ADC_CDCModReqVld 0;
BA_ "GenSigTimeoutValue" SG_ 371 ADC_CDCModReqVld 0;
BA_ "Remark" SG_ 371 ADC_CDCModReqVld "";
BA_ "EventCommandSignal" SG_ 371 ADC_UrgentSteerFlg 0;
BA_ "GatewayedSignals" SG_ 371 ADC_UrgentSteerFlg 0;
BA_ "GenSigInactiveValue" SG_ 371 ADC_UrgentSteerFlg 0;
BA_ "GenSigInvalidValue" SG_ 371 ADC_UrgentSteerFlg 0;
BA_ "GenSigSendType" SG_ 371 ADC_UrgentSteerFlg 1;
BA_ "GenSigStartValue" SG_ 371 ADC_UrgentSteerFlg 0;
BA_ "GenSigTimeoutValue" SG_ 371 ADC_UrgentSteerFlg 0;
BA_ "Remark" SG_ 371 ADC_UrgentSteerFlg "";
BA_ "EventCommandSignal" SG_ 371 ADC_OneMotorCtrlEna 0;
BA_ "GatewayedSignals" SG_ 371 ADC_OneMotorCtrlEna 0;
BA_ "GenSigInactiveValue" SG_ 371 ADC_OneMotorCtrlEna 0;
BA_ "GenSigInvalidValue" SG_ 371 ADC_OneMotorCtrlEna 0;
BA_ "GenSigSendType" SG_ 371 ADC_OneMotorCtrlEna 1;
BA_ "GenSigStartValue" SG_ 371 ADC_OneMotorCtrlEna 0;
BA_ "GenSigTimeoutValue" SG_ 371 ADC_OneMotorCtrlEna 0;
BA_ "Remark" SG_ 371 ADC_OneMotorCtrlEna "";
BA_ "EventCommandSignal" SG_ 371 ADC_MotorCtrlTqWhlRL 0;
BA_ "GatewayedSignals" SG_ 371 ADC_MotorCtrlTqWhlRL 0;
BA_ "GenSigInactiveValue" SG_ 371 ADC_MotorCtrlTqWhlRL 0;
BA_ "GenSigInvalidValue" SG_ 371 ADC_MotorCtrlTqWhlRL 0;
BA_ "GenSigSendType" SG_ 371 ADC_MotorCtrlTqWhlRL 1;
BA_ "GenSigStartValue" SG_ 371 ADC_MotorCtrlTqWhlRL 0;
BA_ "GenSigTimeoutValue" SG_ 371 ADC_MotorCtrlTqWhlRL 0;
BA_ "Remark" SG_ 371 ADC_MotorCtrlTqWhlRL "";
BA_ "EventCommandSignal" SG_ 371 ADC_MotorCtrlTqWhlRR 0;
BA_ "GatewayedSignals" SG_ 371 ADC_MotorCtrlTqWhlRR 0;
BA_ "GenSigInactiveValue" SG_ 371 ADC_MotorCtrlTqWhlRR 0;
BA_ "GenSigInvalidValue" SG_ 371 ADC_MotorCtrlTqWhlRR 0;
BA_ "GenSigSendType" SG_ 371 ADC_MotorCtrlTqWhlRR 1;
BA_ "GenSigStartValue" SG_ 371 ADC_MotorCtrlTqWhlRR 0;
BA_ "GenSigTimeoutValue" SG_ 371 ADC_MotorCtrlTqWhlRR 0;
BA_ "Remark" SG_ 371 ADC_MotorCtrlTqWhlRR "";
BA_ "EventCommandSignal" SG_ 371 ADC_SteerGainLevelTqCtrl 0;
BA_ "GatewayedSignals" SG_ 371 ADC_SteerGainLevelTqCtrl 0;
BA_ "GenSigInactiveValue" SG_ 371 ADC_SteerGainLevelTqCtrl 0;
BA_ "GenSigInvalidValue" SG_ 371 ADC_SteerGainLevelTqCtrl 0;
BA_ "GenSigSendType" SG_ 371 ADC_SteerGainLevelTqCtrl 1;
BA_ "GenSigStartValue" SG_ 371 ADC_SteerGainLevelTqCtrl 0;
BA_ "GenSigTimeoutValue" SG_ 371 ADC_SteerGainLevelTqCtrl 100;
BA_ "Remark" SG_ 371 ADC_SteerGainLevelTqCtrl "";
BA_ "EventCommandSignal" SG_ 371 ADC_MotorCtrlTqWhlFR 0;
BA_ "GatewayedSignals" SG_ 371 ADC_MotorCtrlTqWhlFR 0;
BA_ "GenSigInactiveValue" SG_ 371 ADC_MotorCtrlTqWhlFR 0;
BA_ "GenSigInvalidValue" SG_ 371 ADC_MotorCtrlTqWhlFR 0;
BA_ "GenSigSendType" SG_ 371 ADC_MotorCtrlTqWhlFR 1;
BA_ "GenSigStartValue" SG_ 371 ADC_MotorCtrlTqWhlFR 0;
BA_ "GenSigTimeoutValue" SG_ 371 ADC_MotorCtrlTqWhlFR 0;
BA_ "Remark" SG_ 371 ADC_MotorCtrlTqWhlFR "";
BA_ "EventCommandSignal" SG_ 371 ADC_MotorCtrlTqWhlFL 0;
BA_ "GatewayedSignals" SG_ 371 ADC_MotorCtrlTqWhlFL 0;
BA_ "GenSigInactiveValue" SG_ 371 ADC_MotorCtrlTqWhlFL 0;
BA_ "GenSigInvalidValue" SG_ 371 ADC_MotorCtrlTqWhlFL 0;
BA_ "GenSigSendType" SG_ 371 ADC_MotorCtrlTqWhlFL 1;
BA_ "GenSigStartValue" SG_ 371 ADC_MotorCtrlTqWhlFL 0;
BA_ "GenSigTimeoutValue" SG_ 371 ADC_MotorCtrlTqWhlFL 0;
BA_ "Remark" SG_ 371 ADC_MotorCtrlTqWhlFL "";
BA_ "EventCommandSignal" SG_ 422 VCU_1_B_CRC 0;
BA_ "GatewayedSignals" SG_ 422 VCU_1_B_CRC 0;
BA_ "GenSigInactiveValue" SG_ 422 VCU_1_B_CRC 0;
BA_ "GenSigInvalidValue" SG_ 422 VCU_1_B_CRC 0;
BA_ "GenSigSendType" SG_ 422 VCU_1_B_CRC 1;
BA_ "GenSigStartValue" SG_ 422 VCU_1_B_CRC 0;
BA_ "GenSigTimeoutValue" SG_ 422 VCU_1_B_CRC 0;
BA_ "Remark" SG_ 422 VCU_1_B_CRC "";
BA_ "EventCommandSignal" SG_ 422 VCU_1_B_Counter 0;
BA_ "GatewayedSignals" SG_ 422 VCU_1_B_Counter 0;
BA_ "GenSigInactiveValue" SG_ 422 VCU_1_B_Counter 0;
BA_ "GenSigInvalidValue" SG_ 422 VCU_1_B_Counter 0;
BA_ "GenSigSendType" SG_ 422 VCU_1_B_Counter 1;
BA_ "GenSigStartValue" SG_ 422 VCU_1_B_Counter 0;
BA_ "GenSigTimeoutValue" SG_ 422 VCU_1_B_Counter 0;
BA_ "Remark" SG_ 422 VCU_1_B_Counter "";
BA_ "EventCommandSignal" SG_ 422 VCU_AccButtInfo_B 0;
BA_ "GatewayedSignals" SG_ 422 VCU_AccButtInfo_B 0;
BA_ "GenSigInactiveValue" SG_ 422 VCU_AccButtInfo_B 0;
BA_ "GenSigInvalidValue" SG_ 422 VCU_AccButtInfo_B 0;
BA_ "GenSigSendType" SG_ 422 VCU_AccButtInfo_B 1;
BA_ "GenSigStartValue" SG_ 422 VCU_AccButtInfo_B 0;
BA_ "GenSigTimeoutValue" SG_ 422 VCU_AccButtInfo_B 0;
BA_ "Remark" SG_ 422 VCU_AccButtInfo_B "";
BA_ "EventCommandSignal" SG_ 422 VCU_LateralAssistBtnInfo_B 0;
BA_ "GatewayedSignals" SG_ 422 VCU_LateralAssistBtnInfo_B 0;
BA_ "GenSigInactiveValue" SG_ 422 VCU_LateralAssistBtnInfo_B 0;
BA_ "GenSigInvalidValue" SG_ 422 VCU_LateralAssistBtnInfo_B 0;
BA_ "GenSigSendType" SG_ 422 VCU_LateralAssistBtnInfo_B 1;
BA_ "GenSigStartValue" SG_ 422 VCU_LateralAssistBtnInfo_B 0;
BA_ "GenSigTimeoutValue" SG_ 422 VCU_LateralAssistBtnInfo_B 0;
BA_ "Remark" SG_ 422 VCU_LateralAssistBtnInfo_B "";
BA_ "EventCommandSignal" SG_ 422 VCU_LateralAssistBtnInfoVD_B 0;
BA_ "GatewayedSignals" SG_ 422 VCU_LateralAssistBtnInfoVD_B 0;
BA_ "GenSigInactiveValue" SG_ 422 VCU_LateralAssistBtnInfoVD_B 0;
BA_ "GenSigInvalidValue" SG_ 422 VCU_LateralAssistBtnInfoVD_B 0;
BA_ "GenSigSendType" SG_ 422 VCU_LateralAssistBtnInfoVD_B 1;
BA_ "GenSigStartValue" SG_ 422 VCU_LateralAssistBtnInfoVD_B 0;
BA_ "GenSigTimeoutValue" SG_ 422 VCU_LateralAssistBtnInfoVD_B 0;
BA_ "Remark" SG_ 422 VCU_LateralAssistBtnInfoVD_B "";
BA_ "EventCommandSignal" SG_ 422 VCU_AccMasterCanError_B 0;
BA_ "GatewayedSignals" SG_ 422 VCU_AccMasterCanError_B 0;
BA_ "GenSigInactiveValue" SG_ 422 VCU_AccMasterCanError_B 0;
BA_ "GenSigInvalidValue" SG_ 422 VCU_AccMasterCanError_B 0;
BA_ "GenSigSendType" SG_ 422 VCU_AccMasterCanError_B 1;
BA_ "GenSigStartValue" SG_ 422 VCU_AccMasterCanError_B 0;
BA_ "GenSigTimeoutValue" SG_ 422 VCU_AccMasterCanError_B 0;
BA_ "Remark" SG_ 422 VCU_AccMasterCanError_B "";
BA_ "EventCommandSignal" SG_ 422 VCU_IFCFailureSt_B 0;
BA_ "GatewayedSignals" SG_ 422 VCU_IFCFailureSt_B 0;
BA_ "GenSigInactiveValue" SG_ 422 VCU_IFCFailureSt_B 0;
BA_ "GenSigInvalidValue" SG_ 422 VCU_IFCFailureSt_B 0;
BA_ "GenSigSendType" SG_ 422 VCU_IFCFailureSt_B 1;
BA_ "GenSigStartValue" SG_ 422 VCU_IFCFailureSt_B 0;
BA_ "GenSigTimeoutValue" SG_ 422 VCU_IFCFailureSt_B 0;
BA_ "Remark" SG_ 422 VCU_IFCFailureSt_B "";
BA_ "EventCommandSignal" SG_ 422 VCU_VehDrvMod_B 0;
BA_ "GatewayedSignals" SG_ 422 VCU_VehDrvMod_B 0;
BA_ "GenSigInactiveValue" SG_ 422 VCU_VehDrvMod_B 0;
BA_ "GenSigInvalidValue" SG_ 422 VCU_VehDrvMod_B 0;
BA_ "GenSigSendType" SG_ 422 VCU_VehDrvMod_B 1;
BA_ "GenSigStartValue" SG_ 422 VCU_VehDrvMod_B 0;
BA_ "GenSigTimeoutValue" SG_ 422 VCU_VehDrvMod_B 0;
BA_ "Remark" SG_ 422 VCU_VehDrvMod_B "";
BA_ "EventCommandSignal" SG_ 422 VCU_VehRdySt_B 0;
BA_ "GatewayedSignals" SG_ 422 VCU_VehRdySt_B 0;
BA_ "GenSigInactiveValue" SG_ 422 VCU_VehRdySt_B 0;
BA_ "GenSigInvalidValue" SG_ 422 VCU_VehRdySt_B 0;
BA_ "GenSigSendType" SG_ 422 VCU_VehRdySt_B 1;
BA_ "GenSigStartValue" SG_ 422 VCU_VehRdySt_B 0;
BA_ "GenSigTimeoutValue" SG_ 422 VCU_VehRdySt_B 0;
BA_ "Remark" SG_ 422 VCU_VehRdySt_B "";
BA_ "EventCommandSignal" SG_ 422 VCU_GearLvl_B 0;
BA_ "GatewayedSignals" SG_ 422 VCU_GearLvl_B 0;
BA_ "GenSigInactiveValue" SG_ 422 VCU_GearLvl_B 0;
BA_ "GenSigInvalidValue" SG_ 422 VCU_GearLvl_B 0;
BA_ "GenSigSendType" SG_ 422 VCU_GearLvl_B 1;
BA_ "GenSigStartValue" SG_ 422 VCU_GearLvl_B 0;
BA_ "GenSigTimeoutValue" SG_ 422 VCU_GearLvl_B 0;
BA_ "Remark" SG_ 422 VCU_GearLvl_B "";
BA_ "EventCommandSignal" SG_ 422 VCU_RecpTorqVD_B 0;
BA_ "GatewayedSignals" SG_ 422 VCU_RecpTorqVD_B 0;
BA_ "GenSigInactiveValue" SG_ 422 VCU_RecpTorqVD_B 0;
BA_ "GenSigInvalidValue" SG_ 422 VCU_RecpTorqVD_B 0;
BA_ "GenSigSendType" SG_ 422 VCU_RecpTorqVD_B 1;
BA_ "GenSigStartValue" SG_ 422 VCU_RecpTorqVD_B 0;
BA_ "GenSigTimeoutValue" SG_ 422 VCU_RecpTorqVD_B 0;
BA_ "Remark" SG_ 422 VCU_RecpTorqVD_B "";
BA_ "EventCommandSignal" SG_ 422 VCU_RecpTorq_B 0;
BA_ "GatewayedSignals" SG_ 422 VCU_RecpTorq_B 0;
BA_ "GenSigInactiveValue" SG_ 422 VCU_RecpTorq_B 0;
BA_ "GenSigInvalidValue" SG_ 422 VCU_RecpTorq_B 0;
BA_ "GenSigSendType" SG_ 422 VCU_RecpTorq_B 1;
BA_ "GenSigStartValue" SG_ 422 VCU_RecpTorq_B 0;
BA_ "GenSigTimeoutValue" SG_ 422 VCU_RecpTorq_B 0;
BA_ "Remark" SG_ 422 VCU_RecpTorq_B "";
BA_ "EventCommandSignal" SG_ 422 VCU_BrkPedPst_B 0;
BA_ "GatewayedSignals" SG_ 422 VCU_BrkPedPst_B 0;
BA_ "GenSigInactiveValue" SG_ 422 VCU_BrkPedPst_B 0;
BA_ "GenSigInvalidValue" SG_ 422 VCU_BrkPedPst_B 0;
BA_ "GenSigSendType" SG_ 422 VCU_BrkPedPst_B 1;
BA_ "GenSigStartValue" SG_ 422 VCU_BrkPedPst_B 0;
BA_ "GenSigTimeoutValue" SG_ 422 VCU_BrkPedPst_B 0;
BA_ "Remark" SG_ 422 VCU_BrkPedPst_B "";
BA_ "EventCommandSignal" SG_ 422 VCU_BrkPedPstVD_B 0;
BA_ "GatewayedSignals" SG_ 422 VCU_BrkPedPstVD_B 0;
BA_ "GenSigInactiveValue" SG_ 422 VCU_BrkPedPstVD_B 0;
BA_ "GenSigInvalidValue" SG_ 422 VCU_BrkPedPstVD_B 0;
BA_ "GenSigSendType" SG_ 422 VCU_BrkPedPstVD_B 1;
BA_ "GenSigStartValue" SG_ 422 VCU_BrkPedPstVD_B 0;
BA_ "GenSigTimeoutValue" SG_ 422 VCU_BrkPedPstVD_B 0;
BA_ "Remark" SG_ 422 VCU_BrkPedPstVD_B "";
BA_ "EventCommandSignal" SG_ 422 VCU_CrntGearLvlVD_B 0;
BA_ "GatewayedSignals" SG_ 422 VCU_CrntGearLvlVD_B 0;
BA_ "GenSigInactiveValue" SG_ 422 VCU_CrntGearLvlVD_B 0;
BA_ "GenSigInvalidValue" SG_ 422 VCU_CrntGearLvlVD_B 0;
BA_ "GenSigSendType" SG_ 422 VCU_CrntGearLvlVD_B 1;
BA_ "GenSigStartValue" SG_ 422 VCU_CrntGearLvlVD_B 0;
BA_ "GenSigTimeoutValue" SG_ 422 VCU_CrntGearLvlVD_B 0;
BA_ "Remark" SG_ 422 VCU_CrntGearLvlVD_B "";
BA_ "EventCommandSignal" SG_ 422 VCU_CrntGearLvl_B 0;
BA_ "GatewayedSignals" SG_ 422 VCU_CrntGearLvl_B 0;
BA_ "GenSigInactiveValue" SG_ 422 VCU_CrntGearLvl_B 0;
BA_ "GenSigInvalidValue" SG_ 422 VCU_CrntGearLvl_B 0;
BA_ "GenSigSendType" SG_ 422 VCU_CrntGearLvl_B 1;
BA_ "GenSigStartValue" SG_ 422 VCU_CrntGearLvl_B 0;
BA_ "GenSigTimeoutValue" SG_ 422 VCU_CrntGearLvl_B 0;
BA_ "Remark" SG_ 422 VCU_CrntGearLvl_B "";
BA_ "EventCommandSignal" SG_ 422 VCU_ACCLimitOperatingSt_B 0;
BA_ "GatewayedSignals" SG_ 422 VCU_ACCLimitOperatingSt_B 0;
BA_ "GenSigInactiveValue" SG_ 422 VCU_ACCLimitOperatingSt_B 0;
BA_ "GenSigInvalidValue" SG_ 422 VCU_ACCLimitOperatingSt_B 0;
BA_ "GenSigSendType" SG_ 422 VCU_ACCLimitOperatingSt_B 1;
BA_ "GenSigStartValue" SG_ 422 VCU_ACCLimitOperatingSt_B 0;
BA_ "GenSigTimeoutValue" SG_ 422 VCU_ACCLimitOperatingSt_B 0;
BA_ "Remark" SG_ 422 VCU_ACCLimitOperatingSt_B "";
BA_ "EventCommandSignal" SG_ 422 VCU_ACCMaxRecpDecelVD_B 0;
BA_ "GatewayedSignals" SG_ 422 VCU_ACCMaxRecpDecelVD_B 0;
BA_ "GenSigInactiveValue" SG_ 422 VCU_ACCMaxRecpDecelVD_B 0;
BA_ "GenSigInvalidValue" SG_ 422 VCU_ACCMaxRecpDecelVD_B 0;
BA_ "GenSigSendType" SG_ 422 VCU_ACCMaxRecpDecelVD_B 1;
BA_ "GenSigStartValue" SG_ 422 VCU_ACCMaxRecpDecelVD_B 0;
BA_ "GenSigTimeoutValue" SG_ 422 VCU_ACCMaxRecpDecelVD_B 0;
BA_ "Remark" SG_ 422 VCU_ACCMaxRecpDecelVD_B "";
BA_ "EventCommandSignal" SG_ 422 VCU_ACCMaxRecpDecel_B 0;
BA_ "GatewayedSignals" SG_ 422 VCU_ACCMaxRecpDecel_B 0;
BA_ "GenSigInactiveValue" SG_ 422 VCU_ACCMaxRecpDecel_B 0;
BA_ "GenSigInvalidValue" SG_ 422 VCU_ACCMaxRecpDecel_B 0;
BA_ "GenSigSendType" SG_ 422 VCU_ACCMaxRecpDecel_B 1;
BA_ "GenSigStartValue" SG_ 422 VCU_ACCMaxRecpDecel_B 0;
BA_ "GenSigTimeoutValue" SG_ 422 VCU_ACCMaxRecpDecel_B 0;
BA_ "Remark" SG_ 422 VCU_ACCMaxRecpDecel_B "";
BA_ "EventCommandSignal" SG_ 422 VCU_ActVehWheelTorq_B 0;
BA_ "GatewayedSignals" SG_ 422 VCU_ActVehWheelTorq_B 0;
BA_ "GenSigInactiveValue" SG_ 422 VCU_ActVehWheelTorq_B 0;
BA_ "GenSigInvalidValue" SG_ 422 VCU_ActVehWheelTorq_B 0;
BA_ "GenSigSendType" SG_ 422 VCU_ActVehWheelTorq_B 1;
BA_ "GenSigStartValue" SG_ 422 VCU_ActVehWheelTorq_B 0;
BA_ "GenSigTimeoutValue" SG_ 422 VCU_ActVehWheelTorq_B 0;
BA_ "Remark" SG_ 422 VCU_ActVehWheelTorq_B "";
BA_ "EventCommandSignal" SG_ 422 VCU_ACCmaxSpdLimit_B 0;
BA_ "GatewayedSignals" SG_ 422 VCU_ACCmaxSpdLimit_B 0;
BA_ "GenSigInactiveValue" SG_ 422 VCU_ACCmaxSpdLimit_B 0;
BA_ "GenSigInvalidValue" SG_ 422 VCU_ACCmaxSpdLimit_B 0;
BA_ "GenSigSendType" SG_ 422 VCU_ACCmaxSpdLimit_B 1;
BA_ "GenSigStartValue" SG_ 422 VCU_ACCmaxSpdLimit_B 0;
BA_ "GenSigTimeoutValue" SG_ 422 VCU_ACCmaxSpdLimit_B 0;
BA_ "Remark" SG_ 422 VCU_ACCmaxSpdLimit_B "";
BA_ "EventCommandSignal" SG_ 422 VCU_VehWheelTorqMax_B 0;
BA_ "GatewayedSignals" SG_ 422 VCU_VehWheelTorqMax_B 0;
BA_ "GenSigInactiveValue" SG_ 422 VCU_VehWheelTorqMax_B 0;
BA_ "GenSigInvalidValue" SG_ 422 VCU_VehWheelTorqMax_B 0;
BA_ "GenSigSendType" SG_ 422 VCU_VehWheelTorqMax_B 1;
BA_ "GenSigStartValue" SG_ 422 VCU_VehWheelTorqMax_B 0;
BA_ "GenSigTimeoutValue" SG_ 422 VCU_VehWheelTorqMax_B 0;
BA_ "Remark" SG_ 422 VCU_VehWheelTorqMax_B "";
BA_ "EventCommandSignal" SG_ 422 VCU_GasPedalActPstforMRRVD_B 0;
BA_ "GatewayedSignals" SG_ 422 VCU_GasPedalActPstforMRRVD_B 0;
BA_ "GenSigInactiveValue" SG_ 422 VCU_GasPedalActPstforMRRVD_B 0;
BA_ "GenSigInvalidValue" SG_ 422 VCU_GasPedalActPstforMRRVD_B 0;
BA_ "GenSigSendType" SG_ 422 VCU_GasPedalActPstforMRRVD_B 1;
BA_ "GenSigStartValue" SG_ 422 VCU_GasPedalActPstforMRRVD_B 0;
BA_ "GenSigTimeoutValue" SG_ 422 VCU_GasPedalActPstforMRRVD_B 0;
BA_ "Remark" SG_ 422 VCU_GasPedalActPstforMRRVD_B "";
BA_ "EventCommandSignal" SG_ 422 VCU_AccElecECFail_B 0;
BA_ "GatewayedSignals" SG_ 422 VCU_AccElecECFail_B 0;
BA_ "GenSigInactiveValue" SG_ 422 VCU_AccElecECFail_B 0;
BA_ "GenSigInvalidValue" SG_ 422 VCU_AccElecECFail_B 0;
BA_ "GenSigSendType" SG_ 422 VCU_AccElecECFail_B 1;
BA_ "GenSigStartValue" SG_ 422 VCU_AccElecECFail_B 0;
BA_ "GenSigTimeoutValue" SG_ 422 VCU_AccElecECFail_B 0;
BA_ "Remark" SG_ 422 VCU_AccElecECFail_B "";
BA_ "EventCommandSignal" SG_ 422 VCU_AccDriverOrvd_B 0;
BA_ "GatewayedSignals" SG_ 422 VCU_AccDriverOrvd_B 0;
BA_ "GenSigInactiveValue" SG_ 422 VCU_AccDriverOrvd_B 0;
BA_ "GenSigInvalidValue" SG_ 422 VCU_AccDriverOrvd_B 0;
BA_ "GenSigSendType" SG_ 422 VCU_AccDriverOrvd_B 1;
BA_ "GenSigStartValue" SG_ 422 VCU_AccDriverOrvd_B 0;
BA_ "GenSigTimeoutValue" SG_ 422 VCU_AccDriverOrvd_B 0;
BA_ "Remark" SG_ 422 VCU_AccDriverOrvd_B "";
BA_ "EventCommandSignal" SG_ 422 VCU_APAAvailable_B 0;
BA_ "GatewayedSignals" SG_ 422 VCU_APAAvailable_B 0;
BA_ "GenSigInactiveValue" SG_ 422 VCU_APAAvailable_B 0;
BA_ "GenSigInvalidValue" SG_ 422 VCU_APAAvailable_B 0;
BA_ "GenSigSendType" SG_ 422 VCU_APAAvailable_B 1;
BA_ "GenSigStartValue" SG_ 422 VCU_APAAvailable_B 0;
BA_ "GenSigTimeoutValue" SG_ 422 VCU_APAAvailable_B 0;
BA_ "Remark" SG_ 422 VCU_APAAvailable_B "";
BA_ "EventCommandSignal" SG_ 422 VCU_APA_Resp_B 0;
BA_ "GatewayedSignals" SG_ 422 VCU_APA_Resp_B 0;
BA_ "GenSigInactiveValue" SG_ 422 VCU_APA_Resp_B 0;
BA_ "GenSigInvalidValue" SG_ 422 VCU_APA_Resp_B 0;
BA_ "GenSigSendType" SG_ 422 VCU_APA_Resp_B 1;
BA_ "GenSigStartValue" SG_ 422 VCU_APA_Resp_B 0;
BA_ "GenSigTimeoutValue" SG_ 422 VCU_APA_Resp_B 0;
BA_ "Remark" SG_ 422 VCU_APA_Resp_B "";
BA_ "EventCommandSignal" SG_ 422 VCU_GasPedalActPstforMRR_B 0;
BA_ "GatewayedSignals" SG_ 422 VCU_GasPedalActPstforMRR_B 0;
BA_ "GenSigInactiveValue" SG_ 422 VCU_GasPedalActPstforMRR_B 0;
BA_ "GenSigInvalidValue" SG_ 422 VCU_GasPedalActPstforMRR_B 0;
BA_ "GenSigSendType" SG_ 422 VCU_GasPedalActPstforMRR_B 1;
BA_ "GenSigStartValue" SG_ 422 VCU_GasPedalActPstforMRR_B 0;
BA_ "GenSigTimeoutValue" SG_ 422 VCU_GasPedalActPstforMRR_B 0;
BA_ "Remark" SG_ 422 VCU_GasPedalActPstforMRR_B "";
BA_ "EventCommandSignal" SG_ 422 VCU_AccPedalActPst_B 0;
BA_ "GatewayedSignals" SG_ 422 VCU_AccPedalActPst_B 0;
BA_ "GenSigInactiveValue" SG_ 422 VCU_AccPedalActPst_B 0;
BA_ "GenSigInvalidValue" SG_ 422 VCU_AccPedalActPst_B 0;
BA_ "GenSigSendType" SG_ 422 VCU_AccPedalActPst_B 1;
BA_ "GenSigStartValue" SG_ 422 VCU_AccPedalActPst_B 0;
BA_ "GenSigTimeoutValue" SG_ 422 VCU_AccPedalActPst_B 0;
BA_ "Remark" SG_ 422 VCU_AccPedalActPst_B "";
BA_ "EventCommandSignal" SG_ 422 VCU_BrkPedalSt_B 0;
BA_ "GatewayedSignals" SG_ 422 VCU_BrkPedalSt_B 0;
BA_ "GenSigInactiveValue" SG_ 422 VCU_BrkPedalSt_B 0;
BA_ "GenSigInvalidValue" SG_ 422 VCU_BrkPedalSt_B 0;
BA_ "GenSigSendType" SG_ 422 VCU_BrkPedalSt_B 1;
BA_ "GenSigStartValue" SG_ 422 VCU_BrkPedalSt_B 0;
BA_ "GenSigTimeoutValue" SG_ 422 VCU_BrkPedalSt_B 0;
BA_ "Remark" SG_ 422 VCU_BrkPedalSt_B "";
BA_ "EventCommandSignal" SG_ 422 VCU_BrkPedalStVD_B 0;
BA_ "GatewayedSignals" SG_ 422 VCU_BrkPedalStVD_B 0;
BA_ "GenSigInactiveValue" SG_ 422 VCU_BrkPedalStVD_B 0;
BA_ "GenSigInvalidValue" SG_ 422 VCU_BrkPedalStVD_B 0;
BA_ "GenSigSendType" SG_ 422 VCU_BrkPedalStVD_B 1;
BA_ "GenSigStartValue" SG_ 422 VCU_BrkPedalStVD_B 0;
BA_ "GenSigTimeoutValue" SG_ 422 VCU_BrkPedalStVD_B 0;
BA_ "Remark" SG_ 422 VCU_BrkPedalStVD_B "";
BA_ "EventCommandSignal" SG_ 422 VCU_AccPedalActPstVD_B 0;
BA_ "GatewayedSignals" SG_ 422 VCU_AccPedalActPstVD_B 0;
BA_ "GenSigInactiveValue" SG_ 422 VCU_AccPedalActPstVD_B 0;
BA_ "GenSigInvalidValue" SG_ 422 VCU_AccPedalActPstVD_B 0;
BA_ "GenSigSendType" SG_ 422 VCU_AccPedalActPstVD_B 1;
BA_ "GenSigStartValue" SG_ 422 VCU_AccPedalActPstVD_B 0;
BA_ "GenSigTimeoutValue" SG_ 422 VCU_AccPedalActPstVD_B 0;
BA_ "Remark" SG_ 422 VCU_AccPedalActPstVD_B "";
BA_ "EventCommandSignal" SG_ 422 VCU_AccTMCFail_B 0;
BA_ "GatewayedSignals" SG_ 422 VCU_AccTMCFail_B 0;
BA_ "GenSigInactiveValue" SG_ 422 VCU_AccTMCFail_B 0;
BA_ "GenSigInvalidValue" SG_ 422 VCU_AccTMCFail_B 0;
BA_ "GenSigSendType" SG_ 422 VCU_AccTMCFail_B 1;
BA_ "GenSigStartValue" SG_ 422 VCU_AccTMCFail_B 0;
BA_ "GenSigTimeoutValue" SG_ 422 VCU_AccTMCFail_B 0;
BA_ "Remark" SG_ 422 VCU_AccTMCFail_B "";
BA_ "EventCommandSignal" SG_ 619 EPB_FailSt_L 0;
BA_ "GatewayedSignals" SG_ 619 EPB_FailSt_L 0;
BA_ "GenSigInactiveValue" SG_ 619 EPB_FailSt_L 0;
BA_ "GenSigInvalidValue" SG_ 619 EPB_FailSt_L 0;
BA_ "GenSigSendType" SG_ 619 EPB_FailSt_L 1;
BA_ "GenSigStartValue" SG_ 619 EPB_FailSt_L 0;
BA_ "GenSigTimeoutValue" SG_ 619 EPB_FailSt_L 1;
BA_ "Remark" SG_ 619 EPB_FailSt_L "";
BA_ "EventCommandSignal" SG_ 619 EPB_ExtAvailable_L 0;
BA_ "GatewayedSignals" SG_ 619 EPB_ExtAvailable_L 0;
BA_ "GenSigInactiveValue" SG_ 619 EPB_ExtAvailable_L 0;
BA_ "GenSigInvalidValue" SG_ 619 EPB_ExtAvailable_L 0;
BA_ "GenSigSendType" SG_ 619 EPB_ExtAvailable_L 1;
BA_ "GenSigStartValue" SG_ 619 EPB_ExtAvailable_L 0;
BA_ "GenSigTimeoutValue" SG_ 619 EPB_ExtAvailable_L 0;
BA_ "Remark" SG_ 619 EPB_ExtAvailable_L "";
BA_ "EventCommandSignal" SG_ 619 EPB_ActuatorSt_L 0;
BA_ "GatewayedSignals" SG_ 619 EPB_ActuatorSt_L 0;
BA_ "GenSigInactiveValue" SG_ 619 EPB_ActuatorSt_L 0;
BA_ "GenSigInvalidValue" SG_ 619 EPB_ActuatorSt_L 0;
BA_ "GenSigSendType" SG_ 619 EPB_ActuatorSt_L 1;
BA_ "GenSigStartValue" SG_ 619 EPB_ActuatorSt_L 0;
BA_ "GenSigTimeoutValue" SG_ 619 EPB_ActuatorSt_L 0;
BA_ "Remark" SG_ 619 EPB_ActuatorSt_L "";
BA_ "EventCommandSignal" SG_ 1174 ADC_BigData 0;
BA_ "GatewayedSignals" SG_ 1174 ADC_BigData 0;
BA_ "GenSigInactiveValue" SG_ 1174 ADC_BigData 0;
BA_ "GenSigInvalidValue" SG_ 1174 ADC_BigData 0;
BA_ "GenSigSendType" SG_ 1174 ADC_BigData 1;
BA_ "GenSigStartValue" SG_ 1174 ADC_BigData 0;
BA_ "GenSigTimeoutValue" SG_ 1174 ADC_BigData 0;
BA_ "Remark" SG_ 1174 ADC_BigData "";
BA_ "EventCommandSignal" SG_ 728 ECS_1_CRC 0;
BA_ "GatewayedSignals" SG_ 728 ECS_1_CRC 0;
BA_ "GenSigInactiveValue" SG_ 728 ECS_1_CRC 0;
BA_ "GenSigInvalidValue" SG_ 728 ECS_1_CRC 0;
BA_ "GenSigSendType" SG_ 728 ECS_1_CRC 1;
BA_ "GenSigStartValue" SG_ 728 ECS_1_CRC 0;
BA_ "GenSigTimeoutValue" SG_ 728 ECS_1_CRC 0;
BA_ "Remark" SG_ 728 ECS_1_CRC "";
BA_ "EventCommandSignal" SG_ 728 ECS_1_Counter 0;
BA_ "GatewayedSignals" SG_ 728 ECS_1_Counter 0;
BA_ "GenSigInactiveValue" SG_ 728 ECS_1_Counter 0;
BA_ "GenSigInvalidValue" SG_ 728 ECS_1_Counter 0;
BA_ "GenSigSendType" SG_ 728 ECS_1_Counter 1;
BA_ "GenSigStartValue" SG_ 728 ECS_1_Counter 0;
BA_ "GenSigTimeoutValue" SG_ 728 ECS_1_Counter 0;
BA_ "Remark" SG_ 728 ECS_1_Counter "";
BA_ "EventCommandSignal" SG_ 728 SDC_SolenoidErrorStRR 0;
BA_ "GatewayedSignals" SG_ 728 SDC_SolenoidErrorStRR 0;
BA_ "GenSigInactiveValue" SG_ 728 SDC_SolenoidErrorStRR 0;
BA_ "GenSigInvalidValue" SG_ 728 SDC_SolenoidErrorStRR 3;
BA_ "GenSigSendType" SG_ 728 SDC_SolenoidErrorStRR 1;
BA_ "GenSigStartValue" SG_ 728 SDC_SolenoidErrorStRR 0;
BA_ "GenSigTimeoutValue" SG_ 728 SDC_SolenoidErrorStRR 3;
BA_ "Remark" SG_ 728 SDC_SolenoidErrorStRR "";
BA_ "EventCommandSignal" SG_ 728 CDC_ADCCtrlAvl 0;
BA_ "GatewayedSignals" SG_ 728 CDC_ADCCtrlAvl 0;
BA_ "GenSigInactiveValue" SG_ 728 CDC_ADCCtrlAvl 0;
BA_ "GenSigInvalidValue" SG_ 728 CDC_ADCCtrlAvl 0;
BA_ "GenSigSendType" SG_ 728 CDC_ADCCtrlAvl 1;
BA_ "GenSigStartValue" SG_ 728 CDC_ADCCtrlAvl 0;
BA_ "GenSigTimeoutValue" SG_ 728 CDC_ADCCtrlAvl 0;
BA_ "Remark" SG_ 728 CDC_ADCCtrlAvl "";
BA_ "EventCommandSignal" SG_ 728 CDC_ADCCtrlRespSts 0;
BA_ "GatewayedSignals" SG_ 728 CDC_ADCCtrlRespSts 0;
BA_ "GenSigInactiveValue" SG_ 728 CDC_ADCCtrlRespSts 0;
BA_ "GenSigInvalidValue" SG_ 728 CDC_ADCCtrlRespSts 0;
BA_ "GenSigSendType" SG_ 728 CDC_ADCCtrlRespSts 1;
BA_ "GenSigStartValue" SG_ 728 CDC_ADCCtrlRespSts 0;
BA_ "GenSigTimeoutValue" SG_ 728 CDC_ADCCtrlRespSts 0;
BA_ "Remark" SG_ 728 CDC_ADCCtrlRespSts "";
BA_ "EventCommandSignal" SG_ 728 SDC_ExternalReqMode 0;
BA_ "GatewayedSignals" SG_ 728 SDC_ExternalReqMode 0;
BA_ "GenSigInactiveValue" SG_ 728 SDC_ExternalReqMode 0;
BA_ "GenSigInvalidValue" SG_ 728 SDC_ExternalReqMode 7;
BA_ "GenSigSendType" SG_ 728 SDC_ExternalReqMode 1;
BA_ "GenSigStartValue" SG_ 728 SDC_ExternalReqMode 0;
BA_ "GenSigTimeoutValue" SG_ 728 SDC_ExternalReqMode 0;
BA_ "Remark" SG_ 728 SDC_ExternalReqMode "";
BA_ "EventCommandSignal" SG_ 728 SDC_CurrentDamperMode 0;
BA_ "GatewayedSignals" SG_ 728 SDC_CurrentDamperMode 0;
BA_ "GenSigInactiveValue" SG_ 728 SDC_CurrentDamperMode 0;
BA_ "GenSigInvalidValue" SG_ 728 SDC_CurrentDamperMode 0;
BA_ "GenSigSendType" SG_ 728 SDC_CurrentDamperMode 1;
BA_ "GenSigStartValue" SG_ 728 SDC_CurrentDamperMode 0;
BA_ "GenSigTimeoutValue" SG_ 728 SDC_CurrentDamperMode 0;
BA_ "Remark" SG_ 728 SDC_CurrentDamperMode "";
BA_ "EventCommandSignal" SG_ 728 SDC_WarningLampReq 0;
BA_ "GatewayedSignals" SG_ 728 SDC_WarningLampReq 0;
BA_ "GenSigInactiveValue" SG_ 728 SDC_WarningLampReq 0;
BA_ "GenSigInvalidValue" SG_ 728 SDC_WarningLampReq 0;
BA_ "GenSigSendType" SG_ 728 SDC_WarningLampReq 1;
BA_ "GenSigStartValue" SG_ 728 SDC_WarningLampReq 0;
BA_ "GenSigTimeoutValue" SG_ 728 SDC_WarningLampReq 1;
BA_ "Remark" SG_ 728 SDC_WarningLampReq "";
BA_ "EventCommandSignal" SG_ 728 SDC_ProhibitChangingMode 0;
BA_ "GatewayedSignals" SG_ 728 SDC_ProhibitChangingMode 0;
BA_ "GenSigInactiveValue" SG_ 728 SDC_ProhibitChangingMode 0;
BA_ "GenSigInvalidValue" SG_ 728 SDC_ProhibitChangingMode 0;
BA_ "GenSigSendType" SG_ 728 SDC_ProhibitChangingMode 1;
BA_ "GenSigStartValue" SG_ 728 SDC_ProhibitChangingMode 0;
BA_ "GenSigTimeoutValue" SG_ 728 SDC_ProhibitChangingMode 1;
BA_ "Remark" SG_ 728 SDC_ProhibitChangingMode "";
BA_ "EventCommandSignal" SG_ 728 SDC_BodyAccErrorStFL 0;
BA_ "GatewayedSignals" SG_ 728 SDC_BodyAccErrorStFL 0;
BA_ "GenSigInactiveValue" SG_ 728 SDC_BodyAccErrorStFL 0;
BA_ "GenSigInvalidValue" SG_ 728 SDC_BodyAccErrorStFL 0;
BA_ "GenSigSendType" SG_ 728 SDC_BodyAccErrorStFL 1;
BA_ "GenSigStartValue" SG_ 728 SDC_BodyAccErrorStFL 0;
BA_ "GenSigTimeoutValue" SG_ 728 SDC_BodyAccErrorStFL 1;
BA_ "Remark" SG_ 728 SDC_BodyAccErrorStFL "";
BA_ "EventCommandSignal" SG_ 728 SDC_BodyAccErrorStFR 0;
BA_ "GatewayedSignals" SG_ 728 SDC_BodyAccErrorStFR 0;
BA_ "GenSigInactiveValue" SG_ 728 SDC_BodyAccErrorStFR 0;
BA_ "GenSigInvalidValue" SG_ 728 SDC_BodyAccErrorStFR 0;
BA_ "GenSigSendType" SG_ 728 SDC_BodyAccErrorStFR 1;
BA_ "GenSigStartValue" SG_ 728 SDC_BodyAccErrorStFR 0;
BA_ "GenSigTimeoutValue" SG_ 728 SDC_BodyAccErrorStFR 1;
BA_ "Remark" SG_ 728 SDC_BodyAccErrorStFR "";
BA_ "EventCommandSignal" SG_ 728 SDC_BodyAccErrorStRr 0;
BA_ "GatewayedSignals" SG_ 728 SDC_BodyAccErrorStRr 0;
BA_ "GenSigInactiveValue" SG_ 728 SDC_BodyAccErrorStRr 0;
BA_ "GenSigInvalidValue" SG_ 728 SDC_BodyAccErrorStRr 0;
BA_ "GenSigSendType" SG_ 728 SDC_BodyAccErrorStRr 1;
BA_ "GenSigStartValue" SG_ 728 SDC_BodyAccErrorStRr 0;
BA_ "GenSigTimeoutValue" SG_ 728 SDC_BodyAccErrorStRr 1;
BA_ "Remark" SG_ 728 SDC_BodyAccErrorStRr "";
BA_ "EventCommandSignal" SG_ 728 SDC_WheelAccErrorStFL 0;
BA_ "GatewayedSignals" SG_ 728 SDC_WheelAccErrorStFL 0;
BA_ "GenSigInactiveValue" SG_ 728 SDC_WheelAccErrorStFL 0;
BA_ "GenSigInvalidValue" SG_ 728 SDC_WheelAccErrorStFL 0;
BA_ "GenSigSendType" SG_ 728 SDC_WheelAccErrorStFL 1;
BA_ "GenSigStartValue" SG_ 728 SDC_WheelAccErrorStFL 0;
BA_ "GenSigTimeoutValue" SG_ 728 SDC_WheelAccErrorStFL 1;
BA_ "Remark" SG_ 728 SDC_WheelAccErrorStFL "";
BA_ "EventCommandSignal" SG_ 728 SDC_WheelAccErrorStFR 0;
BA_ "GatewayedSignals" SG_ 728 SDC_WheelAccErrorStFR 0;
BA_ "GenSigInactiveValue" SG_ 728 SDC_WheelAccErrorStFR 0;
BA_ "GenSigInvalidValue" SG_ 728 SDC_WheelAccErrorStFR 0;
BA_ "GenSigSendType" SG_ 728 SDC_WheelAccErrorStFR 1;
BA_ "GenSigStartValue" SG_ 728 SDC_WheelAccErrorStFR 0;
BA_ "GenSigTimeoutValue" SG_ 728 SDC_WheelAccErrorStFR 1;
BA_ "Remark" SG_ 728 SDC_WheelAccErrorStFR "";
BA_ "EventCommandSignal" SG_ 728 SDC_SolenoidWorkSt 0;
BA_ "GatewayedSignals" SG_ 728 SDC_SolenoidWorkSt 0;
BA_ "GenSigInactiveValue" SG_ 728 SDC_SolenoidWorkSt 0;
BA_ "GenSigInvalidValue" SG_ 728 SDC_SolenoidWorkSt 3;
BA_ "GenSigSendType" SG_ 728 SDC_SolenoidWorkSt 1;
BA_ "GenSigStartValue" SG_ 728 SDC_SolenoidWorkSt 0;
BA_ "GenSigTimeoutValue" SG_ 728 SDC_SolenoidWorkSt 0;
BA_ "Remark" SG_ 728 SDC_SolenoidWorkSt "";
BA_ "EventCommandSignal" SG_ 728 CDC_FailureSt 0;
BA_ "GatewayedSignals" SG_ 728 CDC_FailureSt 0;
BA_ "GenSigInactiveValue" SG_ 728 CDC_FailureSt 0;
BA_ "GenSigInvalidValue" SG_ 728 CDC_FailureSt 0;
BA_ "GenSigSendType" SG_ 728 CDC_FailureSt 1;
BA_ "GenSigStartValue" SG_ 728 CDC_FailureSt 0;
BA_ "GenSigTimeoutValue" SG_ 728 CDC_FailureSt 255;
BA_ "Remark" SG_ 728 CDC_FailureSt "";
BA_ "EventCommandSignal" SG_ 728 CDC_ADCModState 0;
BA_ "GatewayedSignals" SG_ 728 CDC_ADCModState 0;
BA_ "GenSigInactiveValue" SG_ 728 CDC_ADCModState 0;
BA_ "GenSigInvalidValue" SG_ 728 CDC_ADCModState 0;
BA_ "GenSigSendType" SG_ 728 CDC_ADCModState 1;
BA_ "GenSigStartValue" SG_ 728 CDC_ADCModState 0;
BA_ "GenSigTimeoutValue" SG_ 728 CDC_ADCModState 0;
BA_ "Remark" SG_ 728 CDC_ADCModState "";
BA_ "EventCommandSignal" SG_ 459 ECS_2_CRC 0;
BA_ "GatewayedSignals" SG_ 459 ECS_2_CRC 0;
BA_ "GenSigInactiveValue" SG_ 459 ECS_2_CRC 0;
BA_ "GenSigInvalidValue" SG_ 459 ECS_2_CRC 0;
BA_ "GenSigSendType" SG_ 459 ECS_2_CRC 1;
BA_ "GenSigStartValue" SG_ 459 ECS_2_CRC 0;
BA_ "GenSigTimeoutValue" SG_ 459 ECS_2_CRC 0;
BA_ "Remark" SG_ 459 ECS_2_CRC "";
BA_ "EventCommandSignal" SG_ 459 ECS_2_Counter 0;
BA_ "GatewayedSignals" SG_ 459 ECS_2_Counter 0;
BA_ "GenSigInactiveValue" SG_ 459 ECS_2_Counter 0;
BA_ "GenSigInvalidValue" SG_ 459 ECS_2_Counter 0;
BA_ "GenSigSendType" SG_ 459 ECS_2_Counter 1;
BA_ "GenSigStartValue" SG_ 459 ECS_2_Counter 0;
BA_ "GenSigTimeoutValue" SG_ 459 ECS_2_Counter 0;
BA_ "Remark" SG_ 459 ECS_2_Counter "";
BA_ "EventCommandSignal" SG_ 459 AS_SuspHeightFL 0;
BA_ "GatewayedSignals" SG_ 459 AS_SuspHeightFL 0;
BA_ "GenSigInactiveValue" SG_ 459 AS_SuspHeightFL 0;
BA_ "GenSigInvalidValue" SG_ 459 AS_SuspHeightFL 4095;
BA_ "GenSigSendType" SG_ 459 AS_SuspHeightFL 1;
BA_ "GenSigStartValue" SG_ 459 AS_SuspHeightFL 0;
BA_ "GenSigTimeoutValue" SG_ 459 AS_SuspHeightFL 1500;
BA_ "Remark" SG_ 459 AS_SuspHeightFL "";
BA_ "EventCommandSignal" SG_ 459 AS_SuspHeightFR 0;
BA_ "GatewayedSignals" SG_ 459 AS_SuspHeightFR 0;
BA_ "GenSigInactiveValue" SG_ 459 AS_SuspHeightFR 0;
BA_ "GenSigInvalidValue" SG_ 459 AS_SuspHeightFR 4095;
BA_ "GenSigSendType" SG_ 459 AS_SuspHeightFR 1;
BA_ "GenSigStartValue" SG_ 459 AS_SuspHeightFR 0;
BA_ "GenSigTimeoutValue" SG_ 459 AS_SuspHeightFR 1500;
BA_ "Remark" SG_ 459 AS_SuspHeightFR "";
BA_ "EventCommandSignal" SG_ 459 AS_SuspHeightRL 0;
BA_ "GatewayedSignals" SG_ 459 AS_SuspHeightRL 0;
BA_ "GenSigInactiveValue" SG_ 459 AS_SuspHeightRL 0;
BA_ "GenSigInvalidValue" SG_ 459 AS_SuspHeightRL 4095;
BA_ "GenSigSendType" SG_ 459 AS_SuspHeightRL 1;
BA_ "GenSigStartValue" SG_ 459 AS_SuspHeightRL 0;
BA_ "GenSigTimeoutValue" SG_ 459 AS_SuspHeightRL 1500;
BA_ "Remark" SG_ 459 AS_SuspHeightRL "";
BA_ "EventCommandSignal" SG_ 459 AS_SuspHeightRR 0;
BA_ "GatewayedSignals" SG_ 459 AS_SuspHeightRR 0;
BA_ "GenSigInactiveValue" SG_ 459 AS_SuspHeightRR 0;
BA_ "GenSigInvalidValue" SG_ 459 AS_SuspHeightRR 4095;
BA_ "GenSigSendType" SG_ 459 AS_SuspHeightRR 1;
BA_ "GenSigStartValue" SG_ 459 AS_SuspHeightRR 0;
BA_ "GenSigTimeoutValue" SG_ 459 AS_SuspHeightRR 1500;
BA_ "Remark" SG_ 459 AS_SuspHeightRR "";
BA_ "EventCommandSignal" SG_ 459 AS_SuspHeightFLVD 0;
BA_ "GatewayedSignals" SG_ 459 AS_SuspHeightFLVD 0;
BA_ "GenSigInactiveValue" SG_ 459 AS_SuspHeightFLVD 0;
BA_ "GenSigInvalidValue" SG_ 459 AS_SuspHeightFLVD 0;
BA_ "GenSigSendType" SG_ 459 AS_SuspHeightFLVD 1;
BA_ "GenSigStartValue" SG_ 459 AS_SuspHeightFLVD 1;
BA_ "GenSigTimeoutValue" SG_ 459 AS_SuspHeightFLVD 0;
BA_ "Remark" SG_ 459 AS_SuspHeightFLVD "";
BA_ "EventCommandSignal" SG_ 459 AS_SuspHeightFRVD 0;
BA_ "GatewayedSignals" SG_ 459 AS_SuspHeightFRVD 0;
BA_ "GenSigInactiveValue" SG_ 459 AS_SuspHeightFRVD 0;
BA_ "GenSigInvalidValue" SG_ 459 AS_SuspHeightFRVD 0;
BA_ "GenSigSendType" SG_ 459 AS_SuspHeightFRVD 1;
BA_ "GenSigStartValue" SG_ 459 AS_SuspHeightFRVD 1;
BA_ "GenSigTimeoutValue" SG_ 459 AS_SuspHeightFRVD 0;
BA_ "Remark" SG_ 459 AS_SuspHeightFRVD "";
BA_ "EventCommandSignal" SG_ 459 AS_SuspHeightRLVD 0;
BA_ "GatewayedSignals" SG_ 459 AS_SuspHeightRLVD 0;
BA_ "GenSigInactiveValue" SG_ 459 AS_SuspHeightRLVD 0;
BA_ "GenSigInvalidValue" SG_ 459 AS_SuspHeightRLVD 0;
BA_ "GenSigSendType" SG_ 459 AS_SuspHeightRLVD 1;
BA_ "GenSigStartValue" SG_ 459 AS_SuspHeightRLVD 1;
BA_ "GenSigTimeoutValue" SG_ 459 AS_SuspHeightRLVD 0;
BA_ "Remark" SG_ 459 AS_SuspHeightRLVD "";
BA_ "EventCommandSignal" SG_ 459 AS_SuspHeightRRVD 0;
BA_ "GatewayedSignals" SG_ 459 AS_SuspHeightRRVD 0;
BA_ "GenSigInactiveValue" SG_ 459 AS_SuspHeightRRVD 0;
BA_ "GenSigInvalidValue" SG_ 459 AS_SuspHeightRRVD 0;
BA_ "GenSigSendType" SG_ 459 AS_SuspHeightRRVD 1;
BA_ "GenSigStartValue" SG_ 459 AS_SuspHeightRRVD 1;
BA_ "GenSigTimeoutValue" SG_ 459 AS_SuspHeightRRVD 0;
BA_ "Remark" SG_ 459 AS_SuspHeightRRVD "";
BA_ "EventCommandSignal" SG_ 459 AS_SuspHeightSensorFLSt 0;
BA_ "GatewayedSignals" SG_ 459 AS_SuspHeightSensorFLSt 0;
BA_ "GenSigInactiveValue" SG_ 459 AS_SuspHeightSensorFLSt 0;
BA_ "GenSigInvalidValue" SG_ 459 AS_SuspHeightSensorFLSt 0;
BA_ "GenSigSendType" SG_ 459 AS_SuspHeightSensorFLSt 1;
BA_ "GenSigStartValue" SG_ 459 AS_SuspHeightSensorFLSt 0;
BA_ "GenSigTimeoutValue" SG_ 459 AS_SuspHeightSensorFLSt 1;
BA_ "Remark" SG_ 459 AS_SuspHeightSensorFLSt "";
BA_ "EventCommandSignal" SG_ 459 AS_SuspHeightSensorFRSt 0;
BA_ "GatewayedSignals" SG_ 459 AS_SuspHeightSensorFRSt 0;
BA_ "GenSigInactiveValue" SG_ 459 AS_SuspHeightSensorFRSt 0;
BA_ "GenSigInvalidValue" SG_ 459 AS_SuspHeightSensorFRSt 0;
BA_ "GenSigSendType" SG_ 459 AS_SuspHeightSensorFRSt 1;
BA_ "GenSigStartValue" SG_ 459 AS_SuspHeightSensorFRSt 0;
BA_ "GenSigTimeoutValue" SG_ 459 AS_SuspHeightSensorFRSt 1;
BA_ "Remark" SG_ 459 AS_SuspHeightSensorFRSt "";
BA_ "EventCommandSignal" SG_ 459 AS_SuspHeightSensorRLSt 0;
BA_ "GatewayedSignals" SG_ 459 AS_SuspHeightSensorRLSt 0;
BA_ "GenSigInactiveValue" SG_ 459 AS_SuspHeightSensorRLSt 0;
BA_ "GenSigInvalidValue" SG_ 459 AS_SuspHeightSensorRLSt 0;
BA_ "GenSigSendType" SG_ 459 AS_SuspHeightSensorRLSt 1;
BA_ "GenSigStartValue" SG_ 459 AS_SuspHeightSensorRLSt 0;
BA_ "GenSigTimeoutValue" SG_ 459 AS_SuspHeightSensorRLSt 1;
BA_ "Remark" SG_ 459 AS_SuspHeightSensorRLSt "";
BA_ "EventCommandSignal" SG_ 459 AS_SuspHeightSensoRRSt 0;
BA_ "GatewayedSignals" SG_ 459 AS_SuspHeightSensoRRSt 0;
BA_ "GenSigInactiveValue" SG_ 459 AS_SuspHeightSensoRRSt 0;
BA_ "GenSigInvalidValue" SG_ 459 AS_SuspHeightSensoRRSt 0;
BA_ "GenSigSendType" SG_ 459 AS_SuspHeightSensoRRSt 1;
BA_ "GenSigStartValue" SG_ 459 AS_SuspHeightSensoRRSt 0;
BA_ "GenSigTimeoutValue" SG_ 459 AS_SuspHeightSensoRRSt 1;
BA_ "Remark" SG_ 459 AS_SuspHeightSensoRRSt "";
BA_ "EventCommandSignal" SG_ 459 AS_MaintanceModeSt 0;
BA_ "GatewayedSignals" SG_ 459 AS_MaintanceModeSt 0;
BA_ "GenSigInactiveValue" SG_ 459 AS_MaintanceModeSt 0;
BA_ "GenSigInvalidValue" SG_ 459 AS_MaintanceModeSt 0;
BA_ "GenSigSendType" SG_ 459 AS_MaintanceModeSt 1;
BA_ "GenSigStartValue" SG_ 459 AS_MaintanceModeSt 0;
BA_ "GenSigTimeoutValue" SG_ 459 AS_MaintanceModeSt 0;
BA_ "Remark" SG_ 459 AS_MaintanceModeSt "";
BA_ "EventCommandSignal" SG_ 459 ECS_AVDCReqModeAvailable 0;
BA_ "GatewayedSignals" SG_ 459 ECS_AVDCReqModeAvailable 0;
BA_ "GenSigInactiveValue" SG_ 459 ECS_AVDCReqModeAvailable 0;
BA_ "GenSigInvalidValue" SG_ 459 ECS_AVDCReqModeAvailable 0;
BA_ "GenSigSendType" SG_ 459 ECS_AVDCReqModeAvailable 1;
BA_ "GenSigStartValue" SG_ 459 ECS_AVDCReqModeAvailable 0;
BA_ "GenSigTimeoutValue" SG_ 459 ECS_AVDCReqModeAvailable 0;
BA_ "Remark" SG_ 459 ECS_AVDCReqModeAvailable "";
BA_ "EventCommandSignal" SG_ 459 ECS_AVDCReqMode 0;
BA_ "GatewayedSignals" SG_ 459 ECS_AVDCReqMode 0;
BA_ "GenSigInactiveValue" SG_ 459 ECS_AVDCReqMode 0;
BA_ "GenSigInvalidValue" SG_ 459 ECS_AVDCReqMode 0;
BA_ "GenSigSendType" SG_ 459 ECS_AVDCReqMode 1;
BA_ "GenSigStartValue" SG_ 459 ECS_AVDCReqMode 0;
BA_ "GenSigTimeoutValue" SG_ 459 ECS_AVDCReqMode 0;
BA_ "Remark" SG_ 459 ECS_AVDCReqMode "";
BA_ "EventCommandSignal" SG_ 459 AS_FrontAxleSuspSt 0;
BA_ "GatewayedSignals" SG_ 459 AS_FrontAxleSuspSt 0;
BA_ "GenSigInactiveValue" SG_ 459 AS_FrontAxleSuspSt 0;
BA_ "GenSigInvalidValue" SG_ 459 AS_FrontAxleSuspSt 0;
BA_ "GenSigSendType" SG_ 459 AS_FrontAxleSuspSt 1;
BA_ "GenSigStartValue" SG_ 459 AS_FrontAxleSuspSt 0;
BA_ "GenSigTimeoutValue" SG_ 459 AS_FrontAxleSuspSt 0;
BA_ "Remark" SG_ 459 AS_FrontAxleSuspSt "";
BA_ "EventCommandSignal" SG_ 459 AS_RearAxleSuspSt 0;
BA_ "GatewayedSignals" SG_ 459 AS_RearAxleSuspSt 0;
BA_ "GenSigInactiveValue" SG_ 459 AS_RearAxleSuspSt 0;
BA_ "GenSigInvalidValue" SG_ 459 AS_RearAxleSuspSt 0;
BA_ "GenSigSendType" SG_ 459 AS_RearAxleSuspSt 1;
BA_ "GenSigStartValue" SG_ 459 AS_RearAxleSuspSt 0;
BA_ "GenSigTimeoutValue" SG_ 459 AS_RearAxleSuspSt 0;
BA_ "Remark" SG_ 459 AS_RearAxleSuspSt "";
BA_ "EventCommandSignal" SG_ 459 AS_HeightWarningSt 0;
BA_ "GatewayedSignals" SG_ 459 AS_HeightWarningSt 0;
BA_ "GenSigInactiveValue" SG_ 459 AS_HeightWarningSt 0;
BA_ "GenSigInvalidValue" SG_ 459 AS_HeightWarningSt 0;
BA_ "GenSigSendType" SG_ 459 AS_HeightWarningSt 1;
BA_ "GenSigStartValue" SG_ 459 AS_HeightWarningSt 0;
BA_ "GenSigTimeoutValue" SG_ 459 AS_HeightWarningSt 0;
BA_ "Remark" SG_ 459 AS_HeightWarningSt "";
BA_ "EventCommandSignal" SG_ 459 AS_CurrentLevel 0;
BA_ "GatewayedSignals" SG_ 459 AS_CurrentLevel 0;
BA_ "GenSigInactiveValue" SG_ 459 AS_CurrentLevel 0;
BA_ "GenSigInvalidValue" SG_ 459 AS_CurrentLevel 0;
BA_ "GenSigSendType" SG_ 459 AS_CurrentLevel 1;
BA_ "GenSigStartValue" SG_ 459 AS_CurrentLevel 0;
BA_ "GenSigTimeoutValue" SG_ 459 AS_CurrentLevel 0;
BA_ "Remark" SG_ 459 AS_CurrentLevel "";
BA_ "EventCommandSignal" SG_ 459 AS_TargetLevel 0;
BA_ "GatewayedSignals" SG_ 459 AS_TargetLevel 0;
BA_ "GenSigInactiveValue" SG_ 459 AS_TargetLevel 0;
BA_ "GenSigInvalidValue" SG_ 459 AS_TargetLevel 0;
BA_ "GenSigSendType" SG_ 459 AS_TargetLevel 1;
BA_ "GenSigStartValue" SG_ 459 AS_TargetLevel 0;
BA_ "GenSigTimeoutValue" SG_ 459 AS_TargetLevel 0;
BA_ "Remark" SG_ 459 AS_TargetLevel "";
BA_ "EventCommandSignal" SG_ 459 AS_ASMode 0;
BA_ "GatewayedSignals" SG_ 459 AS_ASMode 0;
BA_ "GenSigInactiveValue" SG_ 459 AS_ASMode 0;
BA_ "GenSigInvalidValue" SG_ 459 AS_ASMode 0;
BA_ "GenSigSendType" SG_ 459 AS_ASMode 1;
BA_ "GenSigStartValue" SG_ 459 AS_ASMode 0;
BA_ "GenSigTimeoutValue" SG_ 459 AS_ASMode 0;
BA_ "Remark" SG_ 459 AS_ASMode "";
BA_ "EventCommandSignal" SG_ 459 AS_SysFaultSt 0;
BA_ "GatewayedSignals" SG_ 459 AS_SysFaultSt 0;
BA_ "GenSigInactiveValue" SG_ 459 AS_SysFaultSt 0;
BA_ "GenSigInvalidValue" SG_ 459 AS_SysFaultSt 0;
BA_ "GenSigSendType" SG_ 459 AS_SysFaultSt 1;
BA_ "GenSigStartValue" SG_ 459 AS_SysFaultSt 0;
BA_ "GenSigTimeoutValue" SG_ 459 AS_SysFaultSt 2;
BA_ "Remark" SG_ 459 AS_SysFaultSt "";
BA_ "EventCommandSignal" SG_ 459 AS_OverHeatingSt 0;
BA_ "GatewayedSignals" SG_ 459 AS_OverHeatingSt 0;
BA_ "GenSigInactiveValue" SG_ 459 AS_OverHeatingSt 0;
BA_ "GenSigInvalidValue" SG_ 459 AS_OverHeatingSt 0;
BA_ "GenSigSendType" SG_ 459 AS_OverHeatingSt 1;
BA_ "GenSigStartValue" SG_ 459 AS_OverHeatingSt 0;
BA_ "GenSigTimeoutValue" SG_ 459 AS_OverHeatingSt 0;
BA_ "Remark" SG_ 459 AS_OverHeatingSt "";
BA_ "EventCommandSignal" SG_ 459 AS_SysOperationSt 0;
BA_ "GatewayedSignals" SG_ 459 AS_SysOperationSt 0;
BA_ "GenSigInactiveValue" SG_ 459 AS_SysOperationSt 0;
BA_ "GenSigInvalidValue" SG_ 459 AS_SysOperationSt 0;
BA_ "GenSigSendType" SG_ 459 AS_SysOperationSt 1;
BA_ "GenSigStartValue" SG_ 459 AS_SysOperationSt 0;
BA_ "GenSigTimeoutValue" SG_ 459 AS_SysOperationSt 0;
BA_ "Remark" SG_ 459 AS_SysOperationSt "";
BA_ "EventCommandSignal" SG_ 459 AS_OverLoadSt 0;
BA_ "GatewayedSignals" SG_ 459 AS_OverLoadSt 0;
BA_ "GenSigInactiveValue" SG_ 459 AS_OverLoadSt 0;
BA_ "GenSigInvalidValue" SG_ 459 AS_OverLoadSt 0;
BA_ "GenSigSendType" SG_ 459 AS_OverLoadSt 1;
BA_ "GenSigStartValue" SG_ 459 AS_OverLoadSt 0;
BA_ "GenSigTimeoutValue" SG_ 459 AS_OverLoadSt 0;
BA_ "Remark" SG_ 459 AS_OverLoadSt "";
BA_ "EventCommandSignal" SG_ 459 AS_OverTorsionSt 0;
BA_ "GatewayedSignals" SG_ 459 AS_OverTorsionSt 0;
BA_ "GenSigInactiveValue" SG_ 459 AS_OverTorsionSt 0;
BA_ "GenSigInvalidValue" SG_ 459 AS_OverTorsionSt 0;
BA_ "GenSigSendType" SG_ 459 AS_OverTorsionSt 1;
BA_ "GenSigStartValue" SG_ 459 AS_OverTorsionSt 0;
BA_ "GenSigTimeoutValue" SG_ 459 AS_OverTorsionSt 0;
BA_ "Remark" SG_ 459 AS_OverTorsionSt "";
BA_ "EventCommandSignal" SG_ 459 AS_ManufacModeSt 0;
BA_ "GatewayedSignals" SG_ 459 AS_ManufacModeSt 0;
BA_ "GenSigInactiveValue" SG_ 459 AS_ManufacModeSt 0;
BA_ "GenSigInvalidValue" SG_ 459 AS_ManufacModeSt 0;
BA_ "GenSigSendType" SG_ 459 AS_ManufacModeSt 1;
BA_ "GenSigStartValue" SG_ 459 AS_ManufacModeSt 0;
BA_ "GenSigTimeoutValue" SG_ 459 AS_ManufacModeSt 0;
BA_ "Remark" SG_ 459 AS_ManufacModeSt "";
BA_ "EventCommandSignal" SG_ 459 AS_ASIndividualMode 0;
BA_ "GatewayedSignals" SG_ 459 AS_ASIndividualMode 0;
BA_ "GenSigInactiveValue" SG_ 459 AS_ASIndividualMode 0;
BA_ "GenSigInvalidValue" SG_ 459 AS_ASIndividualMode 0;
BA_ "GenSigSendType" SG_ 459 AS_ASIndividualMode 1;
BA_ "GenSigStartValue" SG_ 459 AS_ASIndividualMode 0;
BA_ "GenSigTimeoutValue" SG_ 459 AS_ASIndividualMode 0;
BA_ "Remark" SG_ 459 AS_ASIndividualMode "";
BA_ "EventCommandSignal" SG_ 459 AS_ADCStfnCtrlAvl 0;
BA_ "GatewayedSignals" SG_ 459 AS_ADCStfnCtrlAvl 0;
BA_ "GenSigInactiveValue" SG_ 459 AS_ADCStfnCtrlAvl 0;
BA_ "GenSigInvalidValue" SG_ 459 AS_ADCStfnCtrlAvl 0;
BA_ "GenSigSendType" SG_ 459 AS_ADCStfnCtrlAvl 1;
BA_ "GenSigStartValue" SG_ 459 AS_ADCStfnCtrlAvl 0;
BA_ "GenSigTimeoutValue" SG_ 459 AS_ADCStfnCtrlAvl 0;
BA_ "Remark" SG_ 459 AS_ADCStfnCtrlAvl "";
BA_ "EventCommandSignal" SG_ 459 AS_ADCStfnState 0;
BA_ "GatewayedSignals" SG_ 459 AS_ADCStfnState 0;
BA_ "GenSigInactiveValue" SG_ 459 AS_ADCStfnState 0;
BA_ "GenSigInvalidValue" SG_ 459 AS_ADCStfnState 0;
BA_ "GenSigSendType" SG_ 459 AS_ADCStfnState 1;
BA_ "GenSigStartValue" SG_ 459 AS_ADCStfnState 0;
BA_ "GenSigTimeoutValue" SG_ 459 AS_ADCStfnState 0;
BA_ "Remark" SG_ 459 AS_ADCStfnState "";
BA_ "EventCommandSignal" SG_ 359 BCS_1_B_CRC 0;
BA_ "GatewayedSignals" SG_ 359 BCS_1_B_CRC 0;
BA_ "GenSigInactiveValue" SG_ 359 BCS_1_B_CRC 0;
BA_ "GenSigInvalidValue" SG_ 359 BCS_1_B_CRC 0;
BA_ "GenSigSendType" SG_ 359 BCS_1_B_CRC 1;
BA_ "GenSigStartValue" SG_ 359 BCS_1_B_CRC 0;
BA_ "GenSigTimeoutValue" SG_ 359 BCS_1_B_CRC 0;
BA_ "Remark" SG_ 359 BCS_1_B_CRC "";
BA_ "EventCommandSignal" SG_ 359 BCS_1_B_Counter 0;
BA_ "GatewayedSignals" SG_ 359 BCS_1_B_Counter 0;
BA_ "GenSigInactiveValue" SG_ 359 BCS_1_B_Counter 0;
BA_ "GenSigInvalidValue" SG_ 359 BCS_1_B_Counter 0;
BA_ "GenSigSendType" SG_ 359 BCS_1_B_Counter 1;
BA_ "GenSigStartValue" SG_ 359 BCS_1_B_Counter 0;
BA_ "GenSigTimeoutValue" SG_ 359 BCS_1_B_Counter 0;
BA_ "Remark" SG_ 359 BCS_1_B_Counter "";
BA_ "EventCommandSignal" SG_ 359 BCS_FLWheelSpd_B 0;
BA_ "GatewayedSignals" SG_ 359 BCS_FLWheelSpd_B 0;
BA_ "GenSigInactiveValue" SG_ 359 BCS_FLWheelSpd_B 0;
BA_ "GenSigInvalidValue" SG_ 359 BCS_FLWheelSpd_B 0;
BA_ "GenSigSendType" SG_ 359 BCS_FLWheelSpd_B 1;
BA_ "GenSigStartValue" SG_ 359 BCS_FLWheelSpd_B 0;
BA_ "GenSigTimeoutValue" SG_ 359 BCS_FLWheelSpd_B 0;
BA_ "Remark" SG_ 359 BCS_FLWheelSpd_B "";
BA_ "EventCommandSignal" SG_ 359 BCS_FLWheelSpdVD_B 0;
BA_ "GatewayedSignals" SG_ 359 BCS_FLWheelSpdVD_B 0;
BA_ "GenSigInactiveValue" SG_ 359 BCS_FLWheelSpdVD_B 0;
BA_ "GenSigInvalidValue" SG_ 359 BCS_FLWheelSpdVD_B 0;
BA_ "GenSigSendType" SG_ 359 BCS_FLWheelSpdVD_B 1;
BA_ "GenSigStartValue" SG_ 359 BCS_FLWheelSpdVD_B 0;
BA_ "GenSigTimeoutValue" SG_ 359 BCS_FLWheelSpdVD_B 0;
BA_ "Remark" SG_ 359 BCS_FLWheelSpdVD_B "";
BA_ "EventCommandSignal" SG_ 359 BCS_FLWheelRotatedDirection_B 0;
BA_ "GatewayedSignals" SG_ 359 BCS_FLWheelRotatedDirection_B 0;
BA_ "GenSigInactiveValue" SG_ 359 BCS_FLWheelRotatedDirection_B 0;
BA_ "GenSigInvalidValue" SG_ 359 BCS_FLWheelRotatedDirection_B 0;
BA_ "GenSigSendType" SG_ 359 BCS_FLWheelRotatedDirection_B 1;
BA_ "GenSigStartValue" SG_ 359 BCS_FLWheelRotatedDirection_B 0;
BA_ "GenSigTimeoutValue" SG_ 359 BCS_FLWheelRotatedDirection_B 0;
BA_ "Remark" SG_ 359 BCS_FLWheelRotatedDirection_B "";
BA_ "EventCommandSignal" SG_ 359 BCS_FLWheelRotatedDirectionVD_B 0;
BA_ "GatewayedSignals" SG_ 359 BCS_FLWheelRotatedDirectionVD_B 0;
BA_ "GenSigInactiveValue" SG_ 359 BCS_FLWheelRotatedDirectionVD_B 0;
BA_ "GenSigInvalidValue" SG_ 359 BCS_FLWheelRotatedDirectionVD_B 0;
BA_ "GenSigSendType" SG_ 359 BCS_FLWheelRotatedDirectionVD_B 1;
BA_ "GenSigStartValue" SG_ 359 BCS_FLWheelRotatedDirectionVD_B 0;
BA_ "GenSigTimeoutValue" SG_ 359 BCS_FLWheelRotatedDirectionVD_B 0;
BA_ "Remark" SG_ 359 BCS_FLWheelRotatedDirectionVD_B "";
BA_ "EventCommandSignal" SG_ 359 BCS_FRWheelSpd_B 0;
BA_ "GatewayedSignals" SG_ 359 BCS_FRWheelSpd_B 0;
BA_ "GenSigInactiveValue" SG_ 359 BCS_FRWheelSpd_B 0;
BA_ "GenSigInvalidValue" SG_ 359 BCS_FRWheelSpd_B 0;
BA_ "GenSigSendType" SG_ 359 BCS_FRWheelSpd_B 1;
BA_ "GenSigStartValue" SG_ 359 BCS_FRWheelSpd_B 0;
BA_ "GenSigTimeoutValue" SG_ 359 BCS_FRWheelSpd_B 0;
BA_ "Remark" SG_ 359 BCS_FRWheelSpd_B "";
BA_ "EventCommandSignal" SG_ 359 BCS_FRWheelSpdVD_B 0;
BA_ "GatewayedSignals" SG_ 359 BCS_FRWheelSpdVD_B 0;
BA_ "GenSigInactiveValue" SG_ 359 BCS_FRWheelSpdVD_B 0;
BA_ "GenSigInvalidValue" SG_ 359 BCS_FRWheelSpdVD_B 0;
BA_ "GenSigSendType" SG_ 359 BCS_FRWheelSpdVD_B 1;
BA_ "GenSigStartValue" SG_ 359 BCS_FRWheelSpdVD_B 0;
BA_ "GenSigTimeoutValue" SG_ 359 BCS_FRWheelSpdVD_B 0;
BA_ "Remark" SG_ 359 BCS_FRWheelSpdVD_B "";
BA_ "EventCommandSignal" SG_ 359 BCS_FRWheelRotatedDirection_B 0;
BA_ "GatewayedSignals" SG_ 359 BCS_FRWheelRotatedDirection_B 0;
BA_ "GenSigInactiveValue" SG_ 359 BCS_FRWheelRotatedDirection_B 0;
BA_ "GenSigInvalidValue" SG_ 359 BCS_FRWheelRotatedDirection_B 0;
BA_ "GenSigSendType" SG_ 359 BCS_FRWheelRotatedDirection_B 1;
BA_ "GenSigStartValue" SG_ 359 BCS_FRWheelRotatedDirection_B 0;
BA_ "GenSigTimeoutValue" SG_ 359 BCS_FRWheelRotatedDirection_B 0;
BA_ "Remark" SG_ 359 BCS_FRWheelRotatedDirection_B "";
BA_ "EventCommandSignal" SG_ 359 BCS_FRWheelRotatedDirectionVD_B 0;
BA_ "GatewayedSignals" SG_ 359 BCS_FRWheelRotatedDirectionVD_B 0;
BA_ "GenSigInactiveValue" SG_ 359 BCS_FRWheelRotatedDirectionVD_B 0;
BA_ "GenSigInvalidValue" SG_ 359 BCS_FRWheelRotatedDirectionVD_B 0;
BA_ "GenSigSendType" SG_ 359 BCS_FRWheelRotatedDirectionVD_B 1;
BA_ "GenSigStartValue" SG_ 359 BCS_FRWheelRotatedDirectionVD_B 0;
BA_ "GenSigTimeoutValue" SG_ 359 BCS_FRWheelRotatedDirectionVD_B 0;
BA_ "Remark" SG_ 359 BCS_FRWheelRotatedDirectionVD_B "";
BA_ "EventCommandSignal" SG_ 359 BCS_RLWheelSpd_B 0;
BA_ "GatewayedSignals" SG_ 359 BCS_RLWheelSpd_B 0;
BA_ "GenSigInactiveValue" SG_ 359 BCS_RLWheelSpd_B 0;
BA_ "GenSigInvalidValue" SG_ 359 BCS_RLWheelSpd_B 0;
BA_ "GenSigSendType" SG_ 359 BCS_RLWheelSpd_B 1;
BA_ "GenSigStartValue" SG_ 359 BCS_RLWheelSpd_B 0;
BA_ "GenSigTimeoutValue" SG_ 359 BCS_RLWheelSpd_B 0;
BA_ "Remark" SG_ 359 BCS_RLWheelSpd_B "";
BA_ "EventCommandSignal" SG_ 359 BCS_RLWheelSpdVD_B 0;
BA_ "GatewayedSignals" SG_ 359 BCS_RLWheelSpdVD_B 0;
BA_ "GenSigInactiveValue" SG_ 359 BCS_RLWheelSpdVD_B 0;
BA_ "GenSigInvalidValue" SG_ 359 BCS_RLWheelSpdVD_B 0;
BA_ "GenSigSendType" SG_ 359 BCS_RLWheelSpdVD_B 1;
BA_ "GenSigStartValue" SG_ 359 BCS_RLWheelSpdVD_B 0;
BA_ "GenSigTimeoutValue" SG_ 359 BCS_RLWheelSpdVD_B 0;
BA_ "Remark" SG_ 359 BCS_RLWheelSpdVD_B "";
BA_ "EventCommandSignal" SG_ 359 BCS_RLWheelRotatedDirection_B 0;
BA_ "GatewayedSignals" SG_ 359 BCS_RLWheelRotatedDirection_B 0;
BA_ "GenSigInactiveValue" SG_ 359 BCS_RLWheelRotatedDirection_B 0;
BA_ "GenSigInvalidValue" SG_ 359 BCS_RLWheelRotatedDirection_B 0;
BA_ "GenSigSendType" SG_ 359 BCS_RLWheelRotatedDirection_B 1;
BA_ "GenSigStartValue" SG_ 359 BCS_RLWheelRotatedDirection_B 0;
BA_ "GenSigTimeoutValue" SG_ 359 BCS_RLWheelRotatedDirection_B 0;
BA_ "Remark" SG_ 359 BCS_RLWheelRotatedDirection_B "";
BA_ "EventCommandSignal" SG_ 359 BCS_RLWheelRotatedDirectionVD_B 0;
BA_ "GatewayedSignals" SG_ 359 BCS_RLWheelRotatedDirectionVD_B 0;
BA_ "GenSigInactiveValue" SG_ 359 BCS_RLWheelRotatedDirectionVD_B 0;
BA_ "GenSigInvalidValue" SG_ 359 BCS_RLWheelRotatedDirectionVD_B 0;
BA_ "GenSigSendType" SG_ 359 BCS_RLWheelRotatedDirectionVD_B 1;
BA_ "GenSigStartValue" SG_ 359 BCS_RLWheelRotatedDirectionVD_B 0;
BA_ "GenSigTimeoutValue" SG_ 359 BCS_RLWheelRotatedDirectionVD_B 0;
BA_ "Remark" SG_ 359 BCS_RLWheelRotatedDirectionVD_B "";
BA_ "EventCommandSignal" SG_ 359 BCS_RRWheelSpd_B 0;
BA_ "GatewayedSignals" SG_ 359 BCS_RRWheelSpd_B 0;
BA_ "GenSigInactiveValue" SG_ 359 BCS_RRWheelSpd_B 0;
BA_ "GenSigInvalidValue" SG_ 359 BCS_RRWheelSpd_B 0;
BA_ "GenSigSendType" SG_ 359 BCS_RRWheelSpd_B 1;
BA_ "GenSigStartValue" SG_ 359 BCS_RRWheelSpd_B 0;
BA_ "GenSigTimeoutValue" SG_ 359 BCS_RRWheelSpd_B 0;
BA_ "Remark" SG_ 359 BCS_RRWheelSpd_B "";
BA_ "EventCommandSignal" SG_ 359 BCS_RRWheelSpdVD_B 0;
BA_ "GatewayedSignals" SG_ 359 BCS_RRWheelSpdVD_B 0;
BA_ "GenSigInactiveValue" SG_ 359 BCS_RRWheelSpdVD_B 0;
BA_ "GenSigInvalidValue" SG_ 359 BCS_RRWheelSpdVD_B 0;
BA_ "GenSigSendType" SG_ 359 BCS_RRWheelSpdVD_B 1;
BA_ "GenSigStartValue" SG_ 359 BCS_RRWheelSpdVD_B 0;
BA_ "GenSigTimeoutValue" SG_ 359 BCS_RRWheelSpdVD_B 0;
BA_ "Remark" SG_ 359 BCS_RRWheelSpdVD_B "";
BA_ "EventCommandSignal" SG_ 359 BCS_RRWheelRotatedDirection_B 0;
BA_ "GatewayedSignals" SG_ 359 BCS_RRWheelRotatedDirection_B 0;
BA_ "GenSigInactiveValue" SG_ 359 BCS_RRWheelRotatedDirection_B 0;
BA_ "GenSigInvalidValue" SG_ 359 BCS_RRWheelRotatedDirection_B 0;
BA_ "GenSigSendType" SG_ 359 BCS_RRWheelRotatedDirection_B 1;
BA_ "GenSigStartValue" SG_ 359 BCS_RRWheelRotatedDirection_B 0;
BA_ "GenSigTimeoutValue" SG_ 359 BCS_RRWheelRotatedDirection_B 0;
BA_ "Remark" SG_ 359 BCS_RRWheelRotatedDirection_B "";
BA_ "EventCommandSignal" SG_ 359 BCS_RRWheelRotatedDirectionVD_B 0;
BA_ "GatewayedSignals" SG_ 359 BCS_RRWheelRotatedDirectionVD_B 0;
BA_ "GenSigInactiveValue" SG_ 359 BCS_RRWheelRotatedDirectionVD_B 0;
BA_ "GenSigInvalidValue" SG_ 359 BCS_RRWheelRotatedDirectionVD_B 0;
BA_ "GenSigSendType" SG_ 359 BCS_RRWheelRotatedDirectionVD_B 1;
BA_ "GenSigStartValue" SG_ 359 BCS_RRWheelRotatedDirectionVD_B 0;
BA_ "GenSigTimeoutValue" SG_ 359 BCS_RRWheelRotatedDirectionVD_B 0;
BA_ "Remark" SG_ 359 BCS_RRWheelRotatedDirectionVD_B "";
BA_ "EventCommandSignal" SG_ 359 BCS_HHCCtrlSt_B 0;
BA_ "GatewayedSignals" SG_ 359 BCS_HHCCtrlSt_B 0;
BA_ "GenSigInactiveValue" SG_ 359 BCS_HHCCtrlSt_B 0;
BA_ "GenSigInvalidValue" SG_ 359 BCS_HHCCtrlSt_B 0;
BA_ "GenSigSendType" SG_ 359 BCS_HHCCtrlSt_B 1;
BA_ "GenSigStartValue" SG_ 359 BCS_HHCCtrlSt_B 0;
BA_ "GenSigTimeoutValue" SG_ 359 BCS_HHCCtrlSt_B 0;
BA_ "Remark" SG_ 359 BCS_HHCCtrlSt_B "";
BA_ "EventCommandSignal" SG_ 359 BCS_HDCCtrlSt_B 0;
BA_ "GatewayedSignals" SG_ 359 BCS_HDCCtrlSt_B 0;
BA_ "GenSigInactiveValue" SG_ 359 BCS_HDCCtrlSt_B 0;
BA_ "GenSigInvalidValue" SG_ 359 BCS_HDCCtrlSt_B 0;
BA_ "GenSigSendType" SG_ 359 BCS_HDCCtrlSt_B 1;
BA_ "GenSigStartValue" SG_ 359 BCS_HDCCtrlSt_B 0;
BA_ "GenSigTimeoutValue" SG_ 359 BCS_HDCCtrlSt_B 0;
BA_ "Remark" SG_ 359 BCS_HDCCtrlSt_B "";
BA_ "EventCommandSignal" SG_ 359 BCS_HDCErrSt_B 0;
BA_ "GatewayedSignals" SG_ 359 BCS_HDCErrSt_B 0;
BA_ "GenSigInactiveValue" SG_ 359 BCS_HDCErrSt_B 0;
BA_ "GenSigInvalidValue" SG_ 359 BCS_HDCErrSt_B 0;
BA_ "GenSigSendType" SG_ 359 BCS_HDCErrSt_B 1;
BA_ "GenSigStartValue" SG_ 359 BCS_HDCErrSt_B 0;
BA_ "GenSigTimeoutValue" SG_ 359 BCS_HDCErrSt_B 1;
BA_ "Remark" SG_ 359 BCS_HDCErrSt_B "";
BA_ "EventCommandSignal" SG_ 359 BCS_FLWheelSpdEdgesSum_B 0;
BA_ "GatewayedSignals" SG_ 359 BCS_FLWheelSpdEdgesSum_B 0;
BA_ "GenSigInactiveValue" SG_ 359 BCS_FLWheelSpdEdgesSum_B 0;
BA_ "GenSigInvalidValue" SG_ 359 BCS_FLWheelSpdEdgesSum_B 0;
BA_ "GenSigSendType" SG_ 359 BCS_FLWheelSpdEdgesSum_B 1;
BA_ "GenSigStartValue" SG_ 359 BCS_FLWheelSpdEdgesSum_B 0;
BA_ "GenSigTimeoutValue" SG_ 359 BCS_FLWheelSpdEdgesSum_B 0;
BA_ "Remark" SG_ 359 BCS_FLWheelSpdEdgesSum_B "";
BA_ "EventCommandSignal" SG_ 359 BCS_FRWheelSpdEdgesSum_B 0;
BA_ "GatewayedSignals" SG_ 359 BCS_FRWheelSpdEdgesSum_B 0;
BA_ "GenSigInactiveValue" SG_ 359 BCS_FRWheelSpdEdgesSum_B 0;
BA_ "GenSigInvalidValue" SG_ 359 BCS_FRWheelSpdEdgesSum_B 0;
BA_ "GenSigSendType" SG_ 359 BCS_FRWheelSpdEdgesSum_B 1;
BA_ "GenSigStartValue" SG_ 359 BCS_FRWheelSpdEdgesSum_B 0;
BA_ "GenSigTimeoutValue" SG_ 359 BCS_FRWheelSpdEdgesSum_B 0;
BA_ "Remark" SG_ 359 BCS_FRWheelSpdEdgesSum_B "";
BA_ "EventCommandSignal" SG_ 359 BCS_RLWheelSpdEdgesSum_B 0;
BA_ "GatewayedSignals" SG_ 359 BCS_RLWheelSpdEdgesSum_B 0;
BA_ "GenSigInactiveValue" SG_ 359 BCS_RLWheelSpdEdgesSum_B 0;
BA_ "GenSigInvalidValue" SG_ 359 BCS_RLWheelSpdEdgesSum_B 0;
BA_ "GenSigSendType" SG_ 359 BCS_RLWheelSpdEdgesSum_B 1;
BA_ "GenSigStartValue" SG_ 359 BCS_RLWheelSpdEdgesSum_B 0;
BA_ "GenSigTimeoutValue" SG_ 359 BCS_RLWheelSpdEdgesSum_B 0;
BA_ "Remark" SG_ 359 BCS_RLWheelSpdEdgesSum_B "";
BA_ "EventCommandSignal" SG_ 359 BCS_RRWheelSpdEdgesSum_B 0;
BA_ "GatewayedSignals" SG_ 359 BCS_RRWheelSpdEdgesSum_B 0;
BA_ "GenSigInactiveValue" SG_ 359 BCS_RRWheelSpdEdgesSum_B 0;
BA_ "GenSigInvalidValue" SG_ 359 BCS_RRWheelSpdEdgesSum_B 0;
BA_ "GenSigSendType" SG_ 359 BCS_RRWheelSpdEdgesSum_B 1;
BA_ "GenSigStartValue" SG_ 359 BCS_RRWheelSpdEdgesSum_B 0;
BA_ "GenSigTimeoutValue" SG_ 359 BCS_RRWheelSpdEdgesSum_B 0;
BA_ "Remark" SG_ 359 BCS_RRWheelSpdEdgesSum_B "";
BA_ "EventCommandSignal" SG_ 359 BCS_FLWheelSpdEdgesSumVD_B 0;
BA_ "GatewayedSignals" SG_ 359 BCS_FLWheelSpdEdgesSumVD_B 0;
BA_ "GenSigInactiveValue" SG_ 359 BCS_FLWheelSpdEdgesSumVD_B 0;
BA_ "GenSigInvalidValue" SG_ 359 BCS_FLWheelSpdEdgesSumVD_B 0;
BA_ "GenSigSendType" SG_ 359 BCS_FLWheelSpdEdgesSumVD_B 1;
BA_ "GenSigStartValue" SG_ 359 BCS_FLWheelSpdEdgesSumVD_B 0;
BA_ "GenSigTimeoutValue" SG_ 359 BCS_FLWheelSpdEdgesSumVD_B 0;
BA_ "Remark" SG_ 359 BCS_FLWheelSpdEdgesSumVD_B "";
BA_ "EventCommandSignal" SG_ 359 BCS_FRWheelSpdEdgesSumVD_B 0;
BA_ "GatewayedSignals" SG_ 359 BCS_FRWheelSpdEdgesSumVD_B 0;
BA_ "GenSigInactiveValue" SG_ 359 BCS_FRWheelSpdEdgesSumVD_B 0;
BA_ "GenSigInvalidValue" SG_ 359 BCS_FRWheelSpdEdgesSumVD_B 0;
BA_ "GenSigSendType" SG_ 359 BCS_FRWheelSpdEdgesSumVD_B 1;
BA_ "GenSigStartValue" SG_ 359 BCS_FRWheelSpdEdgesSumVD_B 0;
BA_ "GenSigTimeoutValue" SG_ 359 BCS_FRWheelSpdEdgesSumVD_B 0;
BA_ "Remark" SG_ 359 BCS_FRWheelSpdEdgesSumVD_B "";
BA_ "EventCommandSignal" SG_ 359 BCS_RLWheelSpdEdgesSumVD_B 0;
BA_ "GatewayedSignals" SG_ 359 BCS_RLWheelSpdEdgesSumVD_B 0;
BA_ "GenSigInactiveValue" SG_ 359 BCS_RLWheelSpdEdgesSumVD_B 0;
BA_ "GenSigInvalidValue" SG_ 359 BCS_RLWheelSpdEdgesSumVD_B 0;
BA_ "GenSigSendType" SG_ 359 BCS_RLWheelSpdEdgesSumVD_B 1;
BA_ "GenSigStartValue" SG_ 359 BCS_RLWheelSpdEdgesSumVD_B 0;
BA_ "GenSigTimeoutValue" SG_ 359 BCS_RLWheelSpdEdgesSumVD_B 0;
BA_ "Remark" SG_ 359 BCS_RLWheelSpdEdgesSumVD_B "";
BA_ "EventCommandSignal" SG_ 359 BCS_RRWheelSpdEdgesSumVD_B 0;
BA_ "GatewayedSignals" SG_ 359 BCS_RRWheelSpdEdgesSumVD_B 0;
BA_ "GenSigInactiveValue" SG_ 359 BCS_RRWheelSpdEdgesSumVD_B 0;
BA_ "GenSigInvalidValue" SG_ 359 BCS_RRWheelSpdEdgesSumVD_B 0;
BA_ "GenSigSendType" SG_ 359 BCS_RRWheelSpdEdgesSumVD_B 1;
BA_ "GenSigStartValue" SG_ 359 BCS_RRWheelSpdEdgesSumVD_B 0;
BA_ "GenSigTimeoutValue" SG_ 359 BCS_RRWheelSpdEdgesSumVD_B 0;
BA_ "Remark" SG_ 359 BCS_RRWheelSpdEdgesSumVD_B "";
BA_ "EventCommandSignal" SG_ 359 BCS_FLWheelRotatedDirectionAPA_B 0;
BA_ "GatewayedSignals" SG_ 359 BCS_FLWheelRotatedDirectionAPA_B 0;
BA_ "GenSigInactiveValue" SG_ 359 BCS_FLWheelRotatedDirectionAPA_B 0;
BA_ "GenSigInvalidValue" SG_ 359 BCS_FLWheelRotatedDirectionAPA_B 0;
BA_ "GenSigSendType" SG_ 359 BCS_FLWheelRotatedDirectionAPA_B 1;
BA_ "GenSigStartValue" SG_ 359 BCS_FLWheelRotatedDirectionAPA_B 0;
BA_ "GenSigTimeoutValue" SG_ 359 BCS_FLWheelRotatedDirectionAPA_B 0;
BA_ "Remark" SG_ 359 BCS_FLWheelRotatedDirectionAPA_B "";
BA_ "EventCommandSignal" SG_ 359 BCS_FRWheelRotatedDirectionAPA_B 0;
BA_ "GatewayedSignals" SG_ 359 BCS_FRWheelRotatedDirectionAPA_B 0;
BA_ "GenSigInactiveValue" SG_ 359 BCS_FRWheelRotatedDirectionAPA_B 0;
BA_ "GenSigInvalidValue" SG_ 359 BCS_FRWheelRotatedDirectionAPA_B 0;
BA_ "GenSigSendType" SG_ 359 BCS_FRWheelRotatedDirectionAPA_B 1;
BA_ "GenSigStartValue" SG_ 359 BCS_FRWheelRotatedDirectionAPA_B 0;
BA_ "GenSigTimeoutValue" SG_ 359 BCS_FRWheelRotatedDirectionAPA_B 0;
BA_ "Remark" SG_ 359 BCS_FRWheelRotatedDirectionAPA_B "";
BA_ "EventCommandSignal" SG_ 359 BCS_RLWheelRotatedDirectionAPA_B 0;
BA_ "GatewayedSignals" SG_ 359 BCS_RLWheelRotatedDirectionAPA_B 0;
BA_ "GenSigInactiveValue" SG_ 359 BCS_RLWheelRotatedDirectionAPA_B 0;
BA_ "GenSigInvalidValue" SG_ 359 BCS_RLWheelRotatedDirectionAPA_B 0;
BA_ "GenSigSendType" SG_ 359 BCS_RLWheelRotatedDirectionAPA_B 1;
BA_ "GenSigStartValue" SG_ 359 BCS_RLWheelRotatedDirectionAPA_B 0;
BA_ "GenSigTimeoutValue" SG_ 359 BCS_RLWheelRotatedDirectionAPA_B 0;
BA_ "Remark" SG_ 359 BCS_RLWheelRotatedDirectionAPA_B "";
BA_ "EventCommandSignal" SG_ 359 BCS_RRWheelRotatedDirectionAPA_B 0;
BA_ "GatewayedSignals" SG_ 359 BCS_RRWheelRotatedDirectionAPA_B 0;
BA_ "GenSigInactiveValue" SG_ 359 BCS_RRWheelRotatedDirectionAPA_B 0;
BA_ "GenSigInvalidValue" SG_ 359 BCS_RRWheelRotatedDirectionAPA_B 0;
BA_ "GenSigSendType" SG_ 359 BCS_RRWheelRotatedDirectionAPA_B 1;
BA_ "GenSigStartValue" SG_ 359 BCS_RRWheelRotatedDirectionAPA_B 0;
BA_ "GenSigTimeoutValue" SG_ 359 BCS_RRWheelRotatedDirectionAPA_B 0;
BA_ "Remark" SG_ 359 BCS_RRWheelRotatedDirectionAPA_B "";
BA_ "EventCommandSignal" SG_ 359 BCS_ParkingReqToEPB_B 0;
BA_ "GatewayedSignals" SG_ 359 BCS_ParkingReqToEPB_B 0;
BA_ "GenSigInactiveValue" SG_ 359 BCS_ParkingReqToEPB_B 0;
BA_ "GenSigInvalidValue" SG_ 359 BCS_ParkingReqToEPB_B 0;
BA_ "GenSigSendType" SG_ 359 BCS_ParkingReqToEPB_B 1;
BA_ "GenSigStartValue" SG_ 359 BCS_ParkingReqToEPB_B 0;
BA_ "GenSigTimeoutValue" SG_ 359 BCS_ParkingReqToEPB_B 0;
BA_ "Remark" SG_ 359 BCS_ParkingReqToEPB_B "";
BA_ "EventCommandSignal" SG_ 359 BCS_VDCOff_B 0;
BA_ "GatewayedSignals" SG_ 359 BCS_VDCOff_B 0;
BA_ "GenSigInactiveValue" SG_ 359 BCS_VDCOff_B 0;
BA_ "GenSigInvalidValue" SG_ 359 BCS_VDCOff_B 0;
BA_ "GenSigSendType" SG_ 359 BCS_VDCOff_B 1;
BA_ "GenSigStartValue" SG_ 359 BCS_VDCOff_B 0;
BA_ "GenSigTimeoutValue" SG_ 359 BCS_VDCOff_B 0;
BA_ "Remark" SG_ 359 BCS_VDCOff_B "";
BA_ "EventCommandSignal" SG_ 359 BCS_AVHSt_B 0;
BA_ "GatewayedSignals" SG_ 359 BCS_AVHSt_B 0;
BA_ "GenSigInactiveValue" SG_ 359 BCS_AVHSt_B 0;
BA_ "GenSigInvalidValue" SG_ 359 BCS_AVHSt_B 0;
BA_ "GenSigSendType" SG_ 359 BCS_AVHSt_B 1;
BA_ "GenSigStartValue" SG_ 359 BCS_AVHSt_B 0;
BA_ "GenSigTimeoutValue" SG_ 359 BCS_AVHSt_B 0;
BA_ "Remark" SG_ 359 BCS_AVHSt_B "";
BA_ "EventCommandSignal" SG_ 359 BCS_AVHAvailable_B 0;
BA_ "GatewayedSignals" SG_ 359 BCS_AVHAvailable_B 0;
BA_ "GenSigInactiveValue" SG_ 359 BCS_AVHAvailable_B 0;
BA_ "GenSigInvalidValue" SG_ 359 BCS_AVHAvailable_B 0;
BA_ "GenSigSendType" SG_ 359 BCS_AVHAvailable_B 1;
BA_ "GenSigStartValue" SG_ 359 BCS_AVHAvailable_B 0;
BA_ "GenSigTimeoutValue" SG_ 359 BCS_AVHAvailable_B 0;
BA_ "Remark" SG_ 359 BCS_AVHAvailable_B "";
BA_ "EventCommandSignal" SG_ 359 BCS_TCSOff_B 0;
BA_ "GatewayedSignals" SG_ 359 BCS_TCSOff_B 0;
BA_ "GenSigInactiveValue" SG_ 359 BCS_TCSOff_B 0;
BA_ "GenSigInvalidValue" SG_ 359 BCS_TCSOff_B 0;
BA_ "GenSigSendType" SG_ 359 BCS_TCSOff_B 1;
BA_ "GenSigStartValue" SG_ 359 BCS_TCSOff_B 0;
BA_ "GenSigTimeoutValue" SG_ 359 BCS_TCSOff_B 0;
BA_ "Remark" SG_ 359 BCS_TCSOff_B "";
BA_ "EventCommandSignal" SG_ 359 BCS_BrakeOverHeat_B 0;
BA_ "GatewayedSignals" SG_ 359 BCS_BrakeOverHeat_B 0;
BA_ "GenSigInactiveValue" SG_ 359 BCS_BrakeOverHeat_B 0;
BA_ "GenSigInvalidValue" SG_ 359 BCS_BrakeOverHeat_B 0;
BA_ "GenSigSendType" SG_ 359 BCS_BrakeOverHeat_B 1;
BA_ "GenSigStartValue" SG_ 359 BCS_BrakeOverHeat_B 0;
BA_ "GenSigTimeoutValue" SG_ 359 BCS_BrakeOverHeat_B 0;
BA_ "Remark" SG_ 359 BCS_BrakeOverHeat_B "";
BA_ "EventCommandSignal" SG_ 359 BCS_ABAactive_B 0;
BA_ "GatewayedSignals" SG_ 359 BCS_ABAactive_B 0;
BA_ "GenSigInactiveValue" SG_ 359 BCS_ABAactive_B 0;
BA_ "GenSigInvalidValue" SG_ 359 BCS_ABAactive_B 0;
BA_ "GenSigSendType" SG_ 359 BCS_ABAactive_B 1;
BA_ "GenSigStartValue" SG_ 359 BCS_ABAactive_B 0;
BA_ "GenSigTimeoutValue" SG_ 359 BCS_ABAactive_B 0;
BA_ "Remark" SG_ 359 BCS_ABAactive_B "";
BA_ "EventCommandSignal" SG_ 359 BCS_ABAavailable_B 0;
BA_ "GatewayedSignals" SG_ 359 BCS_ABAavailable_B 0;
BA_ "GenSigInactiveValue" SG_ 359 BCS_ABAavailable_B 0;
BA_ "GenSigInvalidValue" SG_ 359 BCS_ABAavailable_B 0;
BA_ "GenSigSendType" SG_ 359 BCS_ABAavailable_B 1;
BA_ "GenSigStartValue" SG_ 359 BCS_ABAavailable_B 0;
BA_ "GenSigTimeoutValue" SG_ 359 BCS_ABAavailable_B 0;
BA_ "Remark" SG_ 359 BCS_ABAavailable_B "";
BA_ "EventCommandSignal" SG_ 359 BCS_ABPActive_B 0;
BA_ "GatewayedSignals" SG_ 359 BCS_ABPActive_B 0;
BA_ "GenSigInactiveValue" SG_ 359 BCS_ABPActive_B 0;
BA_ "GenSigInvalidValue" SG_ 359 BCS_ABPActive_B 0;
BA_ "GenSigSendType" SG_ 359 BCS_ABPActive_B 1;
BA_ "GenSigStartValue" SG_ 359 BCS_ABPActive_B 0;
BA_ "GenSigTimeoutValue" SG_ 359 BCS_ABPActive_B 0;
BA_ "Remark" SG_ 359 BCS_ABPActive_B "";
BA_ "EventCommandSignal" SG_ 359 BCS_ABPAvailable_B 0;
BA_ "GatewayedSignals" SG_ 359 BCS_ABPAvailable_B 0;
BA_ "GenSigInactiveValue" SG_ 359 BCS_ABPAvailable_B 0;
BA_ "GenSigInvalidValue" SG_ 359 BCS_ABPAvailable_B 0;
BA_ "GenSigSendType" SG_ 359 BCS_ABPAvailable_B 1;
BA_ "GenSigStartValue" SG_ 359 BCS_ABPAvailable_B 0;
BA_ "GenSigTimeoutValue" SG_ 359 BCS_ABPAvailable_B 0;
BA_ "Remark" SG_ 359 BCS_ABPAvailable_B "";
BA_ "EventCommandSignal" SG_ 359 BCS_AEBActive_B 0;
BA_ "GatewayedSignals" SG_ 359 BCS_AEBActive_B 0;
BA_ "GenSigInactiveValue" SG_ 359 BCS_AEBActive_B 0;
BA_ "GenSigInvalidValue" SG_ 359 BCS_AEBActive_B 0;
BA_ "GenSigSendType" SG_ 359 BCS_AEBActive_B 1;
BA_ "GenSigStartValue" SG_ 359 BCS_AEBActive_B 0;
BA_ "GenSigTimeoutValue" SG_ 359 BCS_AEBActive_B 0;
BA_ "Remark" SG_ 359 BCS_AEBActive_B "";
BA_ "EventCommandSignal" SG_ 359 BCS_AEBAvailable_B 0;
BA_ "GatewayedSignals" SG_ 359 BCS_AEBAvailable_B 0;
BA_ "GenSigInactiveValue" SG_ 359 BCS_AEBAvailable_B 0;
BA_ "GenSigInvalidValue" SG_ 359 BCS_AEBAvailable_B 0;
BA_ "GenSigSendType" SG_ 359 BCS_AEBAvailable_B 1;
BA_ "GenSigStartValue" SG_ 359 BCS_AEBAvailable_B 0;
BA_ "GenSigTimeoutValue" SG_ 359 BCS_AEBAvailable_B 0;
BA_ "Remark" SG_ 359 BCS_AEBAvailable_B "";
BA_ "EventCommandSignal" SG_ 359 BCS_AWBActive_B 0;
BA_ "GatewayedSignals" SG_ 359 BCS_AWBActive_B 0;
BA_ "GenSigInactiveValue" SG_ 359 BCS_AWBActive_B 0;
BA_ "GenSigInvalidValue" SG_ 359 BCS_AWBActive_B 0;
BA_ "GenSigSendType" SG_ 359 BCS_AWBActive_B 1;
BA_ "GenSigStartValue" SG_ 359 BCS_AWBActive_B 0;
BA_ "GenSigTimeoutValue" SG_ 359 BCS_AWBActive_B 0;
BA_ "Remark" SG_ 359 BCS_AWBActive_B "";
BA_ "EventCommandSignal" SG_ 359 BCS_AWBAvailable_B 0;
BA_ "GatewayedSignals" SG_ 359 BCS_AWBAvailable_B 0;
BA_ "GenSigInactiveValue" SG_ 359 BCS_AWBAvailable_B 0;
BA_ "GenSigInvalidValue" SG_ 359 BCS_AWBAvailable_B 0;
BA_ "GenSigSendType" SG_ 359 BCS_AWBAvailable_B 1;
BA_ "GenSigStartValue" SG_ 359 BCS_AWBAvailable_B 0;
BA_ "GenSigTimeoutValue" SG_ 359 BCS_AWBAvailable_B 0;
BA_ "Remark" SG_ 359 BCS_AWBAvailable_B "";
BA_ "EventCommandSignal" SG_ 359 BCS_AVHStandby_B 0;
BA_ "GatewayedSignals" SG_ 359 BCS_AVHStandby_B 0;
BA_ "GenSigInactiveValue" SG_ 359 BCS_AVHStandby_B 0;
BA_ "GenSigInvalidValue" SG_ 359 BCS_AVHStandby_B 0;
BA_ "GenSigSendType" SG_ 359 BCS_AVHStandby_B 1;
BA_ "GenSigStartValue" SG_ 359 BCS_AVHStandby_B 0;
BA_ "GenSigTimeoutValue" SG_ 359 BCS_AVHStandby_B 0;
BA_ "Remark" SG_ 359 BCS_AVHStandby_B "";
BA_ "EventCommandSignal" SG_ 359 BCS_AEBBAActive_B 0;
BA_ "GatewayedSignals" SG_ 359 BCS_AEBBAActive_B 0;
BA_ "GenSigInactiveValue" SG_ 359 BCS_AEBBAActive_B 0;
BA_ "GenSigInvalidValue" SG_ 359 BCS_AEBBAActive_B 0;
BA_ "GenSigSendType" SG_ 359 BCS_AEBBAActive_B 1;
BA_ "GenSigStartValue" SG_ 359 BCS_AEBBAActive_B 0;
BA_ "GenSigTimeoutValue" SG_ 359 BCS_AEBBAActive_B 0;
BA_ "Remark" SG_ 359 BCS_AEBBAActive_B "";
BA_ "EventCommandSignal" SG_ 359 BCS_VehicleStandStillSt_B 0;
BA_ "GatewayedSignals" SG_ 359 BCS_VehicleStandStillSt_B 0;
BA_ "GenSigInactiveValue" SG_ 359 BCS_VehicleStandStillSt_B 0;
BA_ "GenSigInvalidValue" SG_ 359 BCS_VehicleStandStillSt_B 0;
BA_ "GenSigSendType" SG_ 359 BCS_VehicleStandStillSt_B 1;
BA_ "GenSigStartValue" SG_ 359 BCS_VehicleStandStillSt_B 0;
BA_ "GenSigTimeoutValue" SG_ 359 BCS_VehicleStandStillSt_B 0;
BA_ "Remark" SG_ 359 BCS_VehicleStandStillSt_B "";
BA_ "EventCommandSignal" SG_ 359 IPB_InputRodStroke_B 0;
BA_ "GatewayedSignals" SG_ 359 IPB_InputRodStroke_B 0;
BA_ "GenSigInactiveValue" SG_ 359 IPB_InputRodStroke_B 0;
BA_ "GenSigInvalidValue" SG_ 359 IPB_InputRodStroke_B 0;
BA_ "GenSigSendType" SG_ 359 IPB_InputRodStroke_B 1;
BA_ "GenSigStartValue" SG_ 359 IPB_InputRodStroke_B 100;
BA_ "GenSigTimeoutValue" SG_ 359 IPB_InputRodStroke_B 0;
BA_ "Remark" SG_ 359 IPB_InputRodStroke_B "";
BA_ "EventCommandSignal" SG_ 359 IPB_PlungerPressureSt_B 0;
BA_ "GatewayedSignals" SG_ 359 IPB_PlungerPressureSt_B 0;
BA_ "GenSigInactiveValue" SG_ 359 IPB_PlungerPressureSt_B 0;
BA_ "GenSigInvalidValue" SG_ 359 IPB_PlungerPressureSt_B 0;
BA_ "GenSigSendType" SG_ 359 IPB_PlungerPressureSt_B 1;
BA_ "GenSigStartValue" SG_ 359 IPB_PlungerPressureSt_B 0;
BA_ "GenSigTimeoutValue" SG_ 359 IPB_PlungerPressureSt_B 0;
BA_ "Remark" SG_ 359 IPB_PlungerPressureSt_B "";
BA_ "EventCommandSignal" SG_ 359 BCS_RAEBAvailable_B 0;
BA_ "GatewayedSignals" SG_ 359 BCS_RAEBAvailable_B 0;
BA_ "GenSigInactiveValue" SG_ 359 BCS_RAEBAvailable_B 0;
BA_ "GenSigInvalidValue" SG_ 359 BCS_RAEBAvailable_B 0;
BA_ "GenSigSendType" SG_ 359 BCS_RAEBAvailable_B 1;
BA_ "GenSigStartValue" SG_ 359 BCS_RAEBAvailable_B 0;
BA_ "GenSigTimeoutValue" SG_ 359 BCS_RAEBAvailable_B 0;
BA_ "Remark" SG_ 359 BCS_RAEBAvailable_B "";
BA_ "EventCommandSignal" SG_ 359 BCS_RAEBActive_B 0;
BA_ "GatewayedSignals" SG_ 359 BCS_RAEBActive_B 0;
BA_ "GenSigInactiveValue" SG_ 359 BCS_RAEBActive_B 0;
BA_ "GenSigInvalidValue" SG_ 359 BCS_RAEBActive_B 0;
BA_ "GenSigSendType" SG_ 359 BCS_RAEBActive_B 1;
BA_ "GenSigStartValue" SG_ 359 BCS_RAEBActive_B 0;
BA_ "GenSigTimeoutValue" SG_ 359 BCS_RAEBActive_B 0;
BA_ "Remark" SG_ 359 BCS_RAEBActive_B "";
BA_ "EventCommandSignal" SG_ 359 IPB_InputRodStrokeSt_B 0;
BA_ "GatewayedSignals" SG_ 359 IPB_InputRodStrokeSt_B 0;
BA_ "GenSigInactiveValue" SG_ 359 IPB_InputRodStrokeSt_B 0;
BA_ "GenSigInvalidValue" SG_ 359 IPB_InputRodStrokeSt_B 0;
BA_ "GenSigSendType" SG_ 359 IPB_InputRodStrokeSt_B 1;
BA_ "GenSigStartValue" SG_ 359 IPB_InputRodStrokeSt_B 0;
BA_ "GenSigTimeoutValue" SG_ 359 IPB_InputRodStrokeSt_B 0;
BA_ "Remark" SG_ 359 IPB_InputRodStrokeSt_B "";
BA_ "EventCommandSignal" SG_ 359 IPB_PlungerPressure_B 0;
BA_ "GatewayedSignals" SG_ 359 IPB_PlungerPressure_B 0;
BA_ "GenSigInactiveValue" SG_ 359 IPB_PlungerPressure_B 0;
BA_ "GenSigInvalidValue" SG_ 359 IPB_PlungerPressure_B 0;
BA_ "GenSigSendType" SG_ 359 IPB_PlungerPressure_B 1;
BA_ "GenSigStartValue" SG_ 359 IPB_PlungerPressure_B 17;
BA_ "GenSigTimeoutValue" SG_ 359 IPB_PlungerPressure_B 0;
BA_ "Remark" SG_ 359 IPB_PlungerPressure_B "";
BA_ "EventCommandSignal" SG_ 1359 CCU_NMNodeAddress 0;
BA_ "GatewayedSignals" SG_ 1359 CCU_NMNodeAddress 0;
BA_ "GenSigInactiveValue" SG_ 1359 CCU_NMNodeAddress 0;
BA_ "GenSigInvalidValue" SG_ 1359 CCU_NMNodeAddress 0;
BA_ "GenSigSendType" SG_ 1359 CCU_NMNodeAddress 1;
BA_ "GenSigStartValue" SG_ 1359 CCU_NMNodeAddress 79;
BA_ "GenSigTimeoutValue" SG_ 1359 CCU_NMNodeAddress 0;
BA_ "Remark" SG_ 1359 CCU_NMNodeAddress "";
BA_ "EventCommandSignal" SG_ 1359 CCU_NMCBV 0;
BA_ "GatewayedSignals" SG_ 1359 CCU_NMCBV 0;
BA_ "GenSigInactiveValue" SG_ 1359 CCU_NMCBV 0;
BA_ "GenSigInvalidValue" SG_ 1359 CCU_NMCBV 0;
BA_ "GenSigSendType" SG_ 1359 CCU_NMCBV 1;
BA_ "GenSigStartValue" SG_ 1359 CCU_NMCBV 0;
BA_ "GenSigTimeoutValue" SG_ 1359 CCU_NMCBV 0;
BA_ "Remark" SG_ 1359 CCU_NMCBV "";
BA_ "EventCommandSignal" SG_ 1359 CCU_NMWakeupOrigin 0;
BA_ "GatewayedSignals" SG_ 1359 CCU_NMWakeupOrigin 0;
BA_ "GenSigInactiveValue" SG_ 1359 CCU_NMWakeupOrigin 0;
BA_ "GenSigInvalidValue" SG_ 1359 CCU_NMWakeupOrigin 0;
BA_ "GenSigSendType" SG_ 1359 CCU_NMWakeupOrigin 1;
BA_ "GenSigStartValue" SG_ 1359 CCU_NMWakeupOrigin 0;
BA_ "GenSigTimeoutValue" SG_ 1359 CCU_NMWakeupOrigin 0;
BA_ "Remark" SG_ 1359 CCU_NMWakeupOrigin "";
BA_ "EventCommandSignal" SG_ 1359 CCU_PNCInformation0 0;
BA_ "GatewayedSignals" SG_ 1359 CCU_PNCInformation0 0;
BA_ "GenSigInactiveValue" SG_ 1359 CCU_PNCInformation0 0;
BA_ "GenSigInvalidValue" SG_ 1359 CCU_PNCInformation0 0;
BA_ "GenSigSendType" SG_ 1359 CCU_PNCInformation0 1;
BA_ "GenSigStartValue" SG_ 1359 CCU_PNCInformation0 0;
BA_ "GenSigTimeoutValue" SG_ 1359 CCU_PNCInformation0 0;
BA_ "Remark" SG_ 1359 CCU_PNCInformation0 "";
BA_ "EventCommandSignal" SG_ 1359 CCU_PNCInformation1 0;
BA_ "GatewayedSignals" SG_ 1359 CCU_PNCInformation1 0;
BA_ "GenSigInactiveValue" SG_ 1359 CCU_PNCInformation1 0;
BA_ "GenSigInvalidValue" SG_ 1359 CCU_PNCInformation1 0;
BA_ "GenSigSendType" SG_ 1359 CCU_PNCInformation1 1;
BA_ "GenSigStartValue" SG_ 1359 CCU_PNCInformation1 0;
BA_ "GenSigTimeoutValue" SG_ 1359 CCU_PNCInformation1 0;
BA_ "Remark" SG_ 1359 CCU_PNCInformation1 "";
BA_ "EventCommandSignal" SG_ 1359 CCU_PNCInformation2 0;
BA_ "GatewayedSignals" SG_ 1359 CCU_PNCInformation2 0;
BA_ "GenSigInactiveValue" SG_ 1359 CCU_PNCInformation2 0;
BA_ "GenSigInvalidValue" SG_ 1359 CCU_PNCInformation2 0;
BA_ "GenSigSendType" SG_ 1359 CCU_PNCInformation2 1;
BA_ "GenSigStartValue" SG_ 1359 CCU_PNCInformation2 0;
BA_ "GenSigTimeoutValue" SG_ 1359 CCU_PNCInformation2 0;
BA_ "Remark" SG_ 1359 CCU_PNCInformation2 "";
BA_ "EventCommandSignal" SG_ 1290 IDU_NMNodeAddress 0;
BA_ "GatewayedSignals" SG_ 1290 IDU_NMNodeAddress 0;
BA_ "GenSigInactiveValue" SG_ 1290 IDU_NMNodeAddress 0;
BA_ "GenSigInvalidValue" SG_ 1290 IDU_NMNodeAddress 0;
BA_ "GenSigSendType" SG_ 1290 IDU_NMNodeAddress 1;
BA_ "GenSigStartValue" SG_ 1290 IDU_NMNodeAddress 10;
BA_ "GenSigTimeoutValue" SG_ 1290 IDU_NMNodeAddress 0;
BA_ "Remark" SG_ 1290 IDU_NMNodeAddress "";
BA_ "EventCommandSignal" SG_ 1290 IDU_NMCBV 0;
BA_ "GatewayedSignals" SG_ 1290 IDU_NMCBV 0;
BA_ "GenSigInactiveValue" SG_ 1290 IDU_NMCBV 0;
BA_ "GenSigInvalidValue" SG_ 1290 IDU_NMCBV 0;
BA_ "GenSigSendType" SG_ 1290 IDU_NMCBV 1;
BA_ "GenSigStartValue" SG_ 1290 IDU_NMCBV 0;
BA_ "GenSigTimeoutValue" SG_ 1290 IDU_NMCBV 0;
BA_ "Remark" SG_ 1290 IDU_NMCBV "";
BA_ "EventCommandSignal" SG_ 1290 IDU_NMWakeupOrigin 0;
BA_ "GatewayedSignals" SG_ 1290 IDU_NMWakeupOrigin 0;
BA_ "GenSigInactiveValue" SG_ 1290 IDU_NMWakeupOrigin 0;
BA_ "GenSigInvalidValue" SG_ 1290 IDU_NMWakeupOrigin 0;
BA_ "GenSigSendType" SG_ 1290 IDU_NMWakeupOrigin 1;
BA_ "GenSigStartValue" SG_ 1290 IDU_NMWakeupOrigin 0;
BA_ "GenSigTimeoutValue" SG_ 1290 IDU_NMWakeupOrigin 0;
BA_ "Remark" SG_ 1290 IDU_NMWakeupOrigin "";
BA_ "EventCommandSignal" SG_ 1290 IDU_PNCInformation0 0;
BA_ "GatewayedSignals" SG_ 1290 IDU_PNCInformation0 0;
BA_ "GenSigInactiveValue" SG_ 1290 IDU_PNCInformation0 0;
BA_ "GenSigInvalidValue" SG_ 1290 IDU_PNCInformation0 0;
BA_ "GenSigSendType" SG_ 1290 IDU_PNCInformation0 1;
BA_ "GenSigStartValue" SG_ 1290 IDU_PNCInformation0 0;
BA_ "GenSigTimeoutValue" SG_ 1290 IDU_PNCInformation0 0;
BA_ "Remark" SG_ 1290 IDU_PNCInformation0 "";
BA_ "EventCommandSignal" SG_ 1290 IDU_PNCInformation1 0;
BA_ "GatewayedSignals" SG_ 1290 IDU_PNCInformation1 0;
BA_ "GenSigInactiveValue" SG_ 1290 IDU_PNCInformation1 0;
BA_ "GenSigInvalidValue" SG_ 1290 IDU_PNCInformation1 0;
BA_ "GenSigSendType" SG_ 1290 IDU_PNCInformation1 1;
BA_ "GenSigStartValue" SG_ 1290 IDU_PNCInformation1 0;
BA_ "GenSigTimeoutValue" SG_ 1290 IDU_PNCInformation1 0;
BA_ "Remark" SG_ 1290 IDU_PNCInformation1 "";
BA_ "EventCommandSignal" SG_ 1290 IDU_PNCInformation2 0;
BA_ "GatewayedSignals" SG_ 1290 IDU_PNCInformation2 0;
BA_ "GenSigInactiveValue" SG_ 1290 IDU_PNCInformation2 0;
BA_ "GenSigInvalidValue" SG_ 1290 IDU_PNCInformation2 0;
BA_ "GenSigSendType" SG_ 1290 IDU_PNCInformation2 1;
BA_ "GenSigStartValue" SG_ 1290 IDU_PNCInformation2 0;
BA_ "GenSigTimeoutValue" SG_ 1290 IDU_PNCInformation2 0;
BA_ "Remark" SG_ 1290 IDU_PNCInformation2 "";
BA_ "EventCommandSignal" SG_ 1294 ADC_NMNodeAddress 0;
BA_ "GatewayedSignals" SG_ 1294 ADC_NMNodeAddress 0;
BA_ "GenSigInactiveValue" SG_ 1294 ADC_NMNodeAddress 0;
BA_ "GenSigInvalidValue" SG_ 1294 ADC_NMNodeAddress 0;
BA_ "GenSigSendType" SG_ 1294 ADC_NMNodeAddress 1;
BA_ "GenSigStartValue" SG_ 1294 ADC_NMNodeAddress 14;
BA_ "GenSigTimeoutValue" SG_ 1294 ADC_NMNodeAddress 0;
BA_ "Remark" SG_ 1294 ADC_NMNodeAddress "";
BA_ "EventCommandSignal" SG_ 1294 ADC_NMCBV 0;
BA_ "GatewayedSignals" SG_ 1294 ADC_NMCBV 0;
BA_ "GenSigInactiveValue" SG_ 1294 ADC_NMCBV 0;
BA_ "GenSigInvalidValue" SG_ 1294 ADC_NMCBV 0;
BA_ "GenSigSendType" SG_ 1294 ADC_NMCBV 1;
BA_ "GenSigStartValue" SG_ 1294 ADC_NMCBV 0;
BA_ "GenSigTimeoutValue" SG_ 1294 ADC_NMCBV 0;
BA_ "Remark" SG_ 1294 ADC_NMCBV "";
BA_ "EventCommandSignal" SG_ 1294 ADC_NMWakeupOrigin 0;
BA_ "GatewayedSignals" SG_ 1294 ADC_NMWakeupOrigin 0;
BA_ "GenSigInactiveValue" SG_ 1294 ADC_NMWakeupOrigin 0;
BA_ "GenSigInvalidValue" SG_ 1294 ADC_NMWakeupOrigin 0;
BA_ "GenSigSendType" SG_ 1294 ADC_NMWakeupOrigin 1;
BA_ "GenSigStartValue" SG_ 1294 ADC_NMWakeupOrigin 0;
BA_ "GenSigTimeoutValue" SG_ 1294 ADC_NMWakeupOrigin 0;
BA_ "Remark" SG_ 1294 ADC_NMWakeupOrigin "";
BA_ "EventCommandSignal" SG_ 1294 ADC_PNCInformation0 0;
BA_ "GatewayedSignals" SG_ 1294 ADC_PNCInformation0 0;
BA_ "GenSigInactiveValue" SG_ 1294 ADC_PNCInformation0 0;
BA_ "GenSigInvalidValue" SG_ 1294 ADC_PNCInformation0 0;
BA_ "GenSigSendType" SG_ 1294 ADC_PNCInformation0 1;
BA_ "GenSigStartValue" SG_ 1294 ADC_PNCInformation0 0;
BA_ "GenSigTimeoutValue" SG_ 1294 ADC_PNCInformation0 0;
BA_ "Remark" SG_ 1294 ADC_PNCInformation0 "";
BA_ "EventCommandSignal" SG_ 1294 ADC_PNCInformation1 0;
BA_ "GatewayedSignals" SG_ 1294 ADC_PNCInformation1 0;
BA_ "GenSigInactiveValue" SG_ 1294 ADC_PNCInformation1 0;
BA_ "GenSigInvalidValue" SG_ 1294 ADC_PNCInformation1 0;
BA_ "GenSigSendType" SG_ 1294 ADC_PNCInformation1 1;
BA_ "GenSigStartValue" SG_ 1294 ADC_PNCInformation1 0;
BA_ "GenSigTimeoutValue" SG_ 1294 ADC_PNCInformation1 0;
BA_ "Remark" SG_ 1294 ADC_PNCInformation1 "";
BA_ "EventCommandSignal" SG_ 1294 ADC_PNCInformation2 0;
BA_ "GatewayedSignals" SG_ 1294 ADC_PNCInformation2 0;
BA_ "GenSigInactiveValue" SG_ 1294 ADC_PNCInformation2 0;
BA_ "GenSigInvalidValue" SG_ 1294 ADC_PNCInformation2 0;
BA_ "GenSigSendType" SG_ 1294 ADC_PNCInformation2 1;
BA_ "GenSigStartValue" SG_ 1294 ADC_PNCInformation2 0;
BA_ "GenSigTimeoutValue" SG_ 1294 ADC_PNCInformation2 0;
BA_ "Remark" SG_ 1294 ADC_PNCInformation2 "";
BA_ "EventCommandSignal" SG_ 1406 NIDU_NMNodeAddress 0;
BA_ "GatewayedSignals" SG_ 1406 NIDU_NMNodeAddress 0;
BA_ "GenSigInactiveValue" SG_ 1406 NIDU_NMNodeAddress 0;
BA_ "GenSigInvalidValue" SG_ 1406 NIDU_NMNodeAddress 0;
BA_ "GenSigSendType" SG_ 1406 NIDU_NMNodeAddress 1;
BA_ "GenSigStartValue" SG_ 1406 NIDU_NMNodeAddress 98;
BA_ "GenSigTimeoutValue" SG_ 1406 NIDU_NMNodeAddress 0;
BA_ "Remark" SG_ 1406 NIDU_NMNodeAddress "";
BA_ "EventCommandSignal" SG_ 1406 NIDU_NMCBV 0;
BA_ "GatewayedSignals" SG_ 1406 NIDU_NMCBV 0;
BA_ "GenSigInactiveValue" SG_ 1406 NIDU_NMCBV 0;
BA_ "GenSigInvalidValue" SG_ 1406 NIDU_NMCBV 0;
BA_ "GenSigSendType" SG_ 1406 NIDU_NMCBV 1;
BA_ "GenSigStartValue" SG_ 1406 NIDU_NMCBV 0;
BA_ "GenSigTimeoutValue" SG_ 1406 NIDU_NMCBV 0;
BA_ "Remark" SG_ 1406 NIDU_NMCBV "";
BA_ "EventCommandSignal" SG_ 1406 NIDU_NMWakeupOrigin 0;
BA_ "GatewayedSignals" SG_ 1406 NIDU_NMWakeupOrigin 0;
BA_ "GenSigInactiveValue" SG_ 1406 NIDU_NMWakeupOrigin 0;
BA_ "GenSigInvalidValue" SG_ 1406 NIDU_NMWakeupOrigin 0;
BA_ "GenSigSendType" SG_ 1406 NIDU_NMWakeupOrigin 1;
BA_ "GenSigStartValue" SG_ 1406 NIDU_NMWakeupOrigin 0;
BA_ "GenSigTimeoutValue" SG_ 1406 NIDU_NMWakeupOrigin 0;
BA_ "Remark" SG_ 1406 NIDU_NMWakeupOrigin "";
BA_ "EventCommandSignal" SG_ 1406 NIDU_PNCInformation0 0;
BA_ "GatewayedSignals" SG_ 1406 NIDU_PNCInformation0 0;
BA_ "GenSigInactiveValue" SG_ 1406 NIDU_PNCInformation0 0;
BA_ "GenSigInvalidValue" SG_ 1406 NIDU_PNCInformation0 0;
BA_ "GenSigSendType" SG_ 1406 NIDU_PNCInformation0 1;
BA_ "GenSigStartValue" SG_ 1406 NIDU_PNCInformation0 0;
BA_ "GenSigTimeoutValue" SG_ 1406 NIDU_PNCInformation0 0;
BA_ "Remark" SG_ 1406 NIDU_PNCInformation0 "";
BA_ "EventCommandSignal" SG_ 1406 NIDU_PNCInformation1 0;
BA_ "GatewayedSignals" SG_ 1406 NIDU_PNCInformation1 0;
BA_ "GenSigInactiveValue" SG_ 1406 NIDU_PNCInformation1 0;
BA_ "GenSigInvalidValue" SG_ 1406 NIDU_PNCInformation1 0;
BA_ "GenSigSendType" SG_ 1406 NIDU_PNCInformation1 1;
BA_ "GenSigStartValue" SG_ 1406 NIDU_PNCInformation1 0;
BA_ "GenSigTimeoutValue" SG_ 1406 NIDU_PNCInformation1 0;
BA_ "Remark" SG_ 1406 NIDU_PNCInformation1 "";
BA_ "EventCommandSignal" SG_ 1406 NIDU_PNCInformation2 0;
BA_ "GatewayedSignals" SG_ 1406 NIDU_PNCInformation2 0;
BA_ "GenSigInactiveValue" SG_ 1406 NIDU_PNCInformation2 0;
BA_ "GenSigInvalidValue" SG_ 1406 NIDU_PNCInformation2 0;
BA_ "GenSigSendType" SG_ 1406 NIDU_PNCInformation2 1;
BA_ "GenSigStartValue" SG_ 1406 NIDU_PNCInformation2 0;
BA_ "GenSigTimeoutValue" SG_ 1406 NIDU_PNCInformation2 0;
BA_ "Remark" SG_ 1406 NIDU_PNCInformation2 "";
BA_ "EventCommandSignal" SG_ 2015 Fun_Diag_Request 0;
BA_ "GatewayedSignals" SG_ 2015 Fun_Diag_Request 0;
BA_ "GenSigInactiveValue" SG_ 2015 Fun_Diag_Request 0;
BA_ "GenSigInvalidValue" SG_ 2015 Fun_Diag_Request 0;
BA_ "GenSigSendType" SG_ 2015 Fun_Diag_Request 1;
BA_ "GenSigStartValue" SG_ 2015 Fun_Diag_Request 0;
BA_ "GenSigTimeoutValue" SG_ 2015 Fun_Diag_Request 0;
BA_ "Remark" SG_ 2015 Fun_Diag_Request "";
VAL_ 371 ADC_SteerTqSt 0 "No request" 1 "Ready" 2 "Active" 3 "Reserved"  ;
VAL_ 371 ADC_SteerTqAvl 0 "Not available" 1 "Available"  ;
VAL_ 371 ADC_DycEscTarTqVld 0 "Invalid" 1 "Valid"  ;
VAL_ 371 ADC_DycEscTarTqEna 0 "disable" 1 "enable"  ;
VAL_ 371 ADC_MotCtrlTar 0 "FL" 1 "RL" 2 "FL+RL" 3 "RL+RR" 4 "reserved" 5 "reserved" 6 "reserved" 7 "reserved"  ;
VAL_ 371 ADC_MotTarMod 0 "Torque mode" 1 "Speed mode" 2 "SV mode" 3 "Reserved"  ;
VAL_ 371 ADC_DrvTarTqMod 0 "Override mode" 1 "Inhibit mode" 2 "reserved" 3 "reserved"  ;
VAL_ 371 ADC_TqEvsSteerReq 0 "Normal" 1 "Emergency"  ;
VAL_ 371 ADC_RapidRespEna 0 "Disable" 1 "Enable"  ;
VAL_ 371 ADC_LimTqEnable 0 "Disable" 1 "Enable"  ;
VAL_ 371 ADC_MotSpdCtrlEna 0 "Disable" 1 "Enable"  ;
VAL_ 371 ADC_TqUnloadEna 0 "Disable" 1 "Enable"  ;
VAL_ 371 ADC_MotTarSpdSvValid 0 "Invalid" 1 "Valid"  ;
VAL_ 371 ADC_RoadTyp 0 "Flat road" 1 "Bumpy road" 2 "Gravel road" 3 "Reserved" 4 "Reserved" 5 "Reserved" 6 "Reserved" 7 "Invalid"  ;
VAL_ 371 ADC_RiWhlRoadFeature 0 "No Object" 1 "Speed Bump" 2 "Manhole cover" 3 "High-speed vibration zone" 4 "Continuous Speed Bumps" 5 "Bridge joint" 6 "Cement joint" 7 "Pit" 8 "Others" 15 "Invalid"  ;
VAL_ 371 ADC_SuspensionStatus 0 "No request" 1 "Auto_Disable" 2 "Manual_Disable" 3 "Disable" 4 "Reserved" 5 "Reserved" 6 "Reserved" 7 "Reserved"  ;
VAL_ 371 ADC_LeWhlRoadSts 0 "Unknown" 1 "flat" 2 "concave" 3 "convex"  ;
VAL_ 371 ADC_LeWhlRoadFeature 0 "No Object" 1 "Speed Bump" 2 "Manhole cover" 3 "High-speed vibration zone" 4 "Continuous Speed Bumps" 5 "Bridge joint" 6 "Cement joint" 7 "Pit" 8 "Others" 15 "Invalid"  ;
VAL_ 371 ADC_RiWhlRoadSts 0 "Unknown" 1 "flat" 2 "concave" 3 "convex"  ;
VAL_ 371 ADC_CDCCtrlEnable 0 "disable" 1 "enable"  ;
VAL_ 371 ADC_RoadInfoAvl 0 "Not Available" 1 "Available"  ;
VAL_ 371 ADC_RoadFeatureDetFalutSts 0 "No error" 1 "Error"  ;
VAL_ 371 ADC_RoadFeatureDetWorkSts 0 "Invalid" 1 "Valid" 2 "Inhibit" 3 "Reserve"  ;
VAL_ 371 ADC_LeWhlRoadFeature2 0 "No Object" 1 "Speed Bump" 2 "Manhole cover" 3 "High-speed vibration zone" 4 "Continuous Speed Bumps" 5 "Bridge joint" 6 "Cement joint" 7 "Pit" 8 "Others" 15 "Invalid"  ;
VAL_ 371 ADC_LeWhlRoadFeature3 0 "No Object" 1 "Speed Bump" 2 "Manhole cover" 3 "High-speed vibration zone" 4 "Continuous Speed Bumps" 5 "Bridge joint" 6 "Cement joint" 7 "Pit" 8 "Others" 15 "Invalid"  ;
VAL_ 371 ADC_RiWhlRoadFeature2 0 "No Object" 1 "Speed Bump" 2 "Manhole cover" 3 "High-speed vibration zone" 4 "Continuous Speed Bumps" 5 "Bridge joint" 6 "Cement joint" 7 "Pit" 8 "Others" 15 "Invalid"  ;
VAL_ 371 ADC_RiWhlRoadFeature3 0 "No Object" 1 "Speed Bump" 2 "Manhole cover" 3 "High-speed vibration zone" 4 "Continuous Speed Bumps" 5 "Bridge joint" 6 "Cement joint" 7 "Pit" 8 "Others" 15 "Invalid"  ;
VAL_ 371 ADC_LeWhlRoadHei2 0 "Default" 1 "<-10cm" 2 "-10~-5cm" 3 "-5~0cm" 4 "0~5cm" 5 "5~10cm" 6 "＞10cm" 7 "Invalid"  ;
VAL_ 371 ADC_LeWhlRoadHei3 0 "Default" 1 "<-10cm" 2 "-10~-5cm" 3 "-5~0cm" 4 "0~5cm" 5 "5~10cm" 6 "＞10cm" 7 "Invalid"  ;
VAL_ 371 ADC_RiWhlRoadHei2 0 "Default" 1 "<-10cm" 2 "-10~-5cm" 3 "-5~0cm" 4 "0~5cm" 5 "5~10cm" 6 "＞10cm" 7 "Invalid"  ;
VAL_ 371 ADC_RiWhlRoadHei3 0 "Default" 1 "<-10cm" 2 "-10~-5cm" 3 "-5~0cm" 4 "0~5cm" 5 "5~10cm" 6 "＞10cm" 7 "Invalid"  ;
VAL_ 371 ADC_LeWhlLgtDst2 63 "Invalid"  ;
VAL_ 371 ADC_LeWhlLgtDst3 63 "Invalid"  ;
VAL_ 371 ADC_RiWhlLgtDst2 63 "Invalid"  ;
VAL_ 371 ADC_RiWhlLgtDst3 63 "Invalid"  ;
VAL_ 371 ADC_AS_SuspHeiAdj 0 "Invalid" 1 "PAS Request to Very high level" 2 "PAS Request to High level" 3 "PAS Request to Normal level" 4 "PAS Request to Low level" 5 "PAS Request to Very low level" 6 "Reserve" 7 "Reserve"  ;
VAL_ 371 ADC_AS_SuspHeiAdjVld 0 "Invalid" 1 "Valid"  ;
VAL_ 371 ADC_AS_SusStfnAdj 0 "No request" 1 "Soft" 2 "Hard"  ;
VAL_ 371 ADC_AS_SusStfnAdjVld 0 "Invalid" 1 "Valid"  ;
VAL_ 371 ADC_CDCModReq 0 "No request" 1 "comfort（low）" 2 "comfort（middle）" 3 "comfort（high）" 4 "sport（low）" 5 "sport（middle）" 6 "sport（high）" 7 "reserve"  ;
VAL_ 371 ADC_CDCModReqVld 0 "Invalid" 1 "Valid"  ;
VAL_ 371 ADC_UrgentSteerFlg 0 "Disable" 1 "Enable"  ;
VAL_ 371 ADC_OneMotorCtrlEna 0 "Disable（Total Drive Torque）" 1 "Enable（One Wheel Drive Torque）" 2 "Reserved" 3 "Reserved"  ;
VAL_ 422 VCU_AccButtInfo_B 0 "not press" 1 "press" 0 "not press" 1 "press" 0 "not press" 1 "press" 0 "not press" 1 "press" 0 "not press" 1 "press" 0 "Normal" 1 "Abnormal"  ;
VAL_ 422 VCU_LateralAssistBtnInfo_B 0 "Not pressed" 1 "Pressed"  ;
VAL_ 422 VCU_LateralAssistBtnInfoVD_B 0 "Invalid" 1 "Valid"  ;
VAL_ 422 VCU_AccMasterCanError_B 0 "No Error" 1 "Error"  ;
VAL_ 422 VCU_IFCFailureSt_B 0 "Not Failure" 1 "Failure"  ;
VAL_ 422 VCU_VehDrvMod_B 0 "Invalid" 1 "ECO+ Mode" 2 "ECO Mode" 3 "Normal Mode" 4 "Driving Mode" 5 "SPORT Mode" 6 "I-pedal Mode" 7 "Crazy Mode"  ;
VAL_ 422 VCU_VehRdySt_B 0 "Not ready" 1 "Ready"  ;
VAL_ 422 VCU_GearLvl_B 0 "Invalid" 1 "'D' Drive gear" 2 "'N' Neutral gear" 3 "'R' Reverse gear" 4 "'P' Park gear" 5 "Not used" 6 "Not used" 7 "Not used" 8 "Not used" 9 "Not used" 10 "Not used" 11 "Not used" 12 "Not used" 13 "Not used" 14 "Not used" 15 "Not used"  ;
VAL_ 422 VCU_RecpTorqVD_B 0 "Not valid" 1 "Valid"  ;
VAL_ 422 VCU_BrkPedPstVD_B 0 "Not valid" 1 "Valid"  ;
VAL_ 422 VCU_CrntGearLvlVD_B 0 "Not valid" 1 "Valid"  ;
VAL_ 422 VCU_CrntGearLvl_B 0 "Invalid" 1 "'D' Drive gear" 2 "'N' Neutral gear" 3 "'R' Reverse gear" 4 "'P' Park gear" 5 "Not used" 6 "Not used" 7 "Not used"  ;
VAL_ 422 VCU_ACCLimitOperatingSt_B 0 "Not active" 1 "active"  ;
VAL_ 422 VCU_ACCMaxRecpDecelVD_B 0 "Not valid" 1 "Valid"  ;
VAL_ 422 VCU_ACCmaxSpdLimit_B 0 "No Limit" 1 "10 Km/h" 2 "20 Km/h" 3 "30 Km/h" 4 "40 Km/h" 5 "50 Km/h" 6 "60 Km/h" 7 "70 Km/h" 8 "80 Km/h" 9 "90 Km/h" 10 "100 Km/h" 11 "110 Km/h" 12 "120 Km/h" 13 "130 Km/h" 14 "140 Km/h" 15 "Reserved"  ;
VAL_ 422 VCU_GasPedalActPstforMRRVD_B 0 "Invalid" 1 "Valid"  ;
VAL_ 422 VCU_AccElecECFail_B 0 "No failure" 1 "Failure"  ;
VAL_ 422 VCU_AccDriverOrvd_B 0 "No override" 1 "Driver override"  ;
VAL_ 422 VCU_APAAvailable_B 1 "Available;" 0 "Not available;"  ;
VAL_ 422 VCU_APA_Resp_B 1 "Yes;" 0 "No;"  ;
VAL_ 422 VCU_BrkPedalSt_B 0 "Not pressed" 1 "Pressed"  ;
VAL_ 422 VCU_BrkPedalStVD_B 0 "Not valid" 1 "Valid"  ;
VAL_ 422 VCU_AccPedalActPstVD_B 0 "Not valid" 1 "Valid"  ;
VAL_ 422 VCU_AccTMCFail_B 0 "Normal mode" 1 "In limp-home mode"  ;
VAL_ 619 EPB_FailSt_L 0 "No error" 1 "Error"  ;
VAL_ 619 EPB_ExtAvailable_L 0 "Apply and release" 1 "Only apply" 2 "Only release" 3 "None"  ;
VAL_ 619 EPB_ActuatorSt_L 0 "PbcActuatorState_Applied" 1 "PbcActuatorState_Released" 2 "PbcActuatorState_Applying" 3 "PbcActuatorState_Releasing" 4 "PbcActuatorState_Unknown" 5 "PbcActuatorState_HoldApplied" 6 "PbcActuatorState_CompletelyReleased" 7 "Not used" 8 "Not used" 9 "Not used" 10 "Not used" 11 "Not used" 12 "Not used" 13 "Not used" 14 "Not used" 15 "Not used"  ;
VAL_ 728 SDC_SolenoidErrorStRR 0 "No error" 1 "Circuit short" 2 "Circuit open" 3 "Reserved"  ;
VAL_ 728 CDC_ADCCtrlAvl 0 "Not available" 1 "Available"  ;
VAL_ 728 CDC_ADCCtrlRespSts 0 "No active" 1 "Active"  ;
VAL_ 728 SDC_ExternalReqMode 0 "Inactive" 1 "Comfort" 2 "Normal" 3 "Sport" 4 "Sport+"  ;
VAL_ 728 SDC_CurrentDamperMode 0 "Invalid" 1 "Comfort" 2 "Normal" 3 "Sport" 4 "Sport+"  ;
VAL_ 728 SDC_WarningLampReq 0 "Off" 1 "On"  ;
VAL_ 728 SDC_ProhibitChangingMode 0 "Not prohibit" 1 "Prohibit"  ;
VAL_ 728 SDC_BodyAccErrorStFL 0 "No error" 1 "Error"  ;
VAL_ 728 SDC_BodyAccErrorStFR 0 "No error" 1 "Error"  ;
VAL_ 728 SDC_BodyAccErrorStRr 0 "No error" 1 "Error"  ;
VAL_ 728 SDC_WheelAccErrorStFL 0 "No error" 1 "Error"  ;
VAL_ 728 SDC_WheelAccErrorStFR 0 "No error" 1 "Error"  ;
VAL_ 728 SDC_SolenoidWorkSt 0 "Solenoid is not working" 1 "Solenoid is working" 2 "Reserved" 3 "Reserved"  ;
VAL_ 728 CDC_ADCModState 0 "Initializing" 1 "comfort（low）" 2 "comfort（middle）" 3 "comfort（high）" 4 "sport（low）" 5 "sport（middle）" 6 "sport（high）" 7 "reserve"  ;
VAL_ 459 AS_SuspHeightFLVD 0 "Invalid" 1 "Valid"  ;
VAL_ 459 AS_SuspHeightFRVD 0 "Invalid" 1 "Valid"  ;
VAL_ 459 AS_SuspHeightRLVD 0 "Invalid" 1 "Valid"  ;
VAL_ 459 AS_SuspHeightRRVD 0 "Invalid" 1 "Valid"  ;
VAL_ 459 AS_SuspHeightSensorFLSt 0 "No fault" 1 "Fault"  ;
VAL_ 459 AS_SuspHeightSensorFRSt 0 "No fault" 1 "Fault"  ;
VAL_ 459 AS_SuspHeightSensorRLSt 0 "No fault" 1 "Fault"  ;
VAL_ 459 AS_SuspHeightSensoRRSt 0 "No fault" 1 "Fault"  ;
VAL_ 459 AS_MaintanceModeSt 0 "Disabled" 1 "Inactive" 2 "User activation" 3 "Automatically  activation"  ;
VAL_ 459 ECS_AVDCReqModeAvailable 0 "not available" 1 "available"  ;
VAL_ 459 ECS_AVDCReqMode 0 "inactive" 1 "Small Control" 2 "Middle Control(reserved)" 3 "Big Control"  ;
VAL_ 459 AS_FrontAxleSuspSt 0 "Standby" 1 "Up" 2 "Down" 3 "Reserved"  ;
VAL_ 459 AS_RearAxleSuspSt 0 "Standby" 1 "Up" 2 "Down" 3 "Reserved"  ;
VAL_ 459 AS_HeightWarningSt 0 "Initializing" 1 "Normal" 2 "Too High" 3 "Too Low" 4 "Invalid"  ;
VAL_ 459 AS_CurrentLevel 0 "Invalid" 1 "Very high level" 2 "Between very high and high level" 3 "High level" 4 "Between high and normal level" 5 "Normal level" 6 "Between normal and low level" 7 "Low level" 8 "Between low and very low level" 9 "Very low level" 10 "Between previous level to easy-loading level" 11 "Easy-loading  level" 12 "Between previous level to showrom level" 13 "Showrom level" 14 "Reserved" 15 "Reserved"  ;
VAL_ 459 AS_TargetLevel 0 "No requirement" 1 "Very high level" 2 "High level" 3 "Normal level" 4 "Low level" 5 "Very low level" 6 "Easy-loading  level" 7 "Showrom level" 8 "Reserved" 9 "Reserved" 10 "Reserved" 11 "Reserved" 12 "Reserved" 13 "Reserved" 14 "Reserved" 15 "Reserved"  ;
VAL_ 459 AS_ASMode 0 "Invalid" 1 "Very high base level (not used)" 2 "High level" 3 "Normal level" 4 "Low level" 5 "Very low  base level (not used)" 6 "Reserved" 7 "Reserved"  ;
VAL_ 459 AS_SysFaultSt 0 "No error" 1 "Fault Level1 (minor)" 2 "Fault Level 2 (seriously)" 3 "Fault Level 3 (Very seriously)" 4 "Reserved" 5 "Reserved" 6 "Reserved" 7 "Reserved"  ;
VAL_ 459 AS_OverHeatingSt 0 "No overheating" 1 "Overheating without notice (except 2)" 2 "Overheating with notice" 3 "Reserved"  ;
VAL_ 459 AS_SysOperationSt 0 "Invalid" 1 "Lifting" 2 "Lowering" 3 "Holding (current level" 4 "Prohibit adjusting (sub-function or external request prohibit adjusting or low pressure)" 5 "Shut down (overheating without enough pressure and system fault)" 6 "Easy-loading adjusting" 7 "Showrom adjusting" 8 "Reserved" 9 "Reserved" 10 "Reserved" 11 "Reserved" 12 "Reserved" 13 "Reserved" 14 "Reserved" 15 "Reserved"  ;
VAL_ 459 AS_OverLoadSt 0 "No overload" 1 "Overload"  ;
VAL_ 459 AS_OverTorsionSt 0 "No over torsion" 1 "Over torsion"  ;
VAL_ 459 AS_ManufacModeSt 0 "Disabled" 1 "Inactive" 2 "Active" 3 "Reserved"  ;
VAL_ 459 AS_ASIndividualMode 0 "Invalid" 1 "Very high base level (not used)" 2 "High level" 3 "Normal level" 4 "Low level" 5 "Very low  base level (not used)" 6 "Reserved" 7 "Reserved"  ;
VAL_ 459 AS_ADCStfnCtrlAvl 0 "Not available" 1 "Available"  ;
VAL_ 459 AS_ADCStfnState 0 "Initializing" 1 "Soft" 2 "Hard"  ;
VAL_ 359 BCS_FLWheelSpdVD_B 0 "Not valid" 1 "Valid"  ;
VAL_ 359 BCS_FLWheelRotatedDirection_B 0 "Forward" 1 "Backward"  ;
VAL_ 359 BCS_FLWheelRotatedDirectionVD_B 0 "Not valid" 1 "Valid"  ;
VAL_ 359 BCS_FRWheelSpdVD_B 0 "Not valid" 1 "Valid"  ;
VAL_ 359 BCS_FRWheelRotatedDirection_B 0 "Forward" 1 "Backward"  ;
VAL_ 359 BCS_FRWheelRotatedDirectionVD_B 0 "Not valid" 1 "Valid"  ;
VAL_ 359 BCS_RLWheelSpdVD_B 0 "Not valid" 1 "Valid"  ;
VAL_ 359 BCS_RLWheelRotatedDirection_B 0 "Forward" 1 "Backward"  ;
VAL_ 359 BCS_RLWheelRotatedDirectionVD_B 0 "Not valid" 1 "Valid"  ;
VAL_ 359 BCS_RRWheelSpdVD_B 0 "Not valid" 1 "Valid"  ;
VAL_ 359 BCS_RRWheelRotatedDirection_B 0 "Forward" 1 "Backward"  ;
VAL_ 359 BCS_RRWheelRotatedDirectionVD_B 0 "Not valid" 1 "Valid"  ;
VAL_ 359 BCS_HHCCtrlSt_B 0 "Not active" 1 "Active"  ;
VAL_ 359 BCS_HDCCtrlSt_B 0 "Off" 1 "On active braking" 2 "On not active braking" 3 "Not used"  ;
VAL_ 359 BCS_HDCErrSt_B 0 "No error" 1 "Error"  ;
VAL_ 359 BCS_FLWheelSpdEdgesSumVD_B 0 "Not valid" 1 "Valid"  ;
VAL_ 359 BCS_FRWheelSpdEdgesSumVD_B 0 "Not valid" 1 "Valid"  ;
VAL_ 359 BCS_RLWheelSpdEdgesSumVD_B 0 "Not valid" 1 "Valid"  ;
VAL_ 359 BCS_RRWheelSpdEdgesSumVD_B 0 "Not valid" 1 "Valid"  ;
VAL_ 359 BCS_FLWheelRotatedDirectionAPA_B 0 "Standstill" 1 "Forward" 2 "Backward" 3 "Unknown"  ;
VAL_ 359 BCS_FRWheelRotatedDirectionAPA_B 0 "Standstill" 1 "Forward" 2 "Backward" 3 "Unknown"  ;
VAL_ 359 BCS_RLWheelRotatedDirectionAPA_B 0 "Standstill" 1 "Forward" 2 "Backward" 3 "Unknown"  ;
VAL_ 359 BCS_RRWheelRotatedDirectionAPA_B 0 "Standstill" 1 "Forward" 2 "Backward" 3 "Unknown"  ;
VAL_ 359 BCS_ParkingReqToEPB_B 0 "No request" 1 "Release brake request" 2 "Lock brake request" 3 "Not used"  ;
VAL_ 359 BCS_VDCOff_B 0 "On" 1 "Off"  ;
VAL_ 359 BCS_AVHSt_B 0 "Not active" 1 "Active"  ;
VAL_ 359 BCS_AVHAvailable_B 0 "Not available" 1 "Available"  ;
VAL_ 359 BCS_TCSOff_B 0 "On" 1 "Off"  ;
VAL_ 359 BCS_BrakeOverHeat_B 0 "Not high" 1 "Temp too high"  ;
VAL_ 359 BCS_ABAactive_B 0 "Not active" 1 "Active"  ;
VAL_ 359 BCS_ABAavailable_B 0 "Not available" 1 "Available"  ;
VAL_ 359 BCS_ABPActive_B 0 "Not active" 1 "Active"  ;
VAL_ 359 BCS_ABPAvailable_B 0 "Not available" 1 "Available"  ;
VAL_ 359 BCS_AEBActive_B 0 "Not active" 1 "Active"  ;
VAL_ 359 BCS_AEBAvailable_B 0 "Not available" 1 "Available"  ;
VAL_ 359 BCS_AWBActive_B 0 "Not active" 1 "Active"  ;
VAL_ 359 BCS_AWBAvailable_B 0 "Not available" 1 "Available"  ;
VAL_ 359 BCS_AVHStandby_B 0 "Not standby" 1 "Standby"  ;
VAL_ 359 BCS_AEBBAActive_B 0 "Not active" 1 "Active"  ;
VAL_ 359 BCS_VehicleStandStillSt_B 0 "Not standstill" 1 "standstill" 2 "Invalid (short unavailability, max 3s)" 3 "Not used"  ;
VAL_ 359 IPB_PlungerPressureSt_B 0 "Valid/Init" 1 "Invalid/Default"  ;
VAL_ 359 BCS_RAEBAvailable_B 0 "Not avaialbe" 1 "Available"  ;
VAL_ 359 BCS_RAEBActive_B 0 "Not active" 1 "Active"  ;
VAL_ 359 IPB_InputRodStrokeSt_B 0 "Valid/Init" 1 "Invalid/Default"  ;
VAL_ 1359 CCU_NMCBV 0 "Node has not woken up the    network(passive wakeup);" 1 "Node has woken up the network(active wakeup)" 0 "NM PDU contains no Partial Network request information" 1 "NM PDU contains Partial Network request information"  ;
VAL_ 1359 CCU_NMWakeupOrigin 0 "Reserved" 1 "CAN channel 0" 2 "CAN channel 1" 3 "CAN channel 2" 4 "CAN channel 3" 5 "CAN channel 4" 6 "CAN channel 5" 7 "CAN channel 6" 8 "CAN channel 7" 9 "CAN channel 8" 10 "CAN channel 9" 11 "CAN channel 10" 12 "CAN channel 11" 13 "CAN channel 12" 14 "CAN channel 13" 15 "CAN channel 14" 16 "CAN channel 15" 17 "Reserved" 18 "Reserved" 19 "Reserved" 20 "AcoreRequest" 21 "Reserved" 22 "Reserved" 23 "Reserved" 24 "Reserved" 25 "Reserved" 26 "Reserved" 27 "Reserved" 28 "Reserved" 29 "Reserved" 30 "Reserved" 31 "Reserved" 32 "Reserved" 33 "Reserved" 34 "Reserved" 35 "Reserved" 36 "Reserved" 37 "Reserved" 38 "Reserved" 39 "Reserved" 40 "Reserved" 41 "Reserved" 42 "Reserved" 43 "Reserved" 44 "Reserved" 45 "Reserved" 46 "Reserved" 47 "Reserved" 48 "Reserved" 49 "Reserved" 50 "UsageModeSt" 51 "NMiDPSNMKeepAwakeFlag" 52 "NMEEMKeepAwakeFlag" 53 "NMEEMKeepAwakeFlag_Aux" 54 "NMVCUGlobalKeepAwakeFlag" 55 "NMVCUChargingKeepAwakeFlag（新能源，VCU_hcu）" 56 "DoIPActiveLineStatus" 57 "NMBMSGlobalKeepAwakeFlag" 58 "NMBMSChargingKeepAwakeFlag" 59 "NMBMSThermalRunawayKeepAwakeFlag（新能源，BMS）" 60 "Reserved" 61 "NMBMSThermalRunawayKeepAwakeFlag （动力，VCU_slccu）" 62 "NMVCUChargingKeepAwakeFlag（动力，VCU_slccu）" 63 "NMVCU2GlobalKeepAwakeFlag" 64 "NMVHMKeepAwakeFlag" 65 "Reserved" 66 "CSM_RC_KeepAwake" 67 "NMHVACKeepAwakeFlag（新能源，TMS）" 68 "Reserved" 69 "Reserved" 70 "BDC_NMBDCKeepAwakeFlag" 71 "NMTMSChargingKeepAwakeFlag" 72 "NMTMSGlobalKeepAwakeFlag" 73 "Reserved" 74 "Reserved" 75 "Reserved" 76 "Reserved" 77 "Reserved" 78 "Reserved" 79 "Reserved" 80 "Reserved" 81 "Reserved" 82 "Reserved" 83 "Reserved" 84 "Reserved" 85 "Reserved" 86 "Reserved" 87 "Reserved" 88 "Reserved" 89 "NMWCCDownloadRequest_RT1" 90 "CAN7_DiagMSG_ID ！" 91 "CAN7_DiagMSG_ID" 92 "Reserved" 93 "Reserved" 94 "Reserved" 95 "Reserved" 96 "Reserved" 97 "Reserved" 98 "Reserved" 99 "Reserved" 100 "NMATWSKeepAwakeFlag" 101 "NMExteriorLightKeepAwakeFlag" 102 "NMLockingKeepAwakeFlag" 103 "NMPWLKeepAwakeFlag" 104 "NMSunRoofKeepAwakeFlag" 105 "NMPLGKeepAwakeFlag" 106 "NMPowerOperatedDoorKeepAwakeFlag" 107 "MR_NMMirrorKeepAwakeFlag" 108 "NMSeatControlKeepAwakeFlag" 109 "NMHVACKeepAwakeFlag" 110 "NMHVACRLSLinAwakeFlag" 111 "NMAQCKeepAwakeFlag" 112 "NMTPMSKeepAwakeFlag" 113 "ILC_NMKeepAwakeFlag" 114 "NMESMKeepAwakeFlag" 115 "NMKAEKeepAwakeFlag" 116 "NMVRMPNCCharingKeepAwakeFlag" 140 "NMWCCDownloadReques_RT2"  ;
VAL_ 1359 CCU_PNCInformation0 0 "No request" 1 "Request" 0 "No request" 1 "Request" 0 "No request" 1 "Request" 0 "No request" 1 "Request" 0 "No request" 1 "Request" 0 "No request" 1 "Request" 0 "No request" 1 "Request"  ;
VAL_ 1359 CCU_PNCInformation1 0 "No request" 1 "Request" 0 "No request" 1 "Request"  ;
VAL_ 1290 IDU_NMCBV 0 "Node has not woken up the    network(passive wakeup);" 1 "Node has woken up the network(active wakeup)" 0 "NM PDU contains no Partial Network request information" 1 "NM PDU contains Partial Network request information"  ;
VAL_ 1290 IDU_NMWakeupOrigin 1 "CAN01_NM Message wakeup" 2 "CAN02_NM Message wakeup"  ;
VAL_ 1290 IDU_PNCInformation0 0 "No request" 1 "Request" 0 "No request" 1 "Request" 0 "No request" 1 "Request" 0 "No request" 1 "Request" 1 "Request" 0 "No request" 1 "Request" 0 "No request" 1 "Request"  ;
VAL_ 1290 IDU_PNCInformation1 0 "No request" 1 "Request" 0 "No request" 1 "Request"  ;
VAL_ 1294 ADC_NMCBV 0 "Node has not woken up the    network(passive wakeup);" 1 "Node has woken up the network(active wakeup)" 0 "NM PDU contains no Partial Network request information" 1 "NM PDU contains Partial Network request information"  ;
VAL_ 1294 ADC_NMWakeupOrigin 1 "NM Message wakeup" 2 "Diagnostic Message" 3 "KL15"  ;
VAL_ 1294 ADC_PNCInformation0 0 "No request" 1 "Request" 0 "No request" 1 "Request" 0 "No request" 1 "Request" 0 "No request" 1 "Request" 0 "No request" 1 "Request" 0 "No request" 1 "Request" 0 "No request" 1 "Request"  ;
VAL_ 1294 ADC_PNCInformation1 0 "No request" 1 "Request" 0 "No request" 1 "Request"  ;
VAL_ 1406 NIDU_NMCBV 0 "Node has not woken up the    network(passive wakeup);" 1 "Node has woken up the network(active wakeup)" 0 "NM PDU contains no Partial Network request information" 1 "NM PDU contains Partial Network request information"  ;
VAL_ 1406 NIDU_NMWakeupOrigin 1 "Message wakeup" 3 "EPB button" 5 "Brake pedal depressed" 18 "KL15 wakeup" 19 "CC wakeup" 20 "CP wakeup"  ;
VAL_ 1406 NIDU_PNCInformation0 0 "No request" 1 "Request" 0 "No request" 1 "Request" 0 "No request" 1 "Request" 0 "No request" 1 "Request" 0 "No request" 1 "Request" 0 "No request" 1 "Request" 0 "No request" 1 "Request"  ;
VAL_ 1406 NIDU_PNCInformation1 0 "No request" 1 "Request" 0 "No request" 1 "Request"  ;
